VERSION ""

NS_ :

BS_:

BU_: Turbocharger OnBoardDataLogger OffBoardDiagnosticTool2 OffBoardDiagnosticTool1 FileServer ParkingBrakeController SeatControl2 FanDriveController SteeringColumnUnit CommunicationUnitRadio CommunicationUnitSatellite CommunicationUnitCellular PropulsionBatteryCharger ChassisController2 ChassisController1 EngineValveControl AuxiliaryHeater2 AuxiliaryHeater1 ClutchUnit RampControl InformationSystem1 SuspensionSystemController2 OilSensor VehicleDynamicStability ExhaustEmissionController TransmissionDisplay2 TransmissionDisplay1 ClimateControl2 WaterPumpController RearAxleSteeringController LightingOperatorControl SeatController1 IgnitionController2 IgnitionController1 TirePressureController CabController2 CabController1 PneumaticSystemController SuspensionSystemController1 HydraulicPumpController EnduranceBrakingSystem RetarderExhaustEngine2 OnBoardDiagnosticUnit HeadwayController RetarderExhaustEngine1 CabDisplay1 ManagementComputer VirtualTerminal OffVehicleGateway PowerTakeOffFront HitchControl AuxiliaryValveControl BodyController TractorTrailerBridge1 StarterSystem ElectricalSystem VehicleSecurity VehicleNavigation AerodynamicControl ElectricalChargingSystem ClimateControl1 TripRecorder InstrumentCluster SuspensionDriveAxle2 SuspensionDriveAxle1 SuspensionSteerAxle SteeringController FuelSystem CruiseControl RetarderDriveline RetarderEngine BrakesDriveAxle2 BrakesDriveAxle1 BrakesSystemController BrakesSteerAxle AxleDrive2 AxleDrive1 AxleSteering PowerTakeOff ShiftConsoleSecondary ShiftConsolePrimary Transmission2 Transmission1 Engine2 Engine1

BO_ 2362179326 PD: 14 Vector__XXX
 SG_ NumberOfControlChannels m1 : 56|8@1+ (1,0) [0|255] "" Vector__XXX
 SG_ Command M : 0|4@1+ (1,0) [0|15] "" Vector__XXX
 SG_ ErrorElementNumber m13 : 4|12@1+ (1,0) [0|4095] "" Vector__XXX
 SG_ ElementNumber m2 : 4|12@1+ (1,0) [0|4095] "" Vector__XXX
 SG_ DeviceDescriptionMsgType m1M : 4|4@1+ (1,0) [0|15] "" Vector__XXX
 SG_ TechnicalDataMsgType m0M : 4|4@1+ (1,0) [0|15] "" Vector__XXX
 SG_ ErrorCodeObjPoolActiveResp1 m9 : 8|1@1+ (1,0) [0|0] "" Vector__XXX
 SG_ ObjectIdChanged m13 : 8|16@1+ (1,0) [0|65535] "" Vector__XXX
 SG_ ObjectIdToChange m12 : 8|16@1+ (1,0) [0|65535] "" Vector__XXX
 SG_ ErrorCodeObjectPoolDelete m11 : 8|8@1+ (1,0) [0|0] "" Vector__XXX
 SG_ ActivateDeactivateCommand m8 : 8|8@1+ (1,0) [0|255] "" Vector__XXX
 SG_ ErrorCodeObjPoolTransfer m7 : 8|8@1+ (1,0) [0|3] "" Vector__XXX
 SG_ Status m5 : 8|8@1+ (1,0) [0|1] "" Vector__XXX
 SG_ RequestTransferDataSize m4 : 8|32@1+ (1,0) [0|4294967295] "bytes" Vector__XXX
 SG_ VersionNumberISO11783Part10 m1 : 8|8@1- (1,0) [0|255] "" Vector__XXX
 SG_ StructureLabel m0 : 8|56@1+ (1,0) [0|0] "" Vector__XXX
 SG_ ErrorCodeObjPoolActiveResp2 m9 : 9|1@1+ (1,0) [0|0] "" Vector__XXX
 SG_ ErrorCodeObjPoolActiveResp3 m9 : 10|1@1+ (1,0) [0|0] "" Vector__XXX
 SG_ LanguageCodeCmd m3 : 15|16@0+ (1,0) [0|16383] "" Vector__XXX
 SG_ PeerControlDDI m9 : 16|16@1+ (1,0) [0|65535] "" Vector__XXX
 SG_ BootTimeTC m1 : 16|8@1+ (1,0) [0|255] "s" Vector__XXX
 SG_ DDI m2M : 16|16@1+ (1,0) [0|65535] "" Vector__XXX
 SG_ ReceivedDataSize m7 : 16|32@1+ (1,0) [0|4294967295] "bytes" Vector__XXX
 SG_ ParentObjectIdOfFaultyObject m9 : 16|16@1+ (1,0) [0|65535] "" Vector__XXX
 SG_ ErrorDDI m13 : 16|16@1+ (1,0) [0|65535] "" Vector__XXX
 SG_ DDI_DI m5 : 16|16@1+ (1,0) [0|65535] "" Vector__XXX
 SG_ DDI_TI m4 : 16|16@1+ (1,0) [0|65535] "" Vector__XXX
 SG_ DesignatorLength m12 : 24|8@1+ (1,0) [0|255] "bytes" Vector__XXX
 SG_ ErrorCodeChangeDesignator m13 : 24|8@1+ (1,0) [0|0] "" Vector__XXX
 SG_ Documentation m1 : 24|1@1+ (1,0) [0|1] "" Vector__XXX
 SG_ TimeAndPositionForDataLogging m1 : 25|1@1+ (1,0) [0|1] "" Vector__XXX
 SG_ TC_GEO_DefinitionPositionBasedCo m1 : 26|1@1+ (1,0) [0|1] "" Vector__XXX
 SG_ PeerControlAssignment m1 : 27|1@1+ (1,0) [0|1] "" Vector__XXX
 SG_ ImplementSectionControl m1 : 28|1@1+ (1,0) [0|1] "" Vector__XXX
 SG_ TimeFormatCmd m3 : 28|2@1+ (1,0) [0|3] "" Vector__XXX
 SG_ DecimalSymbolCmd m3 : 30|2@1+ (1,0) [0|3] "" Vector__XXX
 SG_ PeerControlCommand m9M : 32|4@1+ (1,0) [0|5] "" Vector__XXX
 SG_ DataDictionaryVersion m0 : 32|32@1- (1,0) [0|21474800] "" Vector__XXX
 SG_ DateFormatCmd m3 : 32|8@1+ (1,0) [0|255] "" Vector__XXX
 SG_ Status_TotalsActive m15 : 32|1@1+ (1,0) [0|1] "" Vector__XXX
 SG_ StatusTotalsActive m14 : 32|1@1+ (1,0) [0|1] "" Vector__XXX
 SG_ ErrorCodeProcessData1 m13 : 32|1@1+ (1,0) [0|1] "" Vector__XXX
 SG_ ObjectIdOfFaultyObject m9 : 32|16@1+ (1,0) [0|65535] "" Vector__XXX
 SG_ RequestDefaultProcessData m57343 : 32|32@1- (1,0) [0|0] "" Vector__XXX
 SG_ PGNBasedData m57342 : 32|32@1- (1,0) [-2147483648|2147483647] "" Vector__XXX
 SG_ LastUnloadedWeight m321 : 32|32@1- (1,0) [0|2147483647] "g" Vector__XXX
 SG_ LastLoadedWeight m320 : 32|32@1- (1,0) [0|2147483647] "g" Vector__XXX
 SG_ IneffectiveTotalDieselExhaustFlu m319 : 32|32@1- (1,0) [0|2147483647] "ml" Vector__XXX
 SG_ EffectiveTotalDieselExhaustFluid m318 : 32|32@1- (1,0) [0|2147483647] "ml" Vector__XXX
 SG_ IneffectiveTotalFuelConsumption m317 : 32|32@1- (1,0) [0|2147483647] "ml" Vector__XXX
 SG_ EffectiveTotalFuelConsumption m316 : 32|32@1- (1,0) [0|2147483647] "ml" Vector__XXX
 SG_ AveragePercentageCropDryMatter m315 : 32|32@1- (1,0) [0|2147483647] "ppm" Vector__XXX
 SG_ ActualPercentageCropDryMatter m314 : 32|32@1- (1,0) [0|2147483647] "ppm" Vector__XXX
 SG_ MaximumRelativeYieldPotential m313 : 32|32@1- (1,0) [0|2147483647] "ppm" Vector__XXX
 SG_ MinimumRelativeYieldPotential m312 : 32|32@1- (1,0) [0|2147483647] "ppm" Vector__XXX
 SG_ RelativeYieldPotential m311 : 32|32@1- (1,0) [0|2147483647] "ppm" Vector__XXX
 SG_ MaximumPercentageApplicationRate m310 : 32|32@1- (1,0) [0|2147483647] "ppm" Vector__XXX
 SG_ MinimumPercentageApplicationRate m309 : 32|32@1- (1,0) [0|2147483647] "ppm" Vector__XXX
 SG_ ActualPercentageApplicationRate m308 : 32|32@1- (1,0) [0|2147483647] "ppm" Vector__XXX
 SG_ TrueRotationPointYOffset m307 : 32|32@1- (1,0) [-2147483648|2147483647] "mm" Vector__XXX
 SG_ TrueRotationPointXOffset m306 : 32|32@1- (1,0) [-2147483648|2147483647] "mm" Vector__XXX
 SG_ SetpointCondensedWorkState241to2 m305 : 32|32@1+ (1,0) [0|4294967295] "" Vector__XXX
 SG_ SetpointCondensedWorkState225to2 m304 : 32|32@1+ (1,0) [0|4294967295] "" Vector__XXX
 SG_ SetpointCondensedWorkState209to2 m303 : 32|32@1+ (1,0) [0|4294967295] "" Vector__XXX
 SG_ SetpointCondensedWorkState193to2 m302 : 32|32@1+ (1,0) [0|4294967295] "" Vector__XXX
 SG_ SetpointCondensedWorkState177to1 m301 : 32|32@1+ (1,0) [0|4294967295] "" Vector__XXX
 SG_ SetpointCondensedWorkState161to1 m300 : 32|32@1+ (1,0) [0|4294967295] "" Vector__XXX
 SG_ SetpointCondensedWorkState145to1 m299 : 32|32@1+ (1,0) [0|4294967295] "" Vector__XXX
 SG_ SetpointCondensedWorkState129to1 m298 : 32|32@1+ (1,0) [0|4294967295] "" Vector__XXX
 SG_ SetpointCondensedWorkState113to1 m297 : 32|32@1+ (1,0) [0|4294967295] "" Vector__XXX
 SG_ SetpointCondensedWorkState97to11 m296 : 32|32@1+ (1,0) [0|4294967295] "" Vector__XXX
 SG_ SetpointCondensedWorkState81to96 m295 : 32|32@1+ (1,0) [0|4294967295] "" Vector__XXX
 SG_ SetpointCondensedWorkState65to80 m294 : 32|32@1+ (1,0) [0|4294967295] "" Vector__XXX
 SG_ SetpointCondensedWorkState49to64 m293 : 32|32@1+ (1,0) [0|4294967295] "" Vector__XXX
 SG_ SetpointCondensedWorkState33to48 m292 : 32|32@1+ (1,0) [0|4294967295] "" Vector__XXX
 SG_ SetpointCondensedWorkState17to32 m291 : 32|32@1+ (1,0) [0|4294967295] "" Vector__XXX
 SG_ SetpointCondensedWorkState1to16 m290 : 32|32@1+ (1,0) [0|4294967295] "" Vector__XXX
 SG_ SetpointWorkState m289 : 32|32@1- (1,0) [0|3] "" Vector__XXX
 SG_ LifetimeUncutTotalCount m286 : 32|32@1- (1,0) [0|2147483647] "" Vector__XXX
 SG_ LifetimePrecutTotalCount m285 : 32|32@1- (1,0) [0|2147483647] "" Vector__XXX
 SG_ UncutTotalCount m284 : 32|32@1- (1,0) [0|2147483647] "" Vector__XXX
 SG_ PrecutTotalCount m283 : 32|32@1- (1,0) [0|2147483647] "" Vector__XXX
 SG_ LifetimeThreshingEngagementTotal m282 : 32|32@1- (1,0) [0|2147483647] "s" Vector__XXX
 SG_ LifetimeYieldTotalLintCottonMass m281 : 32|32@1- (1,0) [0|2147483647] "kg" Vector__XXX
 SG_ LifetimeYieldTotalSeedCottonMass m280 : 32|32@1- (1,0) [0|2147483647] "" Vector__XXX
 SG_ LifetimeYieldTotalDryMass m279 : 32|32@1- (1,0) [0|2147483647] "kg" Vector__XXX
 SG_ LifetimeAverageFuelConsumptionPe m278 : 32|32@1- (1,0) [0|2147483647] "mm³/m²" Vector__XXX
 SG_ LifetimeAverageFuelConsumpt_0000 m277 : 32|32@1- (1,0) [0|2147483647] "mm³/s" Vector__XXX
 SG_ LifetimeFuelConsumption m276 : 32|32@1- (0.5,0) [0|2147483647] "L" Vector__XXX
 SG_ LifetimeIneffectiveTotalTime m275 : 32|32@1- (1,0) [0|2147483647] "s" Vector__XXX
 SG_ LifetimeEffectiveTotalTime m274 : 32|32@1- (1,0) [0|2147483647] "s" Vector__XXX
 SG_ LifetimeIneffectiveTotalDistance m273 : 32|32@1- (1,0) [0|2147483647] "m" Vector__XXX
 SG_ LifetimeTotalDistance m272 : 32|32@1- (1,0) [0|2147483647] "m" Vector__XXX
 SG_ LifetimeTotalArea m271 : 32|32@1- (1,0) [0|2147483647] "m²" Vector__XXX
 SG_ LifetimeYieldTotalCount m270 : 32|32@1- (1,0) [0|2147483647] "" Vector__XXX
 SG_ LifetimeYieldTotalMass m269 : 32|32@1- (1,0) [0|2147483647] "kg" Vector__XXX
 SG_ LifetimeYieldTotalVolume m268 : 32|32@1- (1,0) [0|2147483647] "L" Vector__XXX
 SG_ LifetimeApplicationTotalCount m267 : 32|32@1- (1,0) [0|2147483647] "" Vector__XXX
 SG_ LifetimeApplicationTotalMass m266 : 32|32@1- (1,0) [0|2147483647] "kg" Vector__XXX
 SG_ RemainingArea m265 : 32|32@1- (1,0) [0|2147483647] "m²" Vector__XXX
 SG_ ConnectorPivotXOffset m264 : 32|32@1- (1,0) [-2147483648|2147483647] "mm" Vector__XXX
 SG_ AverageYieldMassPerArea m263 : 32|32@1- (1,0) [0|2147483647] "mg/m²" Vector__XXX
 SG_ AverageCropMoisture m262 : 32|32@1- (1,0) [0|2147483647] "ppm" Vector__XXX
 SG_ AverageYieldMassPerTime m261 : 32|32@1- (1,0) [0|2147483647] "mg/s" Vector__XXX
 SG_ YieldLeadIgnoreTime m260 : 32|32@1- (1,0) [0|2147483647] "ms" Vector__XXX
 SG_ YieldLagIgnoreTime m259 : 32|32@1- (1,0) [0|2147483647] "ms" Vector__XXX
 SG_ HydraulicOilTemperature m258 : 32|32@1- (1,0) [0|2000000] "mK" Vector__XXX
 SG_ MaximumSeparationFanRotationalSp m257 : 32|32@1- (0.001,0) [0|2147483647] "1/s" Vector__XXX
 SG_ MinimumSeparationFanRotationalSp m256 : 32|32@1- (0.001,0) [0|2147483647] "1/s" Vector__XXX
 SG_ ActualSeparationFanRotationalSpe m255 : 32|32@1- (0.001,0) [0|2147483647] "1/s" Vector__XXX
 SG_ SetpointSeparationFanRotationalS m254 : 32|32@1- (0.001,0) [0|2147483647] "1/s" Vector__XXX
 SG_ MaximumConcaveClearance m253 : 32|32@1- (1,0) [0|2147483647] "mm" Vector__XXX
 SG_ MinimumConcaveClearance m252 : 32|32@1- (1,0) [0|2147483647] "mm" Vector__XXX
 SG_ ActualConcaveClearance m251 : 32|32@1- (1,0) [0|2147483647] "mm" Vector__XXX
 SG_ SetpointConcaveClearance m250 : 32|32@1- (1,0) [0|2147483647] "mm" Vector__XXX
 SG_ MaximumChafferClearance m249 : 32|32@1- (1,0) [0|2147483647] "mm" Vector__XXX
 SG_ MinimumChafferClearance m248 : 32|32@1- (1,0) [0|2147483647] "mm" Vector__XXX
 SG_ ActualChafferClearance m247 : 32|32@1- (1,0) [0|2147483647] "mm" Vector__XXX
 SG_ SetpointChafferClearance m246 : 32|32@1- (1,0) [0|2147483647] "mm" Vector__XXX
 SG_ MaximumSieveClearance m245 : 32|32@1- (1,0) [0|2147483647] "mm" Vector__XXX
 SG_ MinimumSieveClearance m244 : 32|32@1- (1,0) [0|2147483647] "mm" Vector__XXX
 SG_ ActualSieveClearance m243 : 32|32@1- (1,0) [0|2147483647] "mm" Vector__XXX
 SG_ SetpointSieveClearance m242 : 32|32@1- (1,0) [0|2147483647] "mm" Vector__XXX
 SG_ CropTemperature m241 : 32|32@1- (1,0) [0|1000000] "mK" Vector__XXX
 SG_ ActualUnLoadingSystemStatus m240 : 32|32@1- (1,0) [0|771] "" Vector__XXX
 SG_ YieldHoldStatus m239 : 32|32@1- (1,0) [0|3] "" Vector__XXX
 SG_ ActualHeaderRotationalSpeedStatu m238 : 32|32@1- (1,0) [0|3] "" Vector__XXX
 SG_ ActualHeaderWorkingHeightStatus m237 : 32|32@1- (1,0) [0|3] "" Vector__XXX
 SG_ ThreshingEngagementTotalTime m236 : 32|32@1- (1,0) [0|2147483647] "s" Vector__XXX
 SG_ MaximumGrossWeight m235 : 32|32@1- (1,0) [-2147483648|2147483647] "g" Vector__XXX
 SG_ MinimumGrossWeight m234 : 32|32@1- (1,0) [-2147483648|2147483647] "g" Vector__XXX
 SG_ GrossWeightState m233 : 32|32@1- (1,0) [0|3] "" Vector__XXX
 SG_ ActualGrossWeight m232 : 32|32@1- (1,0) [-2147483648|2147483647] "g" Vector__XXX
 SG_ SetpointNetWeight m231 : 32|32@1- (1,0) [-2147483648|2147483647] "g" Vector__XXX
 SG_ NetWeightState m230 : 32|32@1- (1,0) [0|3] "" Vector__XXX
 SG_ ActualNetWeight m229 : 32|32@1- (1,0) [-2147483648|2147483647] "g" Vector__XXX
 SG_ MaximumWorkingLength m228 : 32|32@1- (1,0) [-2147483648|2147483647] "mm" Vector__XXX
 SG_ MinimumWorkingLength m227 : 32|32@1- (1,0) [-2147483648|2147483647] "mm" Vector__XXX
 SG_ ActualWorkingLength m226 : 32|32@1- (1,0) [-2147483648|2147483647] "mm" Vector__XXX
 SG_ SetpointWorkingLength m225 : 32|32@1- (1,0) [-2147483648|2147483647] "mm" Vector__XXX
 SG_ DeltaT m224 : 32|32@1- (1,0) [0|1000000] "mK" Vector__XXX
 SG_ LastBaleMass m223 : 32|32@1- (1,0) [0|2147483647] "g" Vector__XXX
 SG_ LastBaleTagNumber m222 : 32|32@1- (1,0) [0|2147483647] "" Vector__XXX
 SG_ LastBaleAppliedPreservative m221 : 32|32@1- (1,0) [0|2147483647] "ml" Vector__XXX
 SG_ LastBaleAverageBaleCompressionPl m220 : 32|32@1- (1,0) [0|2000] "" Vector__XXX
 SG_ ActualBaleCompressionPlungerLoad m219 : 32|32@1- (1,0) [0|2000] "" Vector__XXX
 SG_ SetpointBaleCompressionPlungerLo m218 : 32|32@1- (1,0) [0|2000] "" Vector__XXX
 SG_ LastBaleAverageHydraulicPressure m217 : 32|32@1- (1,0) [0|2147483647] "Pa" Vector__XXX
 SG_ ActualBaleHydraulicPressure m216 : 32|32@1- (1,0) [0|2147483647] "Pa" Vector__XXX
 SG_ LifetimeWorkingHours m215 : 32|32@1- (0.05,0) [0|2147483647] "h" Vector__XXX
 SG_ LifetimeBaleCount m214 : 32|32@1- (1,0) [0|2147483647] "Amount/Count" Vector__XXX
 SG_ LastBaleAverageStrokesPerFlake m213 : 32|32@1- (1,0) [0|1000] "Amount/Count" Vector__XXX
 SG_ LastBaleAverageMoisture m212 : 32|32@1- (1,0) [0|100000000] "ppm" Vector__XXX
 SG_ LastBaleFlakesPerBale m211 : 32|32@1- (1,0) [0|1000] "Amount/Count" Vector__XXX
 SG_ SkyConditions m210 : 32|32@1- (1,0) [-2147483648|2147483647] "" Vector__XXX
 SG_ AirHumidity m209 : 32|32@1- (1,0) [0|100] "%" Vector__XXX
 SG_ WindDirection m208 : 32|16@1+ (0.0001,0) [0|6.28318] "rad" Vector__XXX
 SG_ WindSpeed m207 : 32|16@1+ (0.01,0) [0|655.32] "m/s" Vector__XXX
 SG_ SCTurnOffTime m206 : 32|32@1- (1,0) [-2147483648|2147483647] "ms" Vector__XXX
 SG_ SCTurnOnTime_ m205 : 32|32@1- (1,0) [-2147483648|2147483647] "ms" Vector__XXX
 SG_ MaximumTankAgitationPressure m204 : 32|32@1- (0.1,0) [-2147483648|2147483647] "Pa" Vector__XXX
 SG_ MinimumTankAgitationPressure m203 : 32|32@1- (0.1,0) [-2147483648|2147483647] "Pa" Vector__XXX
 SG_ ActualTankAgitationPressure m202 : 32|32@1- (0.1,0) [-2147483648|2147483647] "Pa" Vector__XXX
 SG_ SetpointTankAgitationPressure m201 : 32|32@1- (0.1,0) [-2147483648|2147483647] "Pa" Vector__XXX
 SG_ MaximumPumpOutputPressure m200 : 32|32@1- (0.1,0) [-2147483648|2147483647] "Pa" Vector__XXX
 SG_ MinimumPumpOutputPressure m199 : 32|32@1- (0.1,0) [-2147483648|2147483647] "Pa" Vector__XXX
 SG_ ActualPumpOutputPressure m198 : 32|32@1- (0.1,0) [-2147483648|2147483647] "Pa" Vector__XXX
 SG_ SetpointPumpOutputPressure m197 : 32|32@1- (0.1,0) [-2147483648|2147483647] "Pa" Vector__XXX
 SG_ MaximumProductPressure m196 : 32|32@1- (0.1,0) [-2147483648|2147483647] "Pa" Vector__XXX
 SG_ MinimumProductPressure m195 : 32|32@1- (0.1,0) [-2147483648|2147483647] "Pa" Vector__XXX
 SG_ ActualProductPressure m194 : 32|32@1- (0.1,0) [-2147483648|2147483647] "Pa" Vector__XXX
 SG_ SetpointProductPressure m193 : 32|32@1- (0.1,0) [-2147483648|2147483647] "Pa" Vector__XXX
 SG_ AmbientTemperature m192 : 32|32@1- (1,0) [0|1000000] "mK" Vector__XXX
 SG_ LintTurnoutPercentage m191 : 32|32@1- (1,0) [0|2147483647] "ppm" Vector__XXX
 SG_ YieldTotalLintCottonMass m190 : 32|32@1- (1,0) [0|2147483647] "kg" Vector__XXX
 SG_ YieldTotalSeedCottonMass m189 : 32|32@1- (1,0) [0|2147483647] "" Vector__XXX
 SG_ LintCottonMassPerTimeYield m188 : 32|32@1- (1,0) [0|2147483647] "mg/s" Vector__XXX
 SG_ SeedCottonMassPerTimeYield m187 : 32|32@1- (1,0) [0|2147483647] "mg/s" Vector__XXX
 SG_ LintCottonMassPerAreaYield m186 : 32|32@1- (1,0) [0|2147483647] "mg/m²" Vector__XXX
 SG_ SeedCottonMassPerAreaYield m185 : 32|32@1- (1,0) [0|2147483647] "mg/m²" Vector__XXX
 SG_ RefMoistureForDryMass m184 : 32|32@1- (1,0) [0|2147483647] "ppm" Vector__XXX
 SG_ YieldTotalDryMass m183 : 32|32@1- (1,0) [0|2147483647] "kg" Vector__XXX
 SG_ DryMassPerTimeYield m182 : 32|32@1- (1,0) [0|2147483647] "mg/s" Vector__XXX
 SG_ DryMassPerAreaYield m181 : 32|32@1- (1,0) [0|2147483647] "mg/m²" Vector__XXX
 SG_ DRP2GroundDistance m180 : 32|32@1- (1,0) [-2147483648|2147483647] "mm" Vector__XXX
 SG_ ActualCulturalPractice m179 : 32|32@1- (1,0) [0|2147483647] "" Vector__XXX
 SG_ ElementTypeInstance m178 : 32|32@1- (1,0) [0|65533] "" Vector__XXX
 SG_ ActualLengthOfCut m177 : 32|32@1- (0.001,0) [0|2147483647] "mm" Vector__XXX
 SG_ CondensedWorkState241to256 m176 : 32|32@1- (1,0) [-2147483648|2147483647] "" Vector__XXX
 SG_ CondensedWorkState225to240 m175 : 32|32@1- (1,0) [-2147483648|2147483647] "" Vector__XXX
 SG_ CondensedWorkState209to224 m174 : 32|32@1- (1,0) [-2147483648|2147483647] "" Vector__XXX
 SG_ CondensedWorkState193to208 m173 : 32|32@1- (1,0) [-2147483648|2147483647] "" Vector__XXX
 SG_ CondensedWorkState177to192 m172 : 32|32@1- (1,0) [-2147483648|2147483647] "" Vector__XXX
 SG_ CondensedWorkState161to176 m171 : 32|32@1- (1,0) [-2147483648|2147483647] "" Vector__XXX
 SG_ CondensedWorkState145to160 m170 : 32|32@1- (1,0) [-2147483648|2147483647] "" Vector__XXX
 SG_ CondensedWorkState129to144 m169 : 32|32@1- (1,0) [-2147483648|2147483647] "" Vector__XXX
 SG_ CondensedWorkState113to128 m168 : 32|32@1- (1,0) [-2147483648|2147483647] "" Vector__XXX
 SG_ CondensedWorkState97to112 m167 : 32|32@1- (1,0) [-2147483648|2147483647] "" Vector__XXX
 SG_ CondensedWorkState81to96 m166 : 32|32@1- (1,0) [-2147483648|2147483647] "" Vector__XXX
 SG_ CondensedWorkState65to80 m165 : 32|32@1- (1,0) [-2147483648|2147483647] "" Vector__XXX
 SG_ CondensedWorkState49to64 m164 : 32|32@1- (1,0) [-2147483648|2147483647] "" Vector__XXX
 SG_ CondensedWorkState33to48 m163 : 32|32@1- (1,0) [-2147483648|2147483647] "" Vector__XXX
 SG_ CondensedWorkState17to32 m162 : 32|32@1- (1,0) [-2147483648|2147483647] "" Vector__XXX
 SG_ CondensedWorkState1to16 m161 : 32|32@1- (1,0) [-2147483648|2147483647] "" Vector__XXX
 SG_ SectionControlState m160 : 32|32@1- (1,0) [0|3] "" Vector__XXX
 SG_ NumberOfSubUnitsPerSection m159 : 32|32@1- (1,0) [0|2147483647] "Amount/Count" Vector__XXX
 SG_ PrescriptionControlState m158 : 32|32@1- (1,0) [0|3] "" Vector__XXX
 SG_ ConnectorType m157 : 32|32@1- (1,0) [0|7] "" Vector__XXX
 SG_ PhysicalObjectHeight m156 : 32|32@1- (1,0) [0|2147483647] "mm" Vector__XXX
 SG_ PhysicalObjectWidth m155 : 32|32@1- (1,0) [0|2147483647] "mm" Vector__XXX
 SG_ PhysicalObjectLength m154 : 32|32@1- (1,0) [0|2147483647] "mm" Vector__XXX
 SG_ NDVI m153 : 32|32@1- (1,0) [-1|1] "" Vector__XXX
 SG_ MinMassPerAreaAppRate m152 : 32|32@1- (0.01,0) [0|2147480000] "mm³/m³" Vector__XXX
 SG_ AreaPerTimeCapacity m151 : 32|32@1- (1,0) [0|2147483647] "mm²/s" Vector__XXX
 SG_ FuelConsumptionPerArea m150 : 32|32@1- (1,0) [0|2147483647] "mm³/ m²" Vector__XXX
 SG_ FuelConsumptionPerTime m149 : 32|32@1- (1,0) [0|2147483647] "mm³/s" Vector__XXX
 SG_ TotalFuelConsumption m148 : 32|32@1- (1,0) [0|2147483647] "ml" Vector__XXX
 SG_ LogCount m147 : 32|32@1- (1,0) [0|2147483647] "" Vector__XXX
 SG_ PitchAngle m146 : 32|32@1- (0.001,0) [-180|180] "°" Vector__XXX
 SG_ RollAngle m145 : 32|32@1- (0.001,0) [-180|180] "°" Vector__XXX
 SG_ YawAngle m144 : 32|32@1- (0.001,0) [-180|180] "°" Vector__XXX
 SG_ ActualValueTimeLatency m143 : 32|32@1- (1,0) [-2147483647|2147483647] "ms" Vector__XXX
 SG_ SetpointTimeLatency m142 : 32|32@1- (1,0) [-2147483647|2147483647] "ms" Vector__XXX
 SG_ WorkState m141 : 32|32@1- (1,0) [0|3] "" Vector__XXX
 SG_ PercentageAppRateSetpoint m140 : 32|32@1- (1,0) [0|2147483647] "ppm" Vector__XXX
 SG_ DeviceCountCapacity m139 : 32|32@1- (1,0) [0|2147483647] "" Vector__XXX
 SG_ DeviceMassCapacity m138 : 32|32@1- (1,0) [0|2147483647] "g" Vector__XXX
 SG_ DeviceVolumeCapacity m137 : 32|32@1- (1,0) [0|2147483647] "ml" Vector__XXX
 SG_ DeviceElementOffsetZ m136 : 32|32@1- (1,0) [-2147483647|2147483647] "mm" Vector__XXX
 SG_ DeviceElementOffsetY m135 : 32|32@1- (1,0) [-2147483647|2147483647] "mm" Vector__XXX
 SG_ DeviceElementOffsetX m134 : 32|32@1- (1,0) [-2147483647|2147483647] "mm" Vector__XXX
 SG_ AuxiliaryValveInvertPorts m133 : 32|32@1- (1,0) [-2147480000|2147480000] "" Vector__XXX
 SG_ AuxiliaryValveProgressivRetract m132 : 32|32@1- (1,0) [-2147480000|2147480000] "" Vector__XXX
 SG_ AuxiliaryValveProgressivExtend m131 : 32|32@1- (1,0) [-2147483647|2147483647] "" Vector__XXX
 SG_ AuxiliaryValveFloatThreshold m130 : 32|32@1- (0.1,0) [-214748367.9|214748367.9] "%" Vector__XXX
 SG_ AuxiliaryValveRampRetractDown m129 : 32|32@1- (1,0) [-2147483647|2147483647] "ms" Vector__XXX
 SG_ AuxiliaryValveRampRetractUp m128 : 32|32@1- (1,0) [-2147483647|2147483647] "ms" Vector__XXX
 SG_ AuxiliaryValveRampExtendDown m127 : 32|32@1- (1,0) [-2147483647|2147483647] "ms" Vector__XXX
 SG_ AuxiliaryRampExtendUp m126 : 32|32@1- (1,0) [-2147483647|2147483647] "ms" Vector__XXX
 SG_ AuxiliaryValveScalingRetract m125 : 32|32@1- (0.1,0) [-214748367.9|214748367.9] "%" Vector__XXX
 SG_ AuxiliaryValveScalingExtend m124 : 32|32@1- (0.1,0) [-214748367.9|214748367.9] "%" Vector__XXX
 SG_ PrdoucDensityVolumePerCount m123 : 32|32@1- (1,0) [0|2147483647] "ml/1000" Vector__XXX
 SG_ PrdoucDensityMassPerCount m122 : 32|32@1- (1,0) [0|2147483647] "mg/1000" Vector__XXX
 SG_ PrdoucDensityMassPerArea m121 : 32|32@1- (1,0) [0|2147483647] "g/l" Vector__XXX
 SG_ AccumulatedTimeOutWork m120 : 32|32@1- (1,0) [0|2147483647] "s" Vector__XXX
 SG_ AccumulatedTimeInWork m119 : 32|32@1- (1,0) [0|2147483647] "s" Vector__XXX
 SG_ AccumulatedDistanceOutWork m118 : 32|32@1- (1,0) [0|2147483647] "mm" Vector__XXX
 SG_ AccumulatedDistanceInWork m117 : 32|32@1- (1,0) [0|2147483647] "mm" Vector__XXX
 SG_ AccumulatedArea m116 : 32|32@1- (1,0) [0|2147483647] "m²" Vector__XXX
 SG_ BaleSize_Max m115 : 32|32@1- (1,0) [0|2147483647] "mm" Vector__XXX
 SG_ BaleSize_Min m114 : 32|32@1- (1,0) [0|2147483647] "mm" Vector__XXX
 SG_ BaleSize_Def m113 : 32|32@1- (1,0) [0|2147483647] "mm" Vector__XXX
 SG_ BaleSize_Act m112 : 32|32@1- (1,0) [0|2147483647] "mm" Vector__XXX
 SG_ BaleSize_Set m111 : 32|32@1- (1,0) [0|2147483647] "mm" Vector__XXX
 SG_ BaleHeight_Max m110 : 32|32@1- (1,0) [0|2147483647] "mm" Vector__XXX
 SG_ BaleHeight_Min m109 : 32|32@1- (1,0) [0|2147483647] "mm" Vector__XXX
 SG_ BaleHeight_Def m108 : 32|32@1- (1,0) [0|2147483647] "mm" Vector__XXX
 SG_ BaleHeight_Act m107 : 32|32@1- (1,0) [0|2147483647] "mm" Vector__XXX
 SG_ BaleHeight_Set m106 : 32|32@1- (1,0) [0|2147483647] "mm" Vector__XXX
 SG_ BaleWidth_Max m105 : 32|32@1- (1,0) [0|2147483647] "mm" Vector__XXX
 SG_ BaleWidth_Min m104 : 32|32@1- (1,0) [0|2147483647] "mm" Vector__XXX
 SG_ BaleWidth_Def m103 : 32|32@1- (1,0) [0|2147483647] "mm" Vector__XXX
 SG_ BaleWidth_Act m102 : 32|32@1- (1,0) [0|2147483647] "mm" Vector__XXX
 SG_ BaleWidth_Set m101 : 32|32@1- (1,0) [0|2147483647] "mm" Vector__XXX
 SG_ DirtMaterialInCropYield m100 : 32|32@1- (1,0) [0|2147483647] "ppm" Vector__XXX
 SG_ MoistureInCropYield m99 : 32|32@1- (1,0) [0|2147483647] "ppm" Vector__XXX
 SG_ CropYieldLoss m98 : 32|32@1- (1,0) [0|2147483647] "ppm" Vector__XXX
 SG_ CropYieldLossCountPerTime m97 : 32|32@1- (0.001,0) [0|2147483.647] "1/s" Vector__XXX
 SG_ CropYieldLossMassPerTime m96 : 32|32@1- (1,0) [0|2147483647] "mg/s" Vector__XXX
 SG_ CropYieldLossVolumePerTime m95 : 32|32@1- (1,0) [0|2147483647] "ml/s" Vector__XXX
 SG_ CropYieldLossCountPerArea m94 : 32|32@1- (0.001,0) [0|2147483.647] "1/m²" Vector__XXX
 SG_ CropYieldLossMassPerArea m93 : 32|32@1- (1,0) [0|2147483647] "mg/m²" Vector__XXX
 SG_ CropYieldLossVolumePerArea m92 : 32|32@1- (1,0) [0|2147483647] "ml/m²" Vector__XXX
 SG_ AccumulatedYieldAsCount m91 : 32|32@1- (1,0) [0|2147483647] "" Vector__XXX
 SG_ AccumulatedYieldAsMass m90 : 32|32@1- (1,0) [0|2147483647] "g" Vector__XXX
 SG_ AccumulatedYieldAsVolume m89 : 32|32@1- (1,0) [0|2147483647] "ml" Vector__XXX
 SG_ YieldCountPerTime m88 : 32|32@1- (0.001,0) [0|2147483.647] "1/s" Vector__XXX
 SG_ YieldMassPerTime m87 : 32|32@1- (1,0) [0|2147483647] "mg/s" Vector__XXX
 SG_ YieldVolumePerTime m86 : 32|32@1- (1,0) [0|2147483647] "ml/s" Vector__XXX
 SG_ YieldCountPerArea m85 : 32|32@1- (0.001,0) [0|2147483.647] "1/m²" Vector__XXX
 SG_ YieldMassPerArea m84 : 32|32@1- (1,0) [0|2147483647] "mg/m²" Vector__XXX
 SG_ YieldVolumePerArea m83 : 32|32@1- (1,0) [0|2147483647] "ml/m²" Vector__XXX
 SG_ AccumulatedAppAsCount m82 : 32|32@1- (1,0) [0|2147483647] "" Vector__XXX
 SG_ AccumulatedAppAsMass m81 : 32|32@1- (1,0) [0|2147483647] "kg" Vector__XXX
 SG_ AccumulatedAppAsVolume m80 : 32|32@1- (1,0) [0|2147483647] "l" Vector__XXX
 SG_ ContentAsCount_Max m79 : 32|32@1- (1,0) [0|2147483647] "" Vector__XXX
 SG_ ContentAsCount_Act m78 : 32|32@1- (1,0) [0|2147483647] "" Vector__XXX
 SG_ ContentAsCount_Set m77 : 32|32@1- (1,0) [0|2147483647] "" Vector__XXX
 SG_ ContentAsMass_Max m76 : 32|32@1- (1,0) [0|2147483647] "g" Vector__XXX
 SG_ ContentAsMass_Act m75 : 32|32@1- (1,0) [0|2147483647] "g" Vector__XXX
 SG_ ContentAsMass_Set m74 : 32|32@1- (1,0) [0|2147483647] "g" Vector__XXX
 SG_ ContentAsVolume_Max m73 : 32|32@1- (1,0) [0|2147483647] "ml" Vector__XXX
 SG_ ContentAsVolume_Act m72 : 32|32@1- (1,0) [0|2147483647] "ml" Vector__XXX
 SG_ ContentAsVolume_Set m71 : 32|32@1- (1,0) [0|2147483647] "ml" Vector__XXX
 SG_ WorkingWidth_Max m70 : 32|32@1- (1,0) [0|2147483647] "mm" Vector__XXX
 SG_ WorkingWidth_Min m69 : 32|32@1- (1,0) [0|2147483647] "mm" Vector__XXX
 SG_ WorkingWidth_Def m68 : 32|32@1- (1,0) [0|2147483647] "mm" Vector__XXX
 SG_ WorkingWidth_Act m67 : 32|32@1- (1,0) [0|2147483647] "mm" Vector__XXX
 SG_ WorkingWidth_Set m66 : 32|32@1- (1,0) [0|2147483647] "mm" Vector__XXX
 SG_ WorkingHeight_Max m65 : 32|32@1- (1,0) [0|2147483647] "mm" Vector__XXX
 SG_ WorkingHeight_Min m64 : 32|32@1- (1,0) [0|2147483647] "mm" Vector__XXX
 SG_ WorkingHeight_Def m63 : 32|32@1- (1,0) [0|2147483647] "mm" Vector__XXX
 SG_ WorkingHeight_Act m62 : 32|32@1- (1,0) [0|2147483647] "mm" Vector__XXX
 SG_ WorkingHeight_Set m61 : 32|32@1- (1,0) [0|2147483647] "mm" Vector__XXX
 SG_ SeedingDeph_Max m60 : 32|32@1- (1,0) [0|2147483647] "mm" Vector__XXX
 SG_ SeedingDeph_Min m59 : 32|32@1- (1,0) [0|2147483647] "mm" Vector__XXX
 SG_ SeedingDeph_Def m58 : 32|32@1- (1,0) [0|2147483647] "mm" Vector__XXX
 SG_ SeedingDeph_Act m57 : 32|32@1- (1,0) [0|2147483647] "mm" Vector__XXX
 SG_ SeedingDeph_Set m56 : 32|32@1- (1,0) [0|2147483647] "mm" Vector__XXX
 SG_ TillageDepth_Max m55 : 32|32@1- (1,0) [0|2147483647] "mm" Vector__XXX
 SG_ TillageDepth_Min m54 : 32|32@1- (1,0) [0|2147483647] "mm" Vector__XXX
 SG_ TillageDepth_Def m53 : 32|32@1- (1,0) [0|2147483647] "mm" Vector__XXX
 SG_ TillageDepth_Act m52 : 32|32@1- (1,0) [0|2147483647] "mm" Vector__XXX
 SG_ SetTillageDepth_Set m51 : 32|32@1- (1,0) [0|2147483647] "mm" Vector__XXX
 SG_ AppRateCountPerTime_Max m50 : 32|32@1- (0.001,0) [0|2147483.647] "1/s" Vector__XXX
 SG_ AppRateCountPerTime_Min m49 : 32|32@1- (0.001,0) [0|2147483.647] "1/s" Vector__XXX
 SG_ AppRateCountPerTime_Def m48 : 32|32@1- (0.001,0) [0|2147483.647] "1/s" Vector__XXX
 SG_ AppRateCountPerTime_Act m47 : 32|32@1- (0.001,0) [0|2147483.647] "1/s" Vector__XXX
 SG_ AppRateCountPerTime_Set m46 : 32|32@1- (0.001,0) [0|2147483.647] "1/s" Vector__XXX
 SG_ AppRateMassPerTime_Max m45 : 32|32@1- (1,0) [0|2147483647] "mg/s" Vector__XXX
 SG_ AppRateMassPerTime_Min m44 : 32|32@1- (1,0) [0|2147483647] "mg/s" Vector__XXX
 SG_ AppRateMassPerTime_Def m43 : 32|32@1- (1,0) [0|2147483647] "mg/s" Vector__XXX
 SG_ AppRateMassPerTime_Act m42 : 32|32@1- (1,0) [0|2147483647] "mg/s" Vector__XXX
 SG_ AppRateMassPerTime_Set m41 : 32|32@1- (1,0) [0|2147483647] "mg/s" Vector__XXX
 SG_ AppRateVolumePerTime_Max m40 : 32|32@1- (1,0) [0|2147483647] "mm³/s" Vector__XXX
 SG_ AppRateVolumePerTime_Min m39 : 32|32@1- (1,0) [0|2147483647] "mm³/s" Vector__XXX
 SG_ AppRateVolumePerTime_Def m38 : 32|32@1- (1,0) [0|2147483647] "mm³/s" Vector__XXX
 SG_ AppRateVolumePerTime_Act m37 : 32|32@1- (1,0) [0|2147483647] "mm³/s" Vector__XXX
 SG_ AppRateVolumePerTime_Set m36 : 32|32@1- (1,0) [0|2147483647] "mm³/s" Vector__XXX
 SG_ AppRateVolumePerMass_Max m35 : 32|32@1- (1,0) [0|2147483647] "mm³/kg" Vector__XXX
 SG_ AppRateVolumePerMass_Min m34 : 32|32@1- (1,0) [0|2147483647] "mm³/kg" Vector__XXX
 SG_ AppRateVolumePerMass_Def m33 : 32|32@1- (1,0) [0|2147483647] "mm³/kg" Vector__XXX
 SG_ AppRateVolumePerMass_Act m32 : 32|32@1- (1,0) [0|2147483647] "mm³/kg" Vector__XXX
 SG_ AppRateVolumePerMass_Set m31 : 32|32@1- (1,0) [0|2147483647] "mm³/kg" Vector__XXX
 SG_ AppRateMassPerMass_Max m30 : 32|32@1- (1,0) [0|2147483647] "mg/kg" Vector__XXX
 SG_ AppRateMassPerMass_Min m29 : 32|32@1- (1,0) [0|2147483647] "mg/kg" Vector__XXX
 SG_ AppRateMassPerMass_Def m28 : 32|32@1- (1,0) [0|2147483647] "mg/kg" Vector__XXX
 SG_ AppRateMassPerMass_Act m27 : 32|32@1- (1,0) [0|2147483647] "mg/kg" Vector__XXX
 SG_ AppRateMassPerMass_Set m26 : 32|32@1- (1,0) [0|2147483647] "mg/kg" Vector__XXX
 SG_ AppRateVolumePerVolume_Max m25 : 32|32@1- (1,0) [0|2147483647] "mm³/m³" Vector__XXX
 SG_ AppRateVolumePerVolume_Min m24 : 32|32@1- (1,0) [0|2147483647] "mm³/m³" Vector__XXX
 SG_ AppRateVolumePerVolume_Def m23 : 32|32@1- (1,0) [0|2147483647] "mm³/m³" Vector__XXX
 SG_ AppRateVolumePerVolume_Act m22 : 32|32@1- (1,0) [0|2147483647] "mm³/m³" Vector__XXX
 SG_ AppRateVolumePerVolume_Set m21 : 32|32@1- (1,0) [0|2147483647] "mm³/m³" Vector__XXX
 SG_ AppRateDistance_Max m20 : 32|32@1- (1,0) [0|2147483647] "mm" Vector__XXX
 SG_ AppRateDistance_Min m19 : 32|32@1- (1,0) [0|2147483647] "mm" Vector__XXX
 SG_ AppRateDistance_Def m18 : 32|32@1- (1,0) [0|2147483647] "mm" Vector__XXX
 SG_ AppRateDistance_Act m17 : 32|32@1- (1,0) [0|2147483647] "mm" Vector__XXX
 SG_ SetAppRateDistance_Set m16 : 32|32@1- (1,0) [0|2147483647] "mm" Vector__XXX
 SG_ AppRateCountPerArea_Max m15 : 32|32@1- (0.001,0) [0|2147483.647] "1/m²" Vector__XXX
 SG_ AppRateCountPerArea_Min m14 : 32|32@1- (0.001,0) [0|2147483.647] "1/m²" Vector__XXX
 SG_ AppRateCountPerArea_Def m13 : 32|32@1- (0.001,0) [0|2147483.647] "1/m²" Vector__XXX
 SG_ AppRateCountPerArea_Act m12 : 32|32@1- (0.001,0) [0|2147483.647] "1/m²" Vector__XXX
 SG_ AppRateCountPerArea_Set m11 : 32|32@1- (0.001,0) [0|2147483.647] "1/m²" Vector__XXX
 SG_ AppRateMassPerArea_Max m10 : 32|32@1- (1,0) [0|2147483647] "mg/m²" Vector__XXX
 SG_ AppRateMassPerArea_Min m9 : 32|32@1- (1,0) [0|2147483647] "mg/m²" Vector__XXX
 SG_ AppRateMassPerArea_Def m8 : 32|32@1- (1,0) [0|2147483647] "mg/m²" Vector__XXX
 SG_ AppRateMassPerArea_Act m7 : 32|32@1- (1,0) [0|2147483647] "mg/m²" Vector__XXX
 SG_ AppRateMassPerArea_Set m6 : 32|32@1- (1,0) [0|2147483647] "mg/m²" Vector__XXX
 SG_ AppRateVolumePerArea_Max m5 : 32|32@1- (0.01,0) [0|21474836.47] "mm³/m²" Vector__XXX
 SG_ AppRateVolumePerArea_Min m4 : 32|32@1- (0.01,0) [0|21474836.47] "mm³/m²" Vector__XXX
 SG_ AppRateVolumePerArea_Def m3 : 32|32@1- (0.01,0) [0|21474836.47] "mm³/m²" Vector__XXX
 SG_ AppRateVolumePerArea_Act m2 : 32|32@1- (0.01,0) [0|21474836.47] "mm³/m²" Vector__XXX
 SG_ AppRateVolumePerArea_Set m1 : 32|32@1- (0.01,0) [0|21474836.47] "mm³/m²" Vector__XXX
 SG_ DataLogDistanceInterval m5 : 32|32@1- (1,0) [0|1000000] "mm" Vector__XXX
 SG_ DataLogTimeInterval m4 : 32|32@1- (1,0) [0|60000] "ms" Vector__XXX
 SG_ StatusBusySaving m14 : 33|1@1+ (1,0) [0|1] "" Vector__XXX
 SG_ ErrorCodeProcessData2 m13 : 33|1@1+ (1,0) [0|1] "" Vector__XXX
 SG_ StatusBusyReading m14 : 34|1@1+ (1,0) [0|1] "" Vector__XXX
 SG_ ErrorCodeProcessData3 m13 : 34|1@1+ (1,0) [0|1] "" Vector__XXX
 SG_ StatusBusyExecuting m14 : 35|1@1+ (1,0) [0|1] "" Vector__XXX
 SG_ ErrorCodeProcessData4 m13 : 35|1@1+ (1,0) [0|1] "" Vector__XXX
 SG_ ErrorCodeProcessData5 m13 : 36|1@1+ (1,0) [0|1] "" Vector__XXX
 SG_ DestinationElementNumber m3 : 36|12@1+ (1,0) [0|4095] "" Vector__XXX
 SG_ ErrorCodeProcessData6 m13 : 37|1@1+ (1,0) [0|1] "" Vector__XXX
 SG_ ErrorCodeProcessData7 m13 : 38|1@1+ (1,0) [0|1] "" Vector__XXX
 SG_ ErrorCodeProcessData8 m13 : 39|1@1+ (1,0) [0|1] "" Vector__XXX
 SG_ NumberOfBooms m1 : 40|8@1+ (1,0) [0|255] "" Vector__XXX
 SG_ MassUnitCmd m3 : 40|2@1+ (1,0) [0|3] "" Vector__XXX
 SG_ SourceAddressWSM m14 : 40|8@1+ (1,0) [0|65535] "" Vector__XXX
 SG_ VolumeUnitCmd m3 : 42|2@1+ (1,0) [0|3] "" Vector__XXX
 SG_ AreaUnitCmd m3 : 44|2@1+ (1,0) [0|3] "" Vector__XXX
 SG_ DistanceUnitCmd m3 : 46|2@1+ (1,0) [0|3] "" Vector__XXX
 SG_ ErrorCodeObjPool1 m9 : 48|1@1+ (1,0) [0|0] "" Vector__XXX
 SG_ UnitsSystem m3 : 48|2@1+ (1,0) [0|3] "" Vector__XXX
 SG_ ExecutedCommand m14 : 48|8@1+ (1,0) [0|65535] "" Vector__XXX
 SG_ NumberOfSection m1 : 48|8@1+ (1,0) [0|255] "" Vector__XXX
 SG_ IdentityNumber m0 : 48|21@1+ (1,0) [0|2097152] "" Vector__XXX
 SG_ ErrorCodeObjPool2 m9 : 49|1@1+ (1,0) [0|0] "" Vector__XXX
 SG_ ForceUnits m3 : 50|2@1+ (1,0) [0|3] "" Vector__XXX
 SG_ ErrorCodeObjPool3 m9 : 50|1@1+ (1,0) [0|0] "" Vector__XXX
 SG_ ErrorCodeObjPool4 m9 : 51|1@1+ (1,0) [0|0] "" Vector__XXX
 SG_ PressureUnits m3 : 52|2@1+ (1,0) [0|3] "" Vector__XXX
 SG_ TemperatureUnits m3 : 54|2@1+ (1,0) [0|3] "" Vector__XXX
 SG_ ManufacturerCode m0 : 69|11@1+ (1,0) [0|2047] "" Vector__XXX
 SG_ ECUInstance m0 : 80|3@1+ (1,0) [0|7] "" Vector__XXX
 SG_ FunctionInstance m0 : 83|5@1+ (1,0) [0|31] "" Vector__XXX
 SG_ Function m0 : 88|8@1+ (1,0) [0|255] "" Vector__XXX
 SG_ VehicleSystem2 m0 : 97|7@1+ (1,0) [0|127] "" Vector__XXX
 SG_ VehicleSystemInstance m0 : 104|4@1+ (1,0) [0|15] "" Vector__XXX
 SG_ IndustryGroup m0 : 108|3@1+ (1,0) [0|7] "" Vector__XXX
 SG_ ArbitraryAddressCapable m0 : 111|1@1+ (1,0) [0|1] "" Vector__XXX

BO_ 2559835902 NM: 8 Vector__XXX
 SG_ NameChecksum m0 : 0|8@1+ (1,0) [0|0] "" Vector__XXX
 SG_ ErrorCode m4 : 0|8@1+ (1,0) [0|0] "" Vector__XXX
 SG_ CommandArbitraryAddressCapable m0 : 63|1@1+ (1,0) [0|1] "" Vector__XXX
 SG_ CommandVehicleSystemInstance m0 : 56|4@1+ (1,0) [0|15] "" Vector__XXX
 SG_ CommandIndustryGroup m0 : 60|3@1+ (1,0) [0|7] "" Vector__XXX
 SG_ CommandVehicleSystem m0 : 49|7@1+ (1,0) [0|127] "" Vector__XXX
 SG_ CommandFunction m0 : 40|8@1+ (1,0) [0|255] "" Vector__XXX
 SG_ CommandFunctionInstance m0 : 35|5@1+ (1,0) [0|31] "" Vector__XXX
 SG_ CommandECUInstance m0 : 32|3@1+ (1,0) [0|7] "" Vector__XXX
 SG_ CommandManufacturerCode m0 : 21|11@1+ (1,0) [0|2047] "" Vector__XXX
 SG_ NMControlModeIndicator M : 16|4@1+ (1,0) [0|15] "" Vector__XXX
 SG_ ArbitraryAddressCapableQualifier m0 : 15|1@1+ (1,0) [0|1] "" Vector__XXX
 SG_ IndustryGroupQualifierFlag m0 : 14|1@1+ (1,0) [0|1] "" Vector__XXX
 SG_ VehicleSystemInstanceQualifierFl m0 : 13|1@1+ (1,0) [0|1] "" Vector__XXX
 SG_ VehicleSystemQualifierFlag m0 : 12|1@1+ (1,0) [0|1] "" Vector__XXX
 SG_ FunctionQualifierFlag m0 : 11|1@1+ (1,0) [0|1] "" Vector__XXX
 SG_ FunctionInstanceQualifierFlag m0 : 10|1@1+ (1,0) [0|1] "" Vector__XXX
 SG_ ECUInstanceQualifierFlag m0 : 9|1@1+ (1,0) [0|1] "" Vector__XXX
 SG_ ManufacturerCodeQualifierFlag m0 : 8|1@1+ (1,0) [0|1] "" Vector__XXX

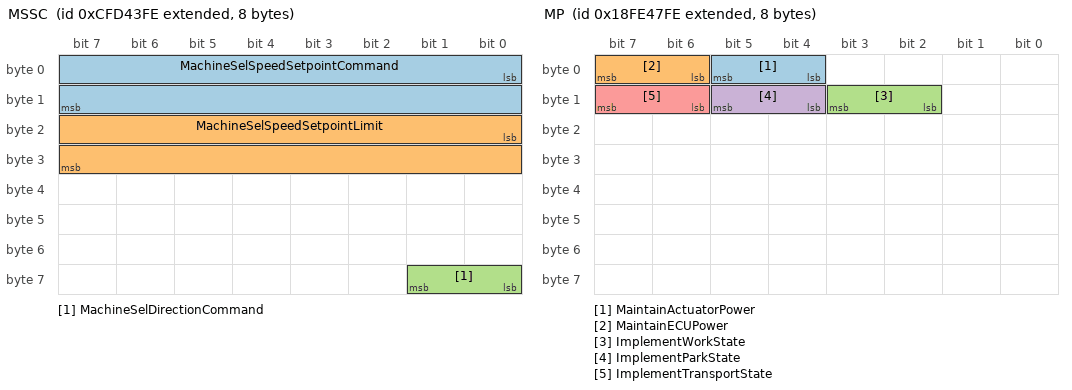
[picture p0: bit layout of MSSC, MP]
BO_ 2365408254 MSSC: 8 Vector__XXX
 SG_ MachineSelSpeedSetpointCommand : 0|16@1+ (0.001,0) [0|64255] "m/s" Vector__XXX
 SG_ MachineSelSpeedSetpointLimit : 16|16@1+ (0.001,0) [0|64255] "m/s" Vector__XXX
 SG_ MachineSelDirectionCommand : 56|2@1+ (1,0) [0|3] "" Vector__XXX

BO_ 2364547838 MSS: 9 Vector__XXX
 SG_ MachineSelectedSpeed : 0|16@1+ (0.001,0) [0|65.535] "m/s" Vector__XXX
 SG_ MachineSelectedDistance : 16|32@1+ (0.001,0) [0|4211081.215] "m" Vector__XXX
 SG_ MachineSelectedDirection : 56|2@1+ (1,0) [0|3] "" Vector__XXX
 SG_ MachineSelectedSpeedSource : 58|3@1+ (1,0) [0|7] "" Vector__XXX
 SG_ MachineSelectedSpeedLimitStatus : 61|3@1+ (1,0) [0|7] "" Vector__XXX

BO_ 2566801406 MP: 8 Vector__XXX
 SG_ MaintainActuatorPower : 4|2@1+ (1,0) [0|3] "" Vector__XXX
 SG_ MaintainECUPower : 6|2@1+ (1,0) [0|0] "" Vector__XXX
 SG_ ImplementWorkState : 10|2@1+ (1,0) [0|3] "" Vector__XXX
 SG_ ImplementParkState : 12|2@1+ (1,0) [0|3] "" Vector__XXX
 SG_ ImplementTransportState : 14|2@1+ (1,0) [0|3] "" Vector__XXX

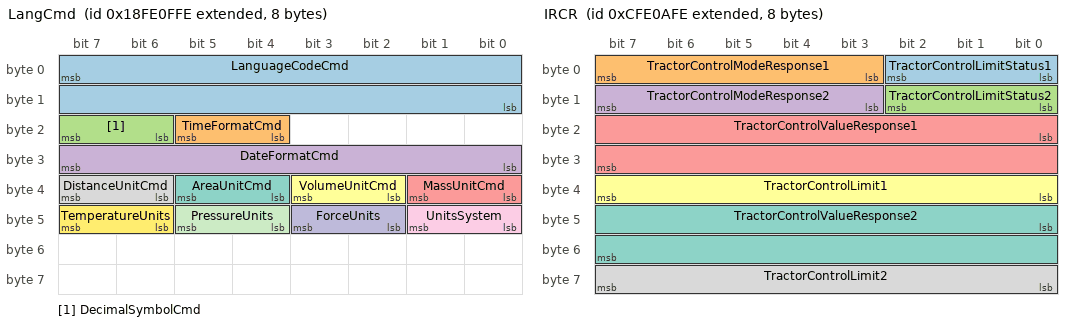
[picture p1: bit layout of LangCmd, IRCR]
BO_ 2566787070 LangCmd: 8 Vector__XXX
 SG_ LanguageCodeCmd : 7|16@0+ (1,0) [0|16383] "" Vector__XXX
 SG_ TimeFormatCmd : 20|2@1+ (1,0) [0|3] "" Vector__XXX
 SG_ DecimalSymbolCmd : 22|2@1+ (1,0) [0|3] "" Vector__XXX
 SG_ DateFormatCmd : 24|8@1+ (1,0) [0|255] "" Vector__XXX
 SG_ MassUnitCmd : 32|2@1+ (1,0) [0|3] "" Vector__XXX
 SG_ VolumeUnitCmd : 34|2@1+ (1,0) [0|3] "" Vector__XXX
 SG_ AreaUnitCmd : 36|2@1+ (1,0) [0|3] "" Vector__XXX
 SG_ DistanceUnitCmd : 38|2@1+ (1,0) [0|3] "" Vector__XXX
 SG_ UnitsSystem : 40|2@1+ (1,0) [0|3] "" Vector__XXX
 SG_ ForceUnits : 42|2@1+ (1,0) [0|3] "" Vector__XXX
 SG_ PressureUnits : 44|2@1+ (1,0) [0|3] "" Vector__XXX
 SG_ TemperatureUnits : 46|2@1+ (1,0) [0|3] "" Vector__XXX

BO_ 2365459198 IRCR: 8 Vector__XXX
 SG_ TractorControlLimitStatus1 : 0|3@1+ (1,0) [0|7] "" Vector__XXX
 SG_ TractorControlModeResponse1 : 3|5@1+ (1,0) [0|31] "" Vector__XXX
 SG_ TractorControlLimitStatus2 : 8|3@1+ (1,0) [0|7] "" Vector__XXX
 SG_ TractorControlModeResponse2 : 11|5@1+ (1,0) [0|31] "" Vector__XXX
 SG_ TractorControlValueResponse1 : 16|16@1+ (1,0) [0|0] "" Vector__XXX
 SG_ TractorControlLimit1 : 32|8@1- (1,0) [0|0] "" Vector__XXX
 SG_ TractorControlValueResponse2 : 40|16@1+ (1,0) [0|0] "" Vector__XXX
 SG_ TractorControlLimit2 : 56|8@1- (1,0) [0|0] "" Vector__XXX

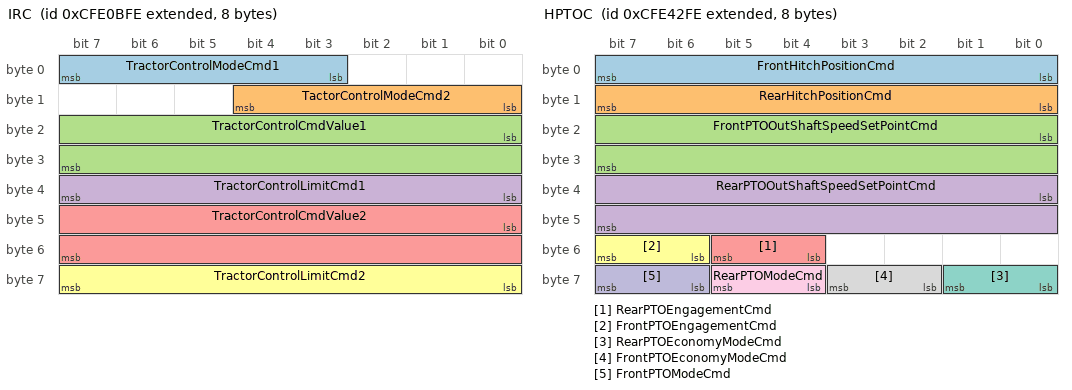
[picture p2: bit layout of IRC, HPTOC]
BO_ 2365459454 IRC: 8 Vector__XXX
 SG_ TractorControlModeCmd1 : 3|5@1+ (1,0) [0|31] "" Vector__XXX
 SG_ TactorControlModeCmd2 : 8|5@1+ (1,0) [0|31] "" Vector__XXX
 SG_ TractorControlCmdValue1 : 16|16@1+ (1,0) [0|0] "" Vector__XXX
 SG_ TractorControlLimitCmd1 : 32|8@1- (1,0) [0|0] "" Vector__XXX
 SG_ TractorControlCmdValue2 : 40|16@1+ (1,0) [0|0] "" Vector__XXX
 SG_ TractorControlLimitCmd2 : 56|8@1- (1,0) [0|0] "" Vector__XXX

BO_ 2365391616 IOS: 8 Vector__XXX
 SG_ ImplementOperatingStateCmd : 56|2@1+ (1,0) [0|3] "" Vector__XXX

BO_ 2566734590 ICC: 8 Vector__XXX
 SG_ CertTypeTCSectionControlWSMember : 41|1@1+ (1,0) [0|1] "" Vector__XXX
 SG_ CertTypeTCSectionControl : 42|1@1+ (1,0) [0|1] "" Vector__XXX
 SG_ CertTypeSeqControlMaster : 44|1@1+ (1,0) [0|1] "" Vector__XXX
 SG_ CertTypeSecControlClient : 43|1@1+ (1,0) [0|1] "" Vector__XXX
 SG_ CertTypeFileClient : 45|1@1+ (1,0) [0|1] "" Vector__XXX
 SG_ CertTypeDataLoggerWSMember : 46|1@1+ (1,0) [0|1] "" Vector__XXX
 SG_ CertTypeDataLoggerWSMaster : 47|1@1+ (1,0) [0|1] "" Vector__XXX
 SG_ CertTypeDataLogger : 32|1@1+ (1,0) [0|1] "" Vector__XXX
 SG_ CertTypeAuxControlInUnit : 34|1@1+ (1,0) [0|1] "" Vector__XXX
 SG_ CertTypeAuxControlFunc : 33|1@1+ (1,0) [0|1] "" Vector__XXX
 SG_ CertificationYear : 0|6@1+ (1,2000) [2000|2061] "year" Vector__XXX
 SG_ CertificateRevision : 6|2@1+ (1,0) [0|3] "" Vector__XXX
 SG_ CertificateLaboratoryType : 9|2@1+ (1,0) [0|3] "" Vector__XXX
 SG_ CertificationLaboratoryID : 13|11@1+ (1,0) [0|2047] "" Vector__XXX
 SG_ CertTypeVTWorkingSetMember : 24|1@1+ (1,0) [0|1] "" Vector__XXX
 SG_ CertTypeVTWorkingSetMaster : 25|1@1+ (1,0) [0|1] "" Vector__XXX
 SG_ CertTypeVirtualTerminal : 26|1@1+ (1,0) [0|1] "" Vector__XXX
 SG_ CertTypeClass3ECU : 27|1@1+ (1,0) [0|1] "" Vector__XXX
 SG_ CertTypeTECUClass3 : 28|1@1+ (1,0) [0|1] "" Vector__XXX
 SG_ CertTypeTECUClass2 : 29|1@1+ (1,0) [0|1] "" Vector__XXX
 SG_ CertTypeTECUClass1 : 30|1@1+ (1,0) [0|1] "" Vector__XXX
 SG_ CertTypeMinimumECU : 31|1@1+ (1,0) [0|1] "" Vector__XXX
 SG_ CertTypeGPSReceiver : 35|1@1+ (1,0) [0|1] "" Vector__XXX
 SG_ CertTypeFileServer : 36|1@1+ (1,0) [0|1] "" Vector__XXX
 SG_ CertTypeTCWorkingSetMember : 37|1@1+ (1,0) [0|1] "" Vector__XXX
 SG_ CertTypeTCWorkingSetMaster : 38|1@1+ (1,0) [0|1] "" Vector__XXX
 SG_ CertTypeTaskController : 39|1@1+ (1,0) [0|1] "" Vector__XXX
 SG_ CertificationReferenceNumber : 48|16@1+ (1,0) [0|65535] "" Vector__XXX

BO_ 2365473534 HPTOC: 8 Vector__XXX
 SG_ FrontHitchPositionCmd : 0|8@1+ (0.4,0) [0|100] "%" Vector__XXX
 SG_ RearHitchPositionCmd : 8|8@1+ (0.4,0) [0|100] "%" Vector__XXX
 SG_ FrontPTOOutShaftSpeedSetPointCmd : 16|16@1+ (0.125,0) [0|8031.875] "1/min" Vector__XXX
 SG_ RearPTOOutShaftSpeedSetPointCmd : 32|16@1+ (0.125,0) [0|801.875] "1/min" Vector__XXX
 SG_ RearPTOEngagementCmd : 52|2@1+ (1,0) [0|3] "" Vector__XXX
 SG_ FrontPTOEngagementCmd : 54|2@1+ (1,0) [0|3] "" Vector__XXX
 SG_ RearPTOEconomyModeCmd : 56|2@1+ (1,0) [0|3] "" Vector__XXX
 SG_ FrontPTOEconomyModeCmd : 58|2@1+ (1,0) [0|3] "" Vector__XXX
 SG_ RearPTOModeCmd : 60|2@1+ (1,0) [0|3] "" Vector__XXX
 SG_ FrontPTOModeCmd : 62|2@1+ (1,0) [0|3] "" Vector__XXX

BO_ 2360213246 GSC: 8 Vector__XXX
 SG_ CurvatureCommand : 0|16@1+ (0.25,-8032) [-8032|8031.75] "1/km" Vector__XXX
 SG_ CurvatureCommandStatus : 16|2@1+ (1,0) [0|3] "" Vector__XXX

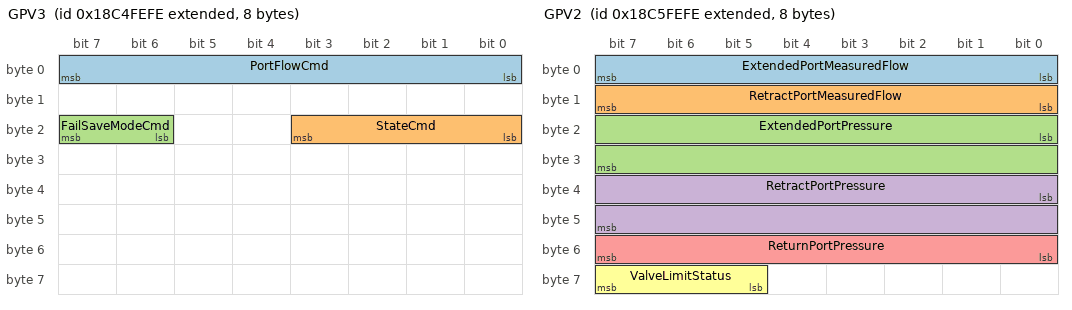
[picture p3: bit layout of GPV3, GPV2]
BO_ 2563047166 GPV3: 8 Vector__XXX
 SG_ PortFlowCmd : 0|8@1+ (0.4,0) [0|100] "%" Vector__XXX
 SG_ StateCmd : 16|4@1+ (1,0) [0|15] "" Vector__XXX
 SG_ FailSaveModeCmd : 22|2@1+ (1,0) [0|3] "" Vector__XXX

BO_ 2563112702 GPV2: 8 Vector__XXX
 SG_ ExtendedPortMeasuredFlow : 0|8@1+ (1,-125) [-125|125] "%" Vector__XXX
 SG_ RetractPortMeasuredFlow : 8|8@1+ (1,-125) [-125|125] "%" Vector__XXX
 SG_ ExtendedPortPressure : 16|16@1+ (5,0) [0|321275] "kPa" Vector__XXX
 SG_ RetractPortPressure : 32|16@1+ (5,0) [0|321275] "kPa" Vector__XXX
 SG_ ReturnPortPressure : 48|8@1+ (16,0) [0|4000] "kPa" Vector__XXX
 SG_ ValveLimitStatus : 61|3@1+ (1,0) [0|7] "" Vector__XXX

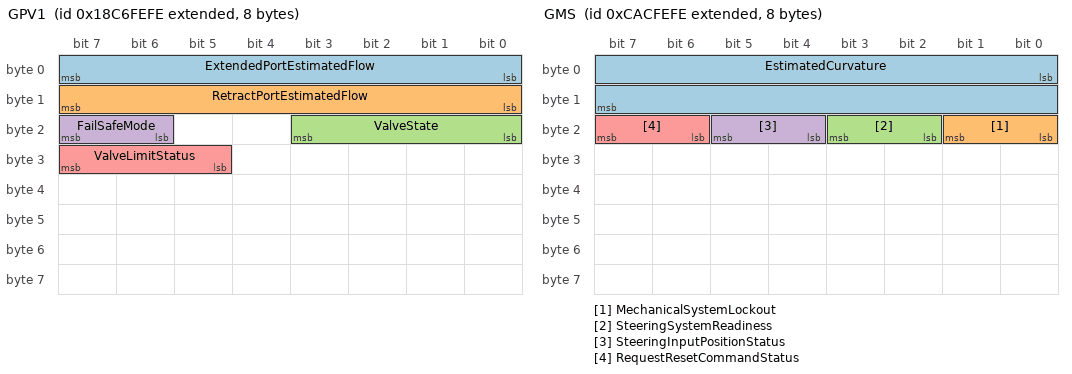
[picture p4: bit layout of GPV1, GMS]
BO_ 2563178238 GPV1: 8 Vector__XXX
 SG_ ExtendedPortEstimatedFlow : 0|8@1+ (1,-125) [-125|125] "%" Vector__XXX
 SG_ RetractPortEstimatedFlow : 8|8@1+ (1,-125) [-125|125] "%" Vector__XXX
 SG_ ValveState : 16|4@1+ (1,0) [0|15] "" Vector__XXX
 SG_ FailSafeMode : 22|2@1+ (1,0) [0|3] "" Vector__XXX
 SG_ ValveLimitStatus : 29|3@1+ (1,0) [0|7] "" Vector__XXX

BO_ 2583168510 GNSSPositionData: 47 Vector__XXX
 SG_ SequenceID : 0|8@1+ (1,0) [0|255] "" Vector__XXX
 SG_ PositionDate : 8|16@1+ (1,0) [0|65532] "day" Vector__XXX
 SG_ PositionTime : 24|32@1+ (0.0001,0) [0|86401] "hour" Vector__XXX
 SG_ LatitudeLow : 56|32@1+ (1E-016,0) [0|4.294E-007] "deg" Vector__XXX
 SG_ LatitudeHigh : 88|32@1- (4.29497E-007,0) [-90|90] "deg" Vector__XXX
 SG_ LongitudeLow : 120|32@1+ (1E-016,0) [0|4.294E-007] "deg" Vector__XXX
 SG_ LongitudeHigh : 152|32@1- (4.29497E-007,0) [-180|180] "deg" Vector__XXX
 SG_ AltitudeLow : 184|32@1+ (1E-006,0) [0|4294] "m" Vector__XXX
 SG_ AltitudeHigh : 216|32@1- (4294.967295,0) [-1705215488|1705215488] "m" Vector__XXX
 SG_ TypeOfSystem : 248|4@1+ (1,0) [0|4] "" Vector__XXX
 SG_ GNSSMethod : 252|4@1+ (1,0) [0|15] "" Vector__XXX
 SG_ GNSSIntegrity : 256|2@1+ (1,0) [0|3] "" Vector__XXX
 SG_ NumberOfSVs : 264|8@1+ (1,0) [0|252] "" Vector__XXX
 SG_ HDOP : 272|16@1- (0.01,0) [-327.64|327.64] "" Vector__XXX
 SG_ PDOP : 288|16@1- (0.01,0) [-327.64|327.64] "" Vector__XXX
 SG_ GeoidalSeparation : 304|32@1- (0.01,0) [-21470000|21470000] "m" Vector__XXX
 SG_ NumberOfReferenceStations : 336|8@1+ (1,0) [0|252] "" Vector__XXX
 SG_ RefrenceStationType1 : 344|4@1+ (1,0) [0|15] "" Vector__XXX
 SG_ ReferenceStationID1 : 348|12@1+ (1,0) [0|4095] "" Vector__XXX
 SG_ AgeOfDGNSSCorrections1 : 360|16@1+ (0.01,0) [0|655.32] "sec" Vector__XXX

BO_ 2360147710 GMS: 8 Vector__XXX
 SG_ EstimatedCurvature : 0|16@1+ (0.25,-8032) [-8032|8031.75] "1/km" Vector__XXX
 SG_ MechanicalSystemLockout : 16|2@1+ (1,0) [0|3] "" Vector__XXX
 SG_ SteeringSystemReadiness : 18|2@1+ (1,0) [0|3] "" Vector__XXX
 SG_ SteeringInputPositionStatus : 20|2@1+ (1,0) [0|3] "" Vector__XXX
 SG_ RequestResetCommandStatus : 22|2@1+ (1,0) [0|3] "" Vector__XXX

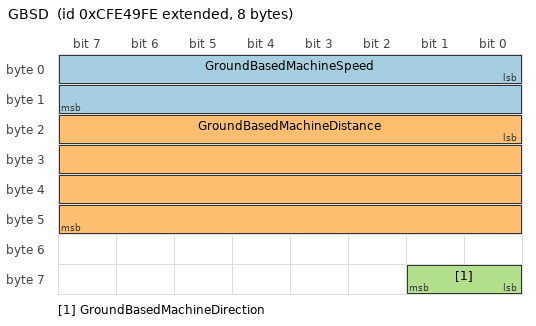
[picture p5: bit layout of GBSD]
BO_ 2365475326 GBSD: 8 Vector__XXX
 SG_ GroundBasedMachineSpeed : 0|16@1+ (0.001,0) [0|64.255] "m/s" Vector__XXX
 SG_ GroundBasedMachineDistance : 16|32@1+ (0.001,0) [0|4211080] "m" Vector__XXX
 SG_ GroundBasedMachineDirection : 56|2@1+ (1,0) [0|3] "" Vector__XXX

BO_ 2628517630 FSServer: 35 Vector__XXX
 SG_ FSServerCommand M : 0|8@1+ (1,0) [0|255] "" Vector__XXX
 SG_ VS_VolumeStatus m2 : 8|8@1+ (1,0) [0|3] "" Vector__XXX
 SG_ VI_TAN m64 : 8|8@1+ (1,0) [0|255] "" Vector__XXX
 SG_ DF_TAN m49 : 8|8@1+ (1,0) [0|255] "" Vector__XXX
 SG_ GSP_VersionNumber m1 : 8|8@1+ (1,0) [0|255] "" Vector__XXX
 SG_ CCD_TAN m17 : 8|8@1+ (1,0) [0|255] "" Vector__XXX
 SG_ GCD_TAN m16 : 8|8@1+ (1,0) [0|255] "" Vector__XXX
 SG_ FDT_TAN m52 : 8|8@1+ (1,0) [0|255] "" Vector__XXX
 SG_ SA_TAN m51 : 8|8@1+ (1,0) [0|255] "" Vector__XXX
 SG_ GA_TAN m50 : 8|8@1+ (1,0) [0|255] "" Vector__XXX
 SG_ MF_TAN m48 : 8|8@1+ (1,0) [0|255] "" Vector__XXX
 SG_ CF_TAN m36 : 8|8@1+ (1,0) [0|255] "" Vector__XXX
 SG_ WF_TAN m35 : 8|8@1+ (1,0) [0|255] "" Vector__XXX
 SG_ RF_TAN m34 : 8|8@1+ (1,0) [0|255] "" Vector__XXX
 SG_ SF_TAN m33 : 8|8@1+ (1,0) [0|255] "" Vector__XXX
 SG_ OF_TAN m32 : 8|8@1+ (1,0) [0|255] "" Vector__XXX
 SG_ FSBusyReading m0 : 8|1@1+ (1,0) [0|1] "" Vector__XXX
 SG_ FSBusyWriting m0 : 9|1@1+ (1,0) [0|1] "" Vector__XXX
 SG_ VS_MaxTimeBeforeVolRemoval m2 : 16|8@1+ (1,0) [0|250] "min/bit" Vector__XXX
 SG_ VI_ErrorCode m64 : 16|8@1+ (1,0) [0|255] "" Vector__XXX
 SG_ DF_ErrorCode m49 : 16|8@1+ (1,0) [0|255] "" Vector__XXX
 SG_ GSP_MaxNrSimultaneousFilesOpen m1 : 16|8@1+ (1,0) [0|255] "" Vector__XXX
 SG_ CCD_ErrorCode m17 : 16|8@1+ (1,0) [0|255] "" Vector__XXX
 SG_ GCD_ErrorCode m16 : 16|8@1+ (1,0) [0|255] "" Vector__XXX
 SG_ SA_ErrorCode m51 : 16|8@1+ (1,0) [0|255] "" Vector__XXX
 SG_ GA_ErrorCode m50 : 16|8@1+ (1,0) [0|255] "" Vector__XXX
 SG_ MF_ErrorCode m48 : 16|8@1+ (1,0) [0|255] "" Vector__XXX
 SG_ CF_ErrorCode m36 : 16|8@1+ (1,0) [0|255] "" Vector__XXX
 SG_ WF_ErrorCode m35 : 16|8@1+ (1,0) [0|255] "" Vector__XXX
 SG_ OF_ErrorCode m32 : 16|8@1+ (1,0) [0|255] "" Vector__XXX
 SG_ FSNumberOfOpenFiles m0 : 16|8@1- (1,0) [0|255] "" Vector__XXX
 SG_ SF_ErrorCode m33 : 16|8@1+ (1,0) [0|255] "" Vector__XXX
 SG_ RF_ErrorCode m34 : 16|8@1+ (1,0) [0|255] "" Vector__XXX
 SG_ FDT_ErrorCode m52 : 16|8@1+ (1,0) [0|255] "" Vector__XXX
 SG_ VS_ErrorCode m2 : 24|8@1+ (1,0) [0|255] "" Vector__XXX
 SG_ WF_Count m35 : 24|16@1+ (1,0) [0|65535] "" Vector__XXX
 SG_ GSP_SupportMultipleVolumes m1 : 24|1@1+ (1,0) [0|255] "" Vector__XXX
 SG_ RF_Count m34 : 24|16@1+ (1,0) [0|65535] "Bytes" Vector__XXX
 SG_ GCD_TotalSpace m16 : 24|32@1+ (512,0) [0|4294966744] "Bytes" Vector__XXX
 SG_ OF_Handle m32 : 24|8@1+ (1,0) [0|255] "" Vector__XXX
 SG_ GA_ATTR_ReadOnly m50 : 24|1@1+ (1,0) [0|1] "" Vector__XXX
 SG_ FDT_DateDay m52 : 24|5@1+ (1,0) [0|31] "Day" Vector__XXX
 SG_ VI_ATTR_ReadOnly m64 : 24|1@1+ (1,0) [0|1] "" Vector__XXX
 SG_ GA_ATTR_Hidden m50 : 25|1@1+ (1,0) [0|1] "" Vector__XXX
 SG_ VI_ATTR_Hidden m64 : 25|1@1+ (1,0) [0|1] "" Vector__XXX
 SG_ GA_ATTR_VolSupportsHiddenAttr m50 : 26|1@1+ (1,0) [0|1] "" Vector__XXX
 SG_ VI_ATTR_VolSupportsHiddenAttr m64 : 26|1@1+ (1,0) [0|1] "" Vector__XXX
 SG_ GA_ATTR_IsVolume m50 : 27|1@1+ (1,0) [0|1] "" Vector__XXX
 SG_ VI_ATTR_IsVolume m64 : 27|1@1+ (1,0) [0|1] "" Vector__XXX
 SG_ VI_ATTR_Directory m64 : 28|1@1+ (1,0) [0|1] "" Vector__XXX
 SG_ GA_ATTR_Directory m50 : 28|1@1+ (1,0) [0|1] "" Vector__XXX
 SG_ GA_ATTR_SupportsLongFilenames m50 : 29|1@1+ (1,0) [0|1] "" Vector__XXX
 SG_ FDT_DateMonth m52 : 29|4@1+ (1,0) [0|12] "Month" Vector__XXX
 SG_ VI_ATTR_SupportsLongFilenames m64 : 29|1@1+ (1,0) [0|1] "" Vector__XXX
 SG_ GA_ATTR_VolumeRemovable m50 : 30|1@1+ (1,0) [0|1] "" Vector__XXX
 SG_ VI_ATTR_VolumeRemovable m64 : 30|1@1+ (1,0) [0|1] "" Vector__XXX
 SG_ GA_ATTR_VolumeIsCaseSensitive m50 : 31|1@1+ (1,0) [0|1] "" Vector__XXX
 SG_ VI_VolumeIsCaseSensitive m64 : 31|1@1+ (1,0) [0|1] "" Vector__XXX
 SG_ VS_VolumeName m2 : 32|16@1+ (1,0) [0|65535] "" Vector__XXX
 SG_ GA_Size m50 : 32|32@1+ (1,0) [0|4294967295] "" Vector__XXX
 SG_ OF_ATTR_ReadOnly m32 : 32|1@1+ (1,0) [0|1] "" Vector__XXX
 SG_ SF_Position m33 : 32|32@1+ (1,0) [0|4294967295] "" Vector__XXX
 SG_ OF_ATTR_Hidden m32 : 33|1@1+ (1,0) [0|1] "" Vector__XXX
 SG_ FDT_DateYear m52 : 33|7@1+ (1,1980) [1980|2107] "Year" Vector__XXX
 SG_ OF_ATTR_IsVolume m32 : 35|1@1+ (1,0) [0|1] "" Vector__XXX
 SG_ OF_ATTR_Directory m32 : 36|1@1+ (1,0) [0|1] "" Vector__XXX
 SG_ OF_ATTR_SupportsLongFilenames m32 : 37|1@1+ (1,0) [0|1] "" Vector__XXX
 SG_ OF_ATTR_VolumeRemovable m32 : 38|1@1+ (1,0) [0|1] "" Vector__XXX
 SG_ OF_ATTR_VolumeIsCaseSensitive m32 : 39|1@1+ (1,0) [0|1] "" Vector__XXX
 SG_ FDT_TimeSeconds m52 : 40|5@1+ (2,0) [0|58] "Seconds" Vector__XXX
 SG_ FDT_TimeMinutes m52 : 45|6@1+ (1,0) [0|59] "Minutes" Vector__XXX
 SG_ FDT_TimeHour m52 : 51|5@1+ (1,0) [0|23] "Hour" Vector__XXX
 SG_ GCD_FreeSpace m16 : 56|32@1+ (512,0) [0|4294966744] "Bytes" Vector__XXX
 SG_ GCD_PathName m16 : 88|16@1+ (1,0) [0|65535] "" Vector__XXX

CM_ BO_ 2362179326 "The Process Data message is used for the transmission of device description data, 
measured data and or set point commands to one or more controllers.";
CM_ SG_ 2362179326 NumberOfControlChannels "Number of control channels for position based control";
CM_ SG_ 2362179326 Command "Process Data Command";
CM_ SG_ 2362179326 ErrorElementNumber "Device Element Number";
CM_ SG_ 2362179326 ElementNumber "Device Element Number";
CM_ SG_ 2362179326 PeerControlDDI "Data Dictionary Identifier";
CM_ SG_ 2362179326 BootTimeTC "Maximum number of seconds from a power cycle to transmission of first Task Controller Status message";
CM_ SG_ 2362179326 DDI "Data Dictionary Identifier";
CM_ SG_ 2362179326 ErrorDDI "Data Dictionary Identifier";
CM_ SG_ 2362179326 DDI_DI "Data Dictionary Identifier";
CM_ SG_ 2362179326 DDI_TI "Data Dictionary Identifier";
CM_ SG_ 2362179326 DataDictionaryVersion "This DDE is used to specify which version of the Data Dictionary is being used.";
CM_ SG_ 2362179326 RequestDefaultProcessData "Request Default Process Data.";
CM_ SG_ 2362179326 PGNBasedData "This DDI is used in the XML files to identify PGN based data";
CM_ SG_ 2362179326 LastUnloadedWeight "Last unloaded Weight value specified as mass";
CM_ SG_ 2362179326 LastLoadedWeight "Last loaded Weight value specified as mass";
CM_ SG_ 2362179326 IneffectiveTotalDieselExhaustFlu "Accumulated total Diesel Exhaust Fluid consumption in non working position";
CM_ SG_ 2362179326 EffectiveTotalDieselExhaustFluid "Accumulated total Diesel Exhaust Fluid consumption in working position";
CM_ SG_ 2362179326 IneffectiveTotalFuelConsumption "Accumulated total fuel consumption in non working position";
CM_ SG_ 2362179326 EffectiveTotalFuelConsumption "Accumulated total fuel consumption in working position";
CM_ SG_ 2362179326 AveragePercentageCropDryMatter "Average Percentage Crop Dry Matter expressed as parts per million";
CM_ SG_ 2362179326 ActualPercentageCropDryMatter "Actual Percentage Crop Dry Matter expressed as parts per million";
CM_ SG_ 2362179326 MaximumRelativeYieldPotential "Maximum potential yield expressed as percentage";
CM_ SG_ 2362179326 MinimumRelativeYieldPotential "Minimum potential yield expressed as percentage";
CM_ SG_ 2362179326 RelativeYieldPotential "Relative yield potential provided by a FMIS or a sensor or entered by the operator for a certain task expressed as percentage";
CM_ SG_ 2362179326 MaximumPercentageApplicationRate "Maximum Application Rate expressed as percentage";
CM_ SG_ 2362179326 MinimumPercentageApplicationRate "Actual Application Rate expressed as percentage";
CM_ SG_ 2362179326 ActualPercentageApplicationRate "Actual Application Rate expressed as percentage";
CM_ SG_ 2362179326 TrueRotationPointYOffset "Y direction offset of the device rotation point relative to the DRP";
CM_ SG_ 2362179326 TrueRotationPointXOffset "X direction offset of the device rotation point relative to the DRP";
CM_ SG_ 2362179326 SetpointCondensedWorkState241to2 "The Setpoint Condensed Work State DDIs are the control command counterparts to the Condensed Work States DDIs (161 – 176)";
CM_ SG_ 2362179326 SetpointCondensedWorkState225to2 "The Setpoint Condensed Work State DDIs are the control command counterparts to the Condensed Work States DDIs (161 – 176)";
CM_ SG_ 2362179326 SetpointCondensedWorkState209to2 "The Setpoint Condensed Work State DDIs are the control command counterparts to the Condensed Work States DDIs (161 – 176)";
CM_ SG_ 2362179326 SetpointCondensedWorkState193to2 "The Setpoint Condensed Work State DDIs are the control command counterparts to the Condensed Work States DDIs (161 – 176)";
CM_ SG_ 2362179326 SetpointCondensedWorkState177to1 "The Setpoint Condensed Work State DDIs are the control command counterparts to the Condensed Work States DDIs (161 – 176)";
CM_ SG_ 2362179326 SetpointCondensedWorkState161to1 "The Setpoint Condensed Work State DDIs are the control command counterparts to the Condensed Work States DDIs (161 – 176)";
CM_ SG_ 2362179326 SetpointCondensedWorkState145to1 "The Setpoint Condensed Work State DDIs are the control command counterparts to the Condensed Work States DDIs (161 – 176)";
CM_ SG_ 2362179326 SetpointCondensedWorkState129to1 "The Setpoint Condensed Work State DDIs are the control command counterparts to the Condensed Work States DDIs (161 – 176)";
CM_ SG_ 2362179326 SetpointCondensedWorkState113to1 "The Setpoint Condensed Work State DDIs are the control command counterparts to the Condensed Work States DDIs (161 – 176)";
CM_ SG_ 2362179326 SetpointCondensedWorkState97to11 "The Setpoint Condensed Work State DDIs are the control command counterparts to the Condensed Work States DDIs (161 – 176)";
CM_ SG_ 2362179326 SetpointCondensedWorkState81to96 "The Setpoint Condensed Work State DDIs are the control command counterparts to the Condensed Work States DDIs (161 – 176)";
CM_ SG_ 2362179326 SetpointCondensedWorkState65to80 "The Setpoint Condensed Work State DDIs are the control command counterparts to the Condensed Work States DDIs (161 – 176)";
CM_ SG_ 2362179326 SetpointCondensedWorkState49to64 "The Setpoint Condensed Work State DDIs are the control command counterparts to the Condensed Work States DDIs (161 – 176)";
CM_ SG_ 2362179326 SetpointCondensedWorkState33to48 "The Setpoint Condensed Work State DDIs are the control command counterparts to the Condensed Work States DDIs (161 – 176)";
CM_ SG_ 2362179326 SetpointCondensedWorkState17to32 "The Setpoint Condensed Work State DDIs are the control command counterparts to the Condensed Work States DDIs (161 – 176)";
CM_ SG_ 2362179326 SetpointCondensedWorkState1to16 "The Setpoint Condensed Work State DDIs are the control command counterparts to the Condensed Work States DDIs (161 – 176)";
CM_ SG_ 2362179326 SetpointWorkState "The Setpoint Work State DDI is the control command counterparts to the Work State DDI (141)";
CM_ SG_ 2362179326 LifetimeUncutTotalCount "Entire Uncut Total Count of the device lifetime";
CM_ SG_ 2362179326 LifetimePrecutTotalCount "Entire Precut Total Count of the device lifetime";
CM_ SG_ 2362179326 UncutTotalCount "The total number of un-cutted product units produced by a device during an operation";
CM_ SG_ 2362179326 PrecutTotalCount "The total number of pre-cutted product units produced by a device during an operation";
CM_ SG_ 2362179326 LifetimeThreshingEngagementTotal "Entire Threshing Engagement Total Time of the device lifetime";
CM_ SG_ 2362179326 LifetimeYieldTotalLintCottonMass "Entire Yield Total Lint Cotton Mass of the device lifetime";
CM_ SG_ 2362179326 LifetimeYieldTotalSeedCottonMass "Entire Yield Total Seed Cotton Mass of the device lifetime";
CM_ SG_ 2362179326 LifetimeYieldTotalDryMass "Entire Yield Total Dry Mass of the device lifetime";
CM_ SG_ 2362179326 LifetimeAverageFuelConsumptionPe "Entire Average Fuel Consumption per Area of the device lifetime";
CM_ SG_ 2362179326 LifetimeAverageFuelConsumpt_0000 "Entire Average Fuel Consumption per Time of the device lifetime";
CM_ SG_ 2362179326 LifetimeFuelConsumption "Entire Fuel Consumption of the device lifetime";
CM_ SG_ 2362179326 LifetimeIneffectiveTotalTime "Entire Ineffective Total Time of the device lifetime";
CM_ SG_ 2362179326 LifetimeEffectiveTotalTime "Entire Ineffective Total Distance of the device lifetime";
CM_ SG_ 2362179326 LifetimeIneffectiveTotalDistance "Entire Ineffective Total Distance of the device lifetime";
CM_ SG_ 2362179326 LifetimeTotalDistance "Entire Total Area of the device lifetime";
CM_ SG_ 2362179326 LifetimeTotalArea "Entire Total Area of the device lifetime";
CM_ SG_ 2362179326 LifetimeYieldTotalCount "Entire Yield Total Count of the device lifetime";
CM_ SG_ 2362179326 LifetimeYieldTotalMass "Entire Yield Total Mass of the device lifetime";
CM_ SG_ 2362179326 LifetimeYieldTotalVolume "Entire Yield Total Volume of the device lifetime";
CM_ SG_ 2362179326 LifetimeApplicationTotalCount "Entire Application Total Count of the device lifetime";
CM_ SG_ 2362179326 LifetimeApplicationTotalMass "Entire Application Total Count of the device lifetime";
CM_ SG_ 2362179326 RemainingArea "Remaining Area of a field";
CM_ SG_ 2362179326 ConnectorPivotXOffset "X direction offset of a connector pivot point relative to DRP";
CM_ SG_ 2362179326 AverageYieldMassPerArea "This Average Yield Mass Per Area is the mass that includes the average crop moisture (DDI 262) i";
CM_ SG_ 2362179326 AverageCropMoisture "Average Moisture of the harvested crop. 
This value is the average for a Task and may be reported as a total.";
CM_ SG_ 2362179326 AverageYieldMassPerTime "Average Yield expressed as mass per unit time, 
not corrected for the reference moisture percentage DDI 184. 
This value is the average for a Task and may be reported as a total.";
CM_ SG_ 2362179326 YieldLeadIgnoreTime "Amount of time to ignore yield data, 
starting at the transition from the out-of-work to the in-work state. 
During this time, the yield sensor provides 
inconsistent or unreliable crop flow data.";
CM_ SG_ 2362179326 YieldLagIgnoreTime "Amount of time to ignore yield data, 
starting at the transition from the in-work to the out-of-work state. 
During this time, the yield sensor provides 
inconsistent or unreliable crop flow data.";
CM_ SG_ 2362179326 HydraulicOilTemperature "Temperature of fluid in the hydraulic system.";
CM_ SG_ 2362179326 MaximumSeparationFanRotationalSp "Maximum rotational speed of the fan used 
for separating product material from non product material.";
CM_ SG_ 2362179326 MinimumSeparationFanRotationalSp "Minimum rotational speed of the fan used 
for separating product material from non product material.";
CM_ SG_ 2362179326 ActualSeparationFanRotationalSpe "Actual rotational speed of the fan used 
for separating product material from non product material.";
CM_ SG_ 2362179326 SetpointSeparationFanRotationalS "Setpoint rotational speed of the fan used 
for separating product material from non product material.";
CM_ SG_ 2362179326 MaximumConcaveClearance "Maximum separation distance between Concave elements.";
CM_ SG_ 2362179326 MinimumConcaveClearance "Minimum separation distance between Concave elements.";
CM_ SG_ 2362179326 ActualConcaveClearance "Actual separation distance between Concave elements.";
CM_ SG_ 2362179326 SetpointConcaveClearance "Setpoint separation distance between Concave elements.";
CM_ SG_ 2362179326 MaximumChafferClearance "Maximum separation distance between Chaffer elements.";
CM_ SG_ 2362179326 MinimumChafferClearance "Minimum separation distance between Chaffer elements.";
CM_ SG_ 2362179326 ActualChafferClearance "Actual separation distance between Chaffer elements.";
CM_ SG_ 2362179326 SetpointChafferClearance "Setpoint separation distance between Chaffer elements.";
CM_ SG_ 2362179326 MaximumSieveClearance "Maximum separation distance between Sieve elements.";
CM_ SG_ 2362179326 MinimumSieveClearance "Minimal separation distance between Sieve elements";
CM_ SG_ 2362179326 ActualSieveClearance "Actual separation distance between Sieve elements";
CM_ SG_ 2362179326 SetpointSieveClearance "Setpoint separation distance between Sieve elements";
CM_ SG_ 2362179326 CropTemperature "Temperature of harvested crop";
CM_ SG_ 2362179326 ActualUnLoadingSystemStatus "Actual status of the Unloading and/or Loading system.";
CM_ SG_ 2362179326 YieldHoldStatus "Status indicator for the yield measurement system. ";
CM_ SG_ 2362179326 ActualHeaderRotationalSpeedStatu "Actual status of the header rotational speed 
being above or below the threshold for in-work state.";
CM_ SG_ 2362179326 ActualHeaderWorkingHeightStatus "Actual status of the header being above or below 
the threshold height for the in-work state.";
CM_ SG_ 2362179326 ThreshingEngagementTotalTime "Accumulated time while the threshing mechanism is engaged";
CM_ SG_ 2362179326 MaximumGrossWeight "Maximum Gross Weight may represent the maximum value 
of the effective range of the weighing system.";
CM_ SG_ 2362179326 MinimumGrossWeight "The Minimum Gross Weight may represent the minimum value 
of the effective range of the weighing system.";
CM_ SG_ 2362179326 GrossWeightState "The Gross Weight State indicates whether the current 
Actual Gross Weight value is a reliable value or not.";
CM_ SG_ 2362179326 ActualGrossWeight "The Actual Gross Weight is the overall 
measured mass by a weighing system.";
CM_ SG_ 2362179326 SetpointNetWeight "The Setpoint Net Weight value is used to prompt 
the weighing system to perform a tare procedure.";
CM_ SG_ 2362179326 NetWeightState "The Net Weight State indicates whether the current 
Actual Net Weight value is a reliable value or not.";
CM_ SG_ 2362179326 ActualNetWeight "The Actual Net Weight is the current measured mass by a weighing system.";
CM_ SG_ 2362179326 MaximumWorkingLength "This is the maximum working length of the device element during operation.";
CM_ SG_ 2362179326 MinimumWorkingLength "This is the minimum working length of the device element during operation.";
CM_ SG_ 2362179326 ActualWorkingLength "Actual Working Length of a Device Element.";
CM_ SG_ 2362179326 SetpointWorkingLength "This is the desired working length of the device element during operation.";
CM_ SG_ 2362179326 DeltaT "The difference between dry bulb temperature and wet bulb temperature measured 
by a weather station in a treated field or on the application equipment.";
CM_ SG_ 2362179326 LastBaleMass "The mass of the bale that has most recently been produced.";
CM_ SG_ 2362179326 LastBaleTagNumber "The Last Bale Tag Number as a decimal number in the range of 0 to 4294967295.";
CM_ SG_ 2362179326 LastBaleAppliedPreservative "The total preservative applied to the most recently produced bale.";
CM_ SG_ 2362179326 LastBaleAverageBaleCompressionPl "The average bale compression plunger load for the most recently produced bale.";
CM_ SG_ 2362179326 ActualBaleCompressionPlungerLoad "The actual bale compression plunger load as a unitless number.";
CM_ SG_ 2362179326 SetpointBaleCompressionPlungerLo "The setpoint bale compression plunger load as a unitless number.";
CM_ SG_ 2362179326 LastBaleAverageHydraulicPressure "The average actual value of the hydraulic pressure applied 
to the sides of the bale in the bale compression chamber.";
CM_ SG_ 2362179326 ActualBaleHydraulicPressure "The actual value of the hydraulic pressure applied 
to the sides of the bale in the bale compression chamber.";
CM_ SG_ 2362179326 LifetimeWorkingHours "The number of working hours of a device element over its entire lifetime.";
CM_ SG_ 2362179326 LifetimeBaleCount "The number of bales produced by a machine over its entire lifetime.";
CM_ SG_ 2362179326 LastBaleAverageStrokesPerFlake "The number of baler plunger compression strokes per flake 
that has entered the bale compression chamber. 
This value is the average valid for the most recently produced bale.";
CM_ SG_ 2362179326 LastBaleAverageMoisture "The average moisture in the most recently produced bale.";
CM_ SG_ 2362179326 LastBaleFlakesPerBale "The number of flakes in the most recently produced bale.";
CM_ SG_ 2362179326 SkyConditions "This DDE is used to define the current sky conditions during operation.";
CM_ SG_ 2362179326 AirHumidity "Ambient humidty measured by a weather station 
in a treated field or on the application implement.";
CM_ SG_ 2362179326 SCTurnOffTime "The Section Control Turn Off Time defines the overall time lapse 
between the moment the TC sends a turn off section command 
to the working set and the moment this section is physically turned off.";
CM_ SG_ 2362179326 SCTurnOnTime_ "The Section Control Turn On Time defines the overall time lapse 
between the moment the TC sends a turn on section command 
to the working set and the moment this section 
is physically turned on and the product is applied.";
CM_ SG_ 2362179326 MaximumTankAgitationPressure "Maximun Tank Agitation Pressure for a stir system in a tank.";
CM_ SG_ 2362179326 MinimumTankAgitationPressure "Minimun Tank Agitation Pressure for a stir system in a tank.";
CM_ SG_ 2362179326 ActualTankAgitationPressure "Actual Tank Agitation Pressure measured by the tank stir system.";
CM_ SG_ 2362179326 SetpointTankAgitationPressure "Setpoint Tank Agitation Pressure to adjust the pressure for a stir system in a tank.";
CM_ SG_ 2362179326 MaximumPumpOutputPressure "Maximum Pump Output Pressure for the output pressure of the solution pump.";
CM_ SG_ 2362179326 MinimumPumpOutputPressure "Minimum Pump Output Pressure for the output pressure of the solution pump.";
CM_ SG_ 2362179326 ActualPumpOutputPressure "Actual Pump Output Pressure measured at the output of the solution pump.";
CM_ SG_ 2362179326 SetpointPumpOutputPressure "Setpoint Pump Output Pressure to adjust the  pressure at the output of the solution pump.";
CM_ SG_ 2362179326 MaximumProductPressure "Maximum Product Pressure in the product flow system at the point of dispensing.";
CM_ SG_ 2362179326 MinimumProductPressure "Minimun Product Pressure in the product flow system at the point of dispensing. ";
CM_ SG_ 2362179326 ActualProductPressure "Actual Product Pressure is the measured pressure in the product flow system at the point of dispensing.";
CM_ SG_ 2362179326 SetpointProductPressure "Setpoint Product Pressure to adjust the pressure of the product flow system at the point of dispensing.";
CM_ SG_ 2362179326 AmbientTemperature "Ambient temperature measured by a machine. Unit is milli-Kelvin (mK).";
CM_ SG_ 2362179326 LintTurnoutPercentage "Percent of lint in the seed cotton.";
CM_ SG_ 2362179326 YieldTotalLintCottonMass "Accumulated yield specified as lint cotton mass.";
CM_ SG_ 2362179326 YieldTotalSeedCottonMass "Accumulated yield specified as seed cotton mass, not corrected for a possibly included lint percantage.";
CM_ SG_ 2362179326 LintCottonMassPerTimeYield "Lint cotton yield as mass per time.";
CM_ SG_ 2362179326 SeedCottonMassPerTimeYield "Seed cotton yield as mass per time, not corrected for a possibly included lint percantage.";
CM_ SG_ 2362179326 LintCottonMassPerAreaYield "Lint cotton yield as mass per area.";
CM_ SG_ 2362179326 SeedCottonMassPerAreaYield "Seed cotton yield as mass per area, not corrected for a possibly included lint percantage.";
CM_ SG_ 2362179326 RefMoistureForDryMass "Moisture percentage used for the dry mass DDIs 181, 182 and 183.";
CM_ SG_ 2362179326 YieldTotalDryMass "Accumulated Yield specified as dry mass. 
The definition of dry mass is the mass 
with a reference moisture specified by DDI 184.";
CM_ SG_ 2362179326 DryMassPerTimeYield "Yield as dry mass per time. The definition of dry mass 
is the mass with a reference moisture specified by DDI 184.";
CM_ SG_ 2362179326 DryMassPerAreaYield "Yield as dry mass per area. The definition of dry mass 
is the mass with a reference moisture specified by DDI 184.";
CM_ SG_ 2362179326 DRP2GroundDistance "This DDI is used to specify the distance from the Device Reference Point (DRP) 
down to the ground surface. The DRP to Ground DDI shall be attached 
only to the Device Element (DET) with element number zero.";
CM_ SG_ 2362179326 ActualCulturalPractice "This DDI is used to define the current cultural practice which is performed 
by an individual device operation. For instance a planter/seeder 
could provide a sowing and a fertilizing operation at the same time.";
CM_ SG_ 2362179326 ElementTypeInstance "This DDI is used to enumerate and identify multiple device elements (DET) 
of the same type within one Device Description object pool";
CM_ SG_ 2362179326 ActualLengthOfCut "Actual length of cut for harvested material, e.g. Forage Harvester or Tree Harvester";
CM_ SG_ 2362179326 CondensedWorkState241to256 "Combination of the work states of individual sections or units (e.g. nozzles) 
number 241 to 256 into a single work state of their parent device element";
CM_ SG_ 2362179326 CondensedWorkState225to240 "Combination of the work states of individual sections or units (e.g. nozzles) 
number 225 to 240 into a single work state of their parent device element";
CM_ SG_ 2362179326 CondensedWorkState209to224 "Combination of the work states of individual sections or units (e.g. nozzles) 
number 209 to 224 into a single work state of their parent device element";
CM_ SG_ 2362179326 CondensedWorkState193to208 "Combination of the work states of individual sections or units (e.g. nozzles) 
number 193 to 208 into a single work state of their parent device element";
CM_ SG_ 2362179326 CondensedWorkState177to192 "Combination of the work states of individual sections or units (e.g. nozzles) 
number 177 to 192 into a single work state of their parent device element";
CM_ SG_ 2362179326 CondensedWorkState161to176 "Combination of the work states of individual sections or units (e.g. nozzles) 
number 161 to 176 into a single work state of their parent device element";
CM_ SG_ 2362179326 CondensedWorkState145to160 "Combination of the work states of individual sections or units (e.g. nozzles) 
number 145 to 160 into a single work state of their parent device element";
CM_ SG_ 2362179326 CondensedWorkState129to144 "Combination of the work states of individual sections or units (e.g. nozzles) 
number 129 to 144 into a single work state of their parent device element";
CM_ SG_ 2362179326 CondensedWorkState113to128 "Combination of the work states of individual sections or units (e.g. nozzles) 
number 113 to 128 into a single work state of their parent device element";
CM_ SG_ 2362179326 CondensedWorkState97to112 "Combination of the work states of individual sections or units (e.g. nozzles) 
number 97 to 112 into a single work state of their parent device element";
CM_ SG_ 2362179326 CondensedWorkState81to96 "Combination of the work states of individual sections or units (e.g. nozzles) 
number 81 to 96 into a single work state of their parent device element";
CM_ SG_ 2362179326 CondensedWorkState65to80 "Combination of the work states of individual sections or units (e.g. nozzles) 
number 65 to 80 into a single work state of their parent device element";
CM_ SG_ 2362179326 CondensedWorkState49to64 "Combination of the work states of individual sections or units (e.g. nozzles) 
number 49 to 64 into a single work state of their parent device element";
CM_ SG_ 2362179326 CondensedWorkState33to48 "Combination of the work states of individual sections or units (e.g. nozzles) 
number 33 to 48 into a single work state of their parent device element";
CM_ SG_ 2362179326 CondensedWorkState17to32 "Combination of the work states of individual sections or units (e.g. nozzles) 
number 17 to 32 into a single work state of their parent device element";
CM_ SG_ 2362179326 CondensedWorkState1to16 "Combination of the work states of individual sections or units (e.g. nozzles) 
number 1 to 16 into a single work state of their parent device element";
CM_ SG_ 2362179326 SectionControlState "Specifies the actual state of section control";
CM_ SG_ 2362179326 NumberOfSubUnitsPerSection "Specifies the number of sub-units for a section 
(e.g. number of nozzles per sprayer section 
or number of planter row units per metering device)";
CM_ SG_ 2362179326 PrescriptionControlState "Defines and synchronise the actual state of the prescription system";
CM_ SG_ 2362179326 ConnectorType "Specification of the type of coupler.";
CM_ SG_ 2362179326 PhysicalObjectHeight "Height of device element (dimension along the Z-axis)";
CM_ SG_ 2362179326 PhysicalObjectWidth "Width of device element (dimension along the Y-axis)";
CM_ SG_ 2362179326 PhysicalObjectLength "Length of device element (dimension along the X-axis)";
CM_ SG_ 2362179326 NDVI "Actual Normalized Difference Vegetative Index (NDVI)";
CM_ SG_ 2362179326 MinMassPerAreaAppRate "Minimum Application Rate specified as mass per area";
CM_ SG_ 2362179326 AreaPerTimeCapacity "Area per time capacity";
CM_ SG_ 2362179326 FuelConsumptionPerArea "Fuel consumption per area";
CM_ SG_ 2362179326 FuelConsumptionPerTime "Fuel consumption per time";
CM_ SG_ 2362179326 TotalFuelConsumption "Accumulated Fuel Consumption as Counter";
CM_ SG_ 2362179326 LogCount "Log Counter, may be used to control data log record generation on a
Task Controller";
CM_ SG_ 2362179326 PitchAngle "Pitch Angle of a DeviceElement";
CM_ SG_ 2362179326 RollAngle "Roll Angle of a DeviceElement";
CM_ SG_ 2362179326 YawAngle "Pivot / Yaw Angle of a DeviceElement";
CM_ SG_ 2362179326 ActualValueTimeLatency "Temporal Latency valid for the actual value of a Device Element";
CM_ SG_ 2362179326 SetpointTimeLatency "Temporal Latency valid for the setpoint values of a Device Element";
CM_ SG_ 2362179326 PercentageAppRateSetpoint "Application Rate expressed as percentage";
CM_ SG_ 2362179326 DeviceCountCapacity "DeviceElement Count Capacity, dimension of a DeviceElement";
CM_ SG_ 2362179326 DeviceMassCapacity "DeviceElement Mass Capacity, dimension of a DeviceElement.";
CM_ SG_ 2362179326 DeviceVolumeCapacity "DeviceElement Volume Capacity, dimension of a DeviceElement.";
CM_ SG_ 2362179326 DeviceElementOffsetZ "Z direction offset of a DeviceElement relative to  Device.";
CM_ SG_ 2362179326 DeviceElementOffsetY "Y direction offset of a DeviceElement relative to  Device.";
CM_ SG_ 2362179326 DeviceElementOffsetX "X direction offset of a DeviceElement relative to a Device.";
CM_ SG_ 2362179326 AuxiliaryValveInvertPorts "Command valve to swap extend and retract ports, easier than redoing
plumbing on valve.";
CM_ SG_ 2362179326 AuxiliaryValveProgressivRetract "Define non-linear releationship between command and flow by 2nd
degree polynomium.";
CM_ SG_ 2362179326 AuxiliaryValveProgressivExtend "Define non-linear releationship between command and flow by 2nd
degree polynomium.";
CM_ SG_ 2362179326 AuxiliaryValveFloatThreshold "Safety function. Current output of valve must be above threshold before
float command is allowed.";
CM_ SG_ 2362179326 AuxiliaryValveRampRetractDown "The valve will apply a ramp to the Auxiliary ValveCommand
PortFlowCommand, to limit the acceleration or deceleration of flow.";
CM_ SG_ 2362179326 AuxiliaryValveRampRetractUp "The valve will apply a ramp to theAuxiliary ValveCommand
PortFlowCommand, to limit the acceleration or deceleration of flow.";
CM_ SG_ 2362179326 AuxiliaryValveRampExtendDown "The valve will apply a ramp to the Auxiliary ValveCommand
PortFlowCommand, to limit the acceleration or deceleration of flow.";
CM_ SG_ 2362179326 AuxiliaryRampExtendUp "The valve will apply a ramp to the Auxiliary ValveCommand
PortFlowCommand, to limit the acceleration or deceleration of flow.";
CM_ SG_ 2362179326 AuxiliaryValveScalingRetract "Factor to apply to AuxValveCommand PortFlowCommand.";
CM_ SG_ 2362179326 AuxiliaryValveScalingExtend "Factor to apply to AuxValveCommand PortFlowCommand.";
CM_ SG_ 2362179326 PrdoucDensityVolumePerCount "Product Density as volume per count";
CM_ SG_ 2362179326 PrdoucDensityMassPerCount "Product Density as mass per count";
CM_ SG_ 2362179326 PrdoucDensityMassPerArea "Product Density as mass per volume";
CM_ SG_ 2362179326 AccumulatedTimeOutWork "Accumulated Time out of working position";
CM_ SG_ 2362179326 AccumulatedTimeInWork "Accumulated Time in working position";
CM_ SG_ 2362179326 AccumulatedDistanceOutWork "Accumulated Distance out of working position";
CM_ SG_ 2362179326 AccumulatedDistanceInWork "Accumulated Distance in working position";
CM_ SG_ 2362179326 AccumulatedArea "Accumulated Area";
CM_ SG_ 2362179326 BaleSize_Max "Maximum Bale Size as length for a square baler or diameter for a round baler";
CM_ SG_ 2362179326 BaleSize_Min "Minimum Bale Size as length for a square baler or diameter for a round baler";
CM_ SG_ 2362179326 BaleSize_Def "Default Bale Size as length for a square baler or diameter for a round baler";
CM_ SG_ 2362179326 BaleSize_Act "Actual Bale Size as length for a square baler or diameter for a round baler";
CM_ SG_ 2362179326 BaleSize_Set "Setpoint Bale Size as length for a square baler or diameter for a round baler";
CM_ SG_ 2362179326 BaleHeight_Max "Maximum Bale Height is only applicable to square baler";
CM_ SG_ 2362179326 BaleHeight_Min "Minimum Bale Height is only applicable to square baler";
CM_ SG_ 2362179326 BaleHeight_Def "Default Bale Height is only applicable to square baler";
CM_ SG_ 2362179326 BaleHeight_Act "Actual Bale Height is only applicable to square baler";
CM_ SG_ 2362179326 BaleHeight_Set "Setpoint Bale Height is only applicable to square baler";
CM_ SG_ 2362179326 BaleWidth_Max "Maximum Bale Width for square baler or round baler";
CM_ SG_ 2362179326 BaleWidth_Min "Minimum Bale Width for square baler or round baler";
CM_ SG_ 2362179326 BaleWidth_Def "Default Bale Width for square baler or round baler";
CM_ SG_ 2362179326 BaleWidth_Act "Actual Bale Width for square baler or round baler";
CM_ SG_ 2362179326 BaleWidth_Set "Setpoint Bale Width for square baler or round baler";
CM_ SG_ 2362179326 DirtMaterialInCropYield "Dirt or foreign material in crop yield";
CM_ SG_ 2362179326 MoistureInCropYield "Moisture in crop yield";
CM_ SG_ 2362179326 CropYieldLoss "Crop yield loss";
CM_ SG_ 2362179326 CropYieldLossCountPerTime "Crop yield loss as count per time";
CM_ SG_ 2362179326 CropYieldLossMassPerTime "Crop yield loss as mass per time";
CM_ SG_ 2362179326 CropYieldLossVolumePerTime "Crop yield loss as volume per time";
CM_ SG_ 2362179326 CropYieldLossCountPerArea "Crop yield loss as count per area";
CM_ SG_ 2362179326 CropYieldLossMassPerArea "Crop yield loss as mass per area";
CM_ SG_ 2362179326 CropYieldLossVolumePerArea "Crop yield loss as volume per area";
CM_ SG_ 2362179326 AccumulatedYieldAsCount "Accumulated Yield specified as count";
CM_ SG_ 2362179326 AccumulatedYieldAsMass "Accumulated Yield specified as mass";
CM_ SG_ 2362179326 AccumulatedYieldAsVolume "Accumulated Yield specified as volume";
CM_ SG_ 2362179326 YieldCountPerTime "Yield as count per area";
CM_ SG_ 2362179326 YieldMassPerTime "Yield as mass per area";
CM_ SG_ 2362179326 YieldVolumePerTime "Yield as volume per area";
CM_ SG_ 2362179326 YieldCountPerArea "Yield as count per area";
CM_ SG_ 2362179326 YieldMassPerArea "Yield as mass per area";
CM_ SG_ 2362179326 YieldVolumePerArea "Yield as volume per area";
CM_ SG_ 2362179326 AccumulatedAppAsCount "Accumulated Application specified as count";
CM_ SG_ 2362179326 AccumulatedAppAsMass "Accumulated Application specified as mass";
CM_ SG_ 2362179326 AccumulatedAppAsVolume "Accumulated Application specified as volume";
CM_ SG_ 2362179326 ContentAsCount_Max "Maximum Machine Element Content specified as count";
CM_ SG_ 2362179326 ContentAsCount_Act "Actual Machine Element Content specified as count";
CM_ SG_ 2362179326 ContentAsCount_Set "Setpoint Machine Element Content specified as count";
CM_ SG_ 2362179326 ContentAsMass_Max "Maximum Machine Element Content specified as mass";
CM_ SG_ 2362179326 ContentAsMass_Act "Actual Machine Element Content specified as mass";
CM_ SG_ 2362179326 ContentAsMass_Set "Setpoint Machine Element Content specified as mass";
CM_ SG_ 2362179326 ContentAsVolume_Max "Maximum Machine Element Content specified as volume";
CM_ SG_ 2362179326 ContentAsVolume_Act "Actual Machine Element Content specified as volume";
CM_ SG_ 2362179326 ContentAsVolume_Set "Setpoint Machine Element Content specified as volume";
CM_ SG_ 2362179326 WorkingWidth_Max "Maximum Working Width of Machine Element";
CM_ SG_ 2362179326 WorkingWidth_Min "Minimum Working Width of Machine Element";
CM_ SG_ 2362179326 WorkingWidth_Def "Default Working Width of Machine Element";
CM_ SG_ 2362179326 WorkingWidth_Act "Actual Working Width of Machine Element";
CM_ SG_ 2362179326 WorkingWidth_Set "Setpoint Working Width of Machine Element";
CM_ SG_ 2362179326 WorkingHeight_Max "Maximum Working Height of Machine Element above crop or soil";
CM_ SG_ 2362179326 WorkingHeight_Min "Minimum Working Height of Machine Element above crop or soil";
CM_ SG_ 2362179326 WorkingHeight_Def "Default Working Height of Machine Element above crop or soil";
CM_ SG_ 2362179326 WorkingHeight_Act "Actual Working Height of Machine Element above crop or soil";
CM_ SG_ 2362179326 WorkingHeight_Set "Setpoint Working Height of Machine Element above crop or soil";
CM_ SG_ 2362179326 SeedingDeph_Max "Setpoint Seeding Depth of Machine Element below soil surface, value increases with depth";
CM_ SG_ 2362179326 SeedingDeph_Min "Setpoint Seeding Depth of Machine Element below soil surface, value increases with depth";
CM_ SG_ 2362179326 SeedingDeph_Def "Setpoint Seeding Depth of Machine Element below soil surface, value increases with depth";
CM_ SG_ 2362179326 SeedingDeph_Act "Setpoint Seeding Depth of Machine Element below soil surface, value increases with depth";
CM_ SG_ 2362179326 SeedingDeph_Set "Setpoint Seeding Depth of Machine Element below soil surface, value increases with depth";
CM_ SG_ 2362179326 TillageDepth_Max "Maximum Tillage Depth of Machine Element below soil surface, value increases with depth";
CM_ SG_ 2362179326 TillageDepth_Min "Minimum Tillage Depth of Machine Element below soil surface, value increases with depth";
CM_ SG_ 2362179326 TillageDepth_Def "Default Tillage Depth of Machine Element below soil surface, value increases with depth";
CM_ SG_ 2362179326 TillageDepth_Act "Actual Tillage Depth of Machine Element below soil surface, value increases with depth";
CM_ SG_ 2362179326 SetTillageDepth_Set "Setpoint Tillage Depth of Machine Element below soil surface, value increases with depth";
CM_ SG_ 2362179326 AppRateCountPerTime_Max "Maximum Application Rate specified as count per time";
CM_ SG_ 2362179326 AppRateCountPerTime_Min "Minimum Application Rate specified as count per time";
CM_ SG_ 2362179326 AppRateCountPerTime_Def "Default Application Rate specified as count per time";
CM_ SG_ 2362179326 AppRateCountPerTime_Act "Actual Application Rate specified as count per time";
CM_ SG_ 2362179326 AppRateCountPerTime_Set "Setpoint Application Rate specified as count per time";
CM_ SG_ 2362179326 AppRateMassPerTime_Max "Maximum Application Rate specified as mass per time";
CM_ SG_ 2362179326 AppRateMassPerTime_Min "Minimum Application Rate specified as mass per time";
CM_ SG_ 2362179326 AppRateMassPerTime_Def "Defaut Application Rate specified as mass per time";
CM_ SG_ 2362179326 AppRateMassPerTime_Act "Actual Application Rate specified as mass per time";
CM_ SG_ 2362179326 AppRateMassPerTime_Set "Setpoint Application Rate specified as mass per time";
CM_ SG_ 2362179326 AppRateVolumePerTime_Max "Maximum Application Rate specified as volume per time";
CM_ SG_ 2362179326 AppRateVolumePerTime_Min "Minimum Application Rate specified as volume per time";
CM_ SG_ 2362179326 AppRateVolumePerTime_Def "Default Application Rate specified as volume per time";
CM_ SG_ 2362179326 AppRateVolumePerTime_Act "Actual Application Rate specified as volume per time";
CM_ SG_ 2362179326 AppRateVolumePerTime_Set "Setpoint Application Rate specified as volume per time";
CM_ SG_ 2362179326 AppRateVolumePerMass_Max "Maximum Application Rate specified as volume per mass";
CM_ SG_ 2362179326 AppRateVolumePerMass_Min "Minimum Application Rate specified as volume per mass";
CM_ SG_ 2362179326 AppRateVolumePerMass_Def "Default Application Rate specified as volume per mass";
CM_ SG_ 2362179326 AppRateVolumePerMass_Act "Actual Application Rate specified as volume per mass";
CM_ SG_ 2362179326 AppRateVolumePerMass_Set "Setpoint Application Rate specified as volume per mass";
CM_ SG_ 2362179326 AppRateMassPerMass_Max "Maximum Application Rate specified as mass per mass";
CM_ SG_ 2362179326 AppRateMassPerMass_Min "Minimum Application Rate specified as mass per mass";
CM_ SG_ 2362179326 AppRateMassPerMass_Def "Default Application Rate specified as mass per mass";
CM_ SG_ 2362179326 AppRateMassPerMass_Act "Actual Application Rate specified as mass per mass";
CM_ SG_ 2362179326 AppRateMassPerMass_Set "Setpoint Application Rate specified as mass per mass";
CM_ SG_ 2362179326 AppRateVolumePerVolume_Max "Maximum Application Rate specified as volume per volume";
CM_ SG_ 2362179326 AppRateVolumePerVolume_Min "Minimum Application Rate specified as volume per volume";
CM_ SG_ 2362179326 AppRateVolumePerVolume_Def "Default Application Rate specified as volume per volume";
CM_ SG_ 2362179326 AppRateVolumePerVolume_Act "Actual Application Rate specified as volume per volume";
CM_ SG_ 2362179326 AppRateVolumePerVolume_Set "Setpoint Application Rate specified as volume per volume";
CM_ SG_ 2362179326 AppRateDistance_Max "Maximum Application Rate specified as distance";
CM_ SG_ 2362179326 AppRateDistance_Min "Minimum Application Rate specified as distance";
CM_ SG_ 2362179326 AppRateDistance_Def "Default Application Rate specified as distance";
CM_ SG_ 2362179326 AppRateDistance_Act "Actual Application Rate specified as distance";
CM_ SG_ 2362179326 SetAppRateDistance_Set "Setpoint Application Rate specified as distance";
CM_ SG_ 2362179326 AppRateCountPerArea_Max "Maximum Application Rate specified as count per area";
CM_ SG_ 2362179326 AppRateCountPerArea_Min "Minimum Application Rate specified as count per area";
CM_ SG_ 2362179326 AppRateCountPerArea_Def "Default Application Rate specified as count per area";
CM_ SG_ 2362179326 AppRateCountPerArea_Act "Actual Application Rate specified as count per area";
CM_ SG_ 2362179326 AppRateCountPerArea_Set "Setpoint Application Rate specified as count per area";
CM_ SG_ 2362179326 AppRateMassPerArea_Max "Maximum Application Rate specified as mass per area";
CM_ SG_ 2362179326 AppRateMassPerArea_Min "Minimum Application Rate specified as mass per area";
CM_ SG_ 2362179326 AppRateMassPerArea_Def "Default Application Rate specified as mass per area";
CM_ SG_ 2362179326 AppRateMassPerArea_Act "Actual Application Rate specified as mass per area";
CM_ SG_ 2362179326 AppRateMassPerArea_Set "Setpoint Application Rate specified as mass per area";
CM_ SG_ 2362179326 AppRateVolumePerArea_Max "Maximum Application Rate specified as volume per area";
CM_ SG_ 2362179326 AppRateVolumePerArea_Min "Minimum Application Rate specified as volume per area";
CM_ SG_ 2362179326 AppRateVolumePerArea_Def "Default Application Rate specified as volume per area";
CM_ SG_ 2362179326 AppRateVolumePerArea_Act "Actual Application Rate specified as volume per area";
CM_ SG_ 2362179326 AppRateVolumePerArea_Set "Setpoint Application Rate specified as volume per area";
CM_ SG_ 2362179326 DataLogDistanceInterval "Distance interval for data log in mm, 0 stops measurement.";
CM_ SG_ 2362179326 DataLogTimeInterval "Time interval for data log in ms, 0 stops measurement, 100 ms is minimum time interval.";
CM_ SG_ 2362179326 DestinationElementNumber "Device Element Number";
CM_ SG_ 2362179326 NumberOfBooms "Number of booms for section control";
CM_ SG_ 2362179326 NumberOfSection "Number of sections across all booms for section control";
CM_ BO_ 2365408254 "Machine Selected Speed Command";
CM_ SG_ 2365408254 MachineSelSpeedSetpointCommand "Machine selected speed setpoint command";
CM_ SG_ 2365408254 MachineSelSpeedSetpointLimit "Machine selected speed setpoint limit";
CM_ SG_ 2365408254 MachineSelDirectionCommand "Machine selected direction command";
CM_ BO_ 2364547838 "Machine selected speed";
CM_ SG_ 2364547838 MachineSelectedSpeed "Machine selected Speed";
CM_ SG_ 2364547838 MachineSelectedDistance "Machine selected Distance";
CM_ SG_ 2364547838 MachineSelectedDirection "Machine selected direction";
CM_ SG_ 2364547838 MachineSelectedSpeedSource "Machine selected speed source";
CM_ SG_ 2364547838 MachineSelectedSpeedLimitStatus "Machine selected speed limit status";
CM_ BO_ 2566801406 "Maintain Power";
CM_ BO_ 2566787070 "Language Command";
CM_ BO_ 2365459198 "Tractor control command tractor response (previoulsy: Implement remote control command Tractor response)";
CM_ SG_ 2365459198 TractorControlLimitStatus1 "Parameter used to report the tractor ECUs present limit status associated with a parameter whose commands are persistent";
CM_ SG_ 2365459198 TractorControlLimitStatus2 "Parameter used to report the tractor ECUs present limit status associated with a parameter whose commands are persistent";
CM_ BO_ 2365459454 "Tractor control mode command (previously: Implement remote control command)";
CM_ BO_ 2365391616 "Implement operating state command";
CM_ BO_ 2566734590 "ISOBUS compliance certification";
CM_ SG_ 2566734590 CertTypeTCSectionControlWSMember "Parameter used to indicate the type of compliance test performed. ";
CM_ SG_ 2566734590 CertTypeTCSectionControl "Parameter used to indicate the type of compliance test performed. ";
CM_ SG_ 2566734590 CertTypeSeqControlMaster "Parameter used to indicate the type of compliance test performed. ";
CM_ SG_ 2566734590 CertTypeSecControlClient "Parameter used to indicate the type of compliance test performed. ";
CM_ SG_ 2566734590 CertTypeFileClient "Parameter used to indicate the type of compliance test performed. ";
CM_ SG_ 2566734590 CertTypeDataLoggerWSMember "Parameter used to indicate the type of compliance test performed. ";
CM_ SG_ 2566734590 CertTypeDataLoggerWSMaster "Parameter used to indicate the type of compliance test performed. ";
CM_ SG_ 2566734590 CertTypeDataLogger "Parameter used to indicate the type of compliance test performed. ";
CM_ SG_ 2566734590 CertTypeAuxControlInUnit "Parameter used to indicate the type of compliance test performed.";
CM_ SG_ 2566734590 CertTypeAuxControlFunc "Parameter used to indicate the type of compliance test performed. ";
CM_ SG_ 2566734590 CertificationYear "ISOBUS compliance certification year";
CM_ SG_ 2566734590 CertificateRevision "ISOBUS compliance certificate revision";
CM_ SG_ 2566734590 CertificateLaboratoryType "ISOBUS compliance certificate laboratory type";
CM_ SG_ 2566734590 CertificationLaboratoryID "ISOBUS Compliance certification laboratory ID";
CM_ SG_ 2566734590 CertTypeVTWorkingSetMember "ISOBUS Compliance certification type - VT working set member";
CM_ SG_ 2566734590 CertTypeVTWorkingSetMaster "ISOBUS Compliance certification type - VT working set master";
CM_ SG_ 2566734590 CertTypeVirtualTerminal "ISOBUS Compliance certification type - Virtual terminal";
CM_ SG_ 2566734590 CertTypeClass3ECU "ISOBUS Compliance certification type - Class 3 ECU";
CM_ SG_ 2566734590 CertTypeTECUClass3 "ISOBUS Compliance certification type - TECU Class 3";
CM_ SG_ 2566734590 CertTypeTECUClass2 "ISOBUS Compliance certification type - TECU Class 2";
CM_ SG_ 2566734590 CertTypeTECUClass1 "ISOBUS Compliance certification type - TECU Class 1";
CM_ SG_ 2566734590 CertTypeMinimumECU "ISOBUS Compliance certification type - Minimum ECU";
CM_ SG_ 2566734590 CertTypeGPSReceiver "ISOBUS Compliance certification type - GPS receiver";
CM_ SG_ 2566734590 CertTypeFileServer "ISOBUS Compliance certification type - File server";
CM_ SG_ 2566734590 CertTypeTCWorkingSetMember "ISOBUS Compliance certification type - TC working set member";
CM_ SG_ 2566734590 CertTypeTCWorkingSetMaster "ISOBUS Compliance certification type - TC working set master";
CM_ SG_ 2566734590 CertTypeTaskController "ISOBUS Compliance certification type - Task Controller";
CM_ SG_ 2566734590 CertificationReferenceNumber "ISOBUS Compliance certification reference number";
CM_ BO_ 2365473534 "Hitch and PTO Commands";
CM_ BO_ 2360213246 "Guidance System Command";
CM_ SG_ 2360213246 CurvatureCommand "Desired course curvature over ground that a machine's steering system is required to achieve.";
CM_ SG_ 2360213246 CurvatureCommandStatus "This parameter indicates whether the guidance system is attempting to control steering with this command.";
CM_ BO_ 2563047166 "General Purpose valve command";
CM_ BO_ 2563112702 "General Purpose valve measured flow";
CM_ SG_ 2563112702 ValveLimitStatus "Parameter used to report the tractor ECUs present limit status associated with a parameter whose commands are persistent";
CM_ BO_ 2563178238 "General purpose valve estimated flow";
CM_ SG_ 2563178238 ValveLimitStatus "Parameter used to report the tractor ECUs present limit status associated with a parameter whose commands are persistent";
CM_ BO_ 2583168510 "This PGN conveys a comprehensive set of Global Navigation Satellite System (GNSS) parameters, including position 
information
";
CM_ SG_ 2583168510 SequenceID "An upward counting number used to tie related information together between different PGNs.
";
CM_ SG_ 2583168510 PositionDate "Days since January 1, 1970,  Date is relative to UTC Time";
CM_ SG_ 2583168510 PositionTime "24 hour clock, 0 =  midnight,  time is in UTC";
CM_ SG_ 2583168510 LatitudeLow "Latitude referenced to WGS-84";
CM_ SG_ 2583168510 LatitudeHigh "Latitude referenced to WGS-84";
CM_ SG_ 2583168510 LongitudeLow "Longitude referenced to WGS-84";
CM_ SG_ 2583168510 LongitudeHigh "Longitude referenced to WGS-84";
CM_ SG_ 2583168510 AltitudeLow "Altitude referenced to WGS-84";
CM_ SG_ 2583168510 AltitudeHigh "Altitude referenced to WGS-84";
CM_ SG_ 2583168510 NumberOfSVs "Numeric count, event counter, sequence counter";
CM_ SG_ 2583168510 HDOP "Dilution of Precision (DOP) indicates the contribution of satellite configuration geometry to positioning error
";
CM_ SG_ 2583168510 PDOP "Dilution of Precision (DOP) indicates the contribution of satellite configuration geometry to positioning error
";
CM_ SG_ 2583168510 GeoidalSeparation "The difference between the earth ellipsoid and mean-sea-level (geoid) defined by the reference datum used in the position solution ' -' = mean-sea-level below ellipsoid
";
CM_ SG_ 2583168510 NumberOfReferenceStations "Numeric count, event counter, sequence counter";
CM_ SG_ 2583168510 ReferenceStationID1 "Reference Station ID";
CM_ SG_ 2583168510 AgeOfDGNSSCorrections1 "Age of Differential corrections";
CM_ BO_ 2360147710 "Guidance Machine Status";
CM_ SG_ 2360147710 EstimatedCurvature "The machine steering system's estimate of the curvature of the current turn.";
CM_ SG_ 2360147710 MechanicalSystemLockout "The state of a lockout switch that allows operators to disable automatic steering system functions.";
CM_ SG_ 2360147710 SteeringSystemReadiness "The machine steering system indicates that it is free from faults that would preclude guidance system operation.";
CM_ SG_ 2360147710 SteeringInputPositionStatus "The machine steering system indicates if manual steering is in correct position for guidance to function.";
CM_ SG_ 2360147710 RequestResetCommandStatus "The machine steering system request to the automatic guidance system to change Curvature Command Status state.";
CM_ BO_ 2365475326 "Ground-based Speed and Distance";
CM_ BO_ 2628517630 "File Server to Client";
CM_ SG_ 2628517630 FSServerCommand "File Server Command";
CM_ SG_ 2628517630 VI_TAN "Transaction Number for Volume Initialization";
CM_ SG_ 2628517630 DF_TAN "Transaction Number for Delete File";
CM_ SG_ 2628517630 GSP_VersionNumber "The version of ISO11783-13 that this File Server meets.";
CM_ SG_ 2628517630 CCD_TAN "Transaction Number for Change Current Directory";
CM_ SG_ 2628517630 GCD_TAN "Transaction Number for Get Current Directory";
CM_ SG_ 2628517630 FDT_TAN "Transaction Number for Get File Data & Time";
CM_ SG_ 2628517630 SA_TAN "Transaction Number for Set File Attributes";
CM_ SG_ 2628517630 GA_TAN "Transaction Number for Get File Attributes";
CM_ SG_ 2628517630 MF_TAN "Transaction Number for Move File";
CM_ SG_ 2628517630 CF_TAN "Transaction Number for Close File";
CM_ SG_ 2628517630 WF_TAN "Transaction Number for Write File";
CM_ SG_ 2628517630 RF_TAN "Transaction Number for Rename File";
CM_ SG_ 2628517630 SF_TAN "Transaction Number for Seek File";
CM_ SG_ 2628517630 OF_TAN "Transaction Number for Open File";
CM_ SG_ 2628517630 FSBusyReading "Busy reading";
CM_ SG_ 2628517630 FSBusyWriting "Busy writing";
CM_ SG_ 2628517630 VI_ErrorCode "Error Code for Volume Initialization";
CM_ SG_ 2628517630 DF_ErrorCode "Error Code for Delete File";
CM_ SG_ 2628517630 GSP_MaxNrSimultaneousFilesOpen "The number of files that can maximally be opened simultaneous at the File Server.";
CM_ SG_ 2628517630 CCD_ErrorCode "Error Code for Change Current Directory";
CM_ SG_ 2628517630 GCD_ErrorCode "ErrorCode for Get Current Directory";
CM_ SG_ 2628517630 SA_ErrorCode "Error Code for Set File Attribute";
CM_ SG_ 2628517630 GA_ErrorCode "Error Code for Get File Attribute";
CM_ SG_ 2628517630 MF_ErrorCode "Error Code for Move File";
CM_ SG_ 2628517630 CF_ErrorCode "Error Code for Close File";
CM_ SG_ 2628517630 WF_ErrorCode "Error Code for Write File";
CM_ SG_ 2628517630 OF_ErrorCode "Error Code for Open File";
CM_ SG_ 2628517630 FSNumberOfOpenFiles "Number of open files";
CM_ SG_ 2628517630 SF_ErrorCode "ErrorCode for Seek File";
CM_ SG_ 2628517630 RF_ErrorCode "Error Code for Read File";
CM_ SG_ 2628517630 FDT_ErrorCode "Error Code for Get File Data & Time";
CM_ SG_ 2628517630 WF_Count "Number of written bytes";
CM_ SG_ 2628517630 GSP_SupportMultipleVolumes "File Server Capabilities for Get File Server Properties";
CM_ SG_ 2628517630 RF_Count "Number of read bytes or number of read directory entries";
CM_ SG_ 2628517630 GCD_TotalSpace "Total Volume Space for Get Current Directory";
CM_ SG_ 2628517630 OF_Handle "Handle for Open File";
CM_ SG_ 2628517630 GA_ATTR_ReadOnly "File Attribute Read-OnlyFile Attribute Read-Only";
CM_ SG_ 2628517630 FDT_DateDay "Day of File Date";
CM_ SG_ 2628517630 GA_ATTR_Hidden "File Attribute HiddenFile Attribute Hidden";
CM_ SG_ 2628517630 GA_ATTR_IsVolume "File Attribute SystemFile Attribute System";
CM_ SG_ 2628517630 VI_ATTR_Directory "File Attribute DirectoryFile Attribute DirectoryFile Attribute DirectoryFile Attribute Directory";
CM_ SG_ 2628517630 GA_ATTR_SupportsLongFilenames "File Attribute ArchiveFile Attribute Archive";
CM_ SG_ 2628517630 FDT_DateMonth "Month of File Date";
CM_ SG_ 2628517630 GA_ATTR_VolumeRemovable "Attribute Removable MediaAttribute Removable Media";
CM_ SG_ 2628517630 GA_Size "The number of bytes in a file.";
CM_ SG_ 2628517630 SF_Position "Position of Seek File response";
CM_ SG_ 2628517630 FDT_DateYear "Year of File Date";
CM_ SG_ 2628517630 FDT_TimeSeconds "Day of File Time";
CM_ SG_ 2628517630 FDT_TimeMinutes "Minutes of File Time";
CM_ SG_ 2628517630 FDT_TimeHour "Hour of File Time";
CM_ SG_ 2628517630 GCD_FreeSpace "Free Volume Space for Get Current Directory";
CM_ SG_ 2628517630 GCD_PathName "Length of path name string for Get Current Directory";
BA_DEF_ BO_  "GenMsgCycleTimeFast" INT 0 3600000;
BA_DEF_ SG_  "SigType" ENUM  "Default","Range","RangeSigned","ASCII","Discrete","Control","ReferencePGN","DTC","StringDelimiter","StringLength","StringLengthControl";
BA_DEF_ SG_  "GenSigStartValue" INT 0 10000;
BA_DEF_ SG_  "GenSigSendType" ENUM  "Cyclic","OnWrite","reserved","OnChange","reserved","reserved","reserved","NoSigSendType";
BA_DEF_ SG_  "GenSigILSupport" ENUM  "Yes","No";
BA_DEF_ SG_  "GenSigEVName" STRING ;
BA_DEF_ SG_  "SPN" INT 0 524287;
BA_DEF_ SG_  "DDI" INT 0 65535;
BA_DEF_ SG_  "SAEDocument" STRING ;
BA_DEF_ BO_  "GenMsgStartDelayTime" INT 0 100000;
BA_DEF_ BO_  "GenMsgILSupport" ENUM  "Yes","No";
BA_DEF_ BO_  "GenMsgRequestable" INT 0 1;
BA_DEF_ BO_  "GenMsgSendType" ENUM  "cyclic","reserved","cyclicIfActive","reserved","reserved","reserved","reserved","reserved","noMsgSendType";
BA_DEF_ BO_  "VFrameFormat" ENUM  "StandardCAN","ExtendedCAN","reserved","J1939PG";
BA_DEF_ BO_  "SingleFrame" INT 0 1;
BA_DEF_ BO_  "GenMsgCycleTime" INT 0 3600000;
BA_DEF_ BO_  "SAE_Document" STRING ;
BA_DEF_ SG_  "SystemSignalLongSymbol" STRING ;
BA_DEF_DEF_  "GenMsgCycleTimeFast" 0;
BA_DEF_DEF_  "SigType" "Default";
BA_DEF_DEF_  "GenSigStartValue" 0;
BA_DEF_DEF_  "GenSigSendType" "NoSigSendType";
BA_DEF_DEF_  "GenSigILSupport" "Yes";
BA_DEF_DEF_  "GenSigEVName" "Env@Nodename_@Signame";
BA_DEF_DEF_  "SPN" 0;
BA_DEF_DEF_  "DDI" 0;
BA_DEF_DEF_  "SAEDocument" "";
BA_DEF_DEF_  "GenMsgStartDelayTime" 0;
BA_DEF_DEF_  "GenMsgILSupport" "Yes";
BA_DEF_DEF_  "GenMsgRequestable" 1;
BA_DEF_DEF_  "GenMsgSendType" "noMsgSendType";
BA_DEF_DEF_  "VFrameFormat" "J1939PG";
BA_DEF_DEF_  "SingleFrame" 1;
BA_DEF_DEF_  "GenMsgCycleTime" 0;
BA_DEF_DEF_  "SAE_Document" "";
BA_DEF_DEF_  "SystemSignalLongSymbol" "";
BA_ "GenMsgCycleTime" BO_ 2365408254 100;
BA_ "GenMsgCycleTime" BO_ 2566801406 100;
BA_ "GenMsgCycleTime" BO_ 2566787070 100;
BA_ "GenMsgCycleTime" BO_ 2365459198 100;
BA_ "GenMsgCycleTime" BO_ 2365459454 100;
BA_ "GenMsgCycleTime" BO_ 2365473534 1000;
BA_ "GenMsgCycleTime" BO_ 2360213246 100;
BA_ "GenMsgCycleTime" BO_ 2563047166 1000;
BA_ "GenMsgCycleTime" BO_ 2563112702 100;
BA_ "GenMsgCycleTime" BO_ 2563178238 100;
BA_ "SingleFrame" BO_ 2583168510 0;
BA_ "GenMsgCycleTime" BO_ 2583168510 100;
BA_ "GenMsgCycleTime" BO_ 2360147710 100;
BA_ "GenMsgCycleTime" BO_ 2365475326 100;
BA_ "GenSigStartValue" SG_ 2362179326 NumberOfControlChannels 255;
BA_ "SPN" SG_ 2362179326 Command 1642;
BA_ "SAEDocument" SG_ 2362179326 Command "J1939-73";
BA_ "SAEDocument" SG_ 2362179326 Status "J1939-73";
BA_ "SPN" SG_ 2362179326 LanguageCodeCmd 2410;
BA_ "SigType" SG_ 2362179326 LanguageCodeCmd 3;
BA_ "GenSigStartValue" SG_ 2362179326 BootTimeTC 255;
BA_ "GenSigStartValue" SG_ 2362179326 Documentation 1;
BA_ "GenSigStartValue" SG_ 2362179326 TimeAndPositionForDataLogging 1;
BA_ "GenSigStartValue" SG_ 2362179326 TC_GEO_DefinitionPositionBasedCo 1;
BA_ "SystemSignalLongSymbol" SG_ 2362179326 TC_GEO_DefinitionPositionBasedCo "TC_GEO_DefinitionPositionBasedControl";
BA_ "GenSigStartValue" SG_ 2362179326 PeerControlAssignment 1;
BA_ "GenSigStartValue" SG_ 2362179326 ImplementSectionControl 1;
BA_ "SPN" SG_ 2362179326 TimeFormatCmd 2413;
BA_ "SigType" SG_ 2362179326 TimeFormatCmd 4;
BA_ "SPN" SG_ 2362179326 DecimalSymbolCmd 2411;
BA_ "SigType" SG_ 2362179326 DecimalSymbolCmd 4;
BA_ "SPN" SG_ 2362179326 DateFormatCmd 2412;
BA_ "SigType" SG_ 2362179326 DateFormatCmd 1;
BA_ "DDI" SG_ 2362179326 RequestDefaultProcessData 57343;
BA_ "DDI" SG_ 2362179326 PGNBasedData 57342;
BA_ "DDI" SG_ 2362179326 LastUnloadedWeight 321;
BA_ "DDI" SG_ 2362179326 LastLoadedWeight 320;
BA_ "DDI" SG_ 2362179326 IneffectiveTotalDieselExhaustFlu 319;
BA_ "SystemSignalLongSymbol" SG_ 2362179326 IneffectiveTotalDieselExhaustFlu "IneffectiveTotalDieselExhaustFluidConsumption";
BA_ "DDI" SG_ 2362179326 EffectiveTotalDieselExhaustFluid 318;
BA_ "SystemSignalLongSymbol" SG_ 2362179326 EffectiveTotalDieselExhaustFluid "EffectiveTotalDieselExhaustFluidConsumption";
BA_ "DDI" SG_ 2362179326 IneffectiveTotalFuelConsumption 317;
BA_ "DDI" SG_ 2362179326 EffectiveTotalFuelConsumption 316;
BA_ "DDI" SG_ 2362179326 AveragePercentageCropDryMatter 315;
BA_ "DDI" SG_ 2362179326 ActualPercentageCropDryMatter 314;
BA_ "DDI" SG_ 2362179326 MaximumRelativeYieldPotential 313;
BA_ "DDI" SG_ 2362179326 MinimumRelativeYieldPotential 312;
BA_ "DDI" SG_ 2362179326 RelativeYieldPotential 311;
BA_ "DDI" SG_ 2362179326 MaximumPercentageApplicationRate 310;
BA_ "DDI" SG_ 2362179326 MinimumPercentageApplicationRate 309;
BA_ "DDI" SG_ 2362179326 ActualPercentageApplicationRate 308;
BA_ "DDI" SG_ 2362179326 TrueRotationPointYOffset 307;
BA_ "DDI" SG_ 2362179326 TrueRotationPointXOffset 306;
BA_ "DDI" SG_ 2362179326 SetpointCondensedWorkState241to2 305;
BA_ "SystemSignalLongSymbol" SG_ 2362179326 SetpointCondensedWorkState241to2 "SetpointCondensedWorkState241to256";
BA_ "DDI" SG_ 2362179326 SetpointCondensedWorkState225to2 304;
BA_ "SystemSignalLongSymbol" SG_ 2362179326 SetpointCondensedWorkState225to2 "SetpointCondensedWorkState225to240";
BA_ "DDI" SG_ 2362179326 SetpointCondensedWorkState209to2 303;
BA_ "SystemSignalLongSymbol" SG_ 2362179326 SetpointCondensedWorkState209to2 "SetpointCondensedWorkState209to224";
BA_ "DDI" SG_ 2362179326 SetpointCondensedWorkState193to2 302;
BA_ "SystemSignalLongSymbol" SG_ 2362179326 SetpointCondensedWorkState193to2 "SetpointCondensedWorkState193to208";
BA_ "DDI" SG_ 2362179326 SetpointCondensedWorkState177to1 301;
BA_ "SystemSignalLongSymbol" SG_ 2362179326 SetpointCondensedWorkState177to1 "SetpointCondensedWorkState177to192";
BA_ "DDI" SG_ 2362179326 SetpointCondensedWorkState161to1 300;
BA_ "SystemSignalLongSymbol" SG_ 2362179326 SetpointCondensedWorkState161to1 "SetpointCondensedWorkState161to176";
BA_ "DDI" SG_ 2362179326 SetpointCondensedWorkState145to1 299;
BA_ "SystemSignalLongSymbol" SG_ 2362179326 SetpointCondensedWorkState145to1 "SetpointCondensedWorkState145to160";
BA_ "DDI" SG_ 2362179326 SetpointCondensedWorkState129to1 298;
BA_ "SystemSignalLongSymbol" SG_ 2362179326 SetpointCondensedWorkState129to1 "SetpointCondensedWorkState129to144";
BA_ "DDI" SG_ 2362179326 SetpointCondensedWorkState113to1 297;
BA_ "SystemSignalLongSymbol" SG_ 2362179326 SetpointCondensedWorkState113to1 "SetpointCondensedWorkState113to128";
BA_ "DDI" SG_ 2362179326 SetpointCondensedWorkState97to11 296;
BA_ "SystemSignalLongSymbol" SG_ 2362179326 SetpointCondensedWorkState97to11 "SetpointCondensedWorkState97to112";
BA_ "DDI" SG_ 2362179326 SetpointCondensedWorkState81to96 295;
BA_ "DDI" SG_ 2362179326 SetpointCondensedWorkState65to80 294;
BA_ "DDI" SG_ 2362179326 SetpointCondensedWorkState49to64 293;
BA_ "DDI" SG_ 2362179326 SetpointCondensedWorkState33to48 292;
BA_ "DDI" SG_ 2362179326 SetpointCondensedWorkState17to32 291;
BA_ "DDI" SG_ 2362179326 SetpointCondensedWorkState1to16 290;
BA_ "DDI" SG_ 2362179326 SetpointWorkState 289;
BA_ "DDI" SG_ 2362179326 LifetimeUncutTotalCount 286;
BA_ "DDI" SG_ 2362179326 LifetimePrecutTotalCount 285;
BA_ "DDI" SG_ 2362179326 UncutTotalCount 284;
BA_ "DDI" SG_ 2362179326 PrecutTotalCount 283;
BA_ "DDI" SG_ 2362179326 LifetimeThreshingEngagementTotal 282;
BA_ "SystemSignalLongSymbol" SG_ 2362179326 LifetimeThreshingEngagementTotal "LifetimeThreshingEngagementTotalTime";
BA_ "DDI" SG_ 2362179326 LifetimeYieldTotalLintCottonMass 281;
BA_ "DDI" SG_ 2362179326 LifetimeYieldTotalSeedCottonMass 280;
BA_ "DDI" SG_ 2362179326 LifetimeYieldTotalDryMass 279;
BA_ "DDI" SG_ 2362179326 LifetimeAverageFuelConsumptionPe 278;
BA_ "SystemSignalLongSymbol" SG_ 2362179326 LifetimeAverageFuelConsumptionPe "LifetimeAverageFuelConsumptionPerArea";
BA_ "DDI" SG_ 2362179326 LifetimeAverageFuelConsumpt_0000 277;
BA_ "SystemSignalLongSymbol" SG_ 2362179326 LifetimeAverageFuelConsumpt_0000 "LifetimeAverageFuelConsumptionPerTime";
BA_ "DDI" SG_ 2362179326 LifetimeFuelConsumption 276;
BA_ "DDI" SG_ 2362179326 LifetimeIneffectiveTotalTime 275;
BA_ "DDI" SG_ 2362179326 LifetimeEffectiveTotalTime 274;
BA_ "DDI" SG_ 2362179326 LifetimeIneffectiveTotalDistance 273;
BA_ "DDI" SG_ 2362179326 LifetimeTotalDistance 272;
BA_ "DDI" SG_ 2362179326 LifetimeTotalArea 271;
BA_ "DDI" SG_ 2362179326 LifetimeYieldTotalCount 270;
BA_ "DDI" SG_ 2362179326 LifetimeYieldTotalMass 269;
BA_ "DDI" SG_ 2362179326 LifetimeYieldTotalVolume 268;
BA_ "DDI" SG_ 2362179326 LifetimeApplicationTotalCount 267;
BA_ "DDI" SG_ 2362179326 LifetimeApplicationTotalMass 266;
BA_ "DDI" SG_ 2362179326 RemainingArea 265;
BA_ "DDI" SG_ 2362179326 ConnectorPivotXOffset 264;
BA_ "DDI" SG_ 2362179326 AverageYieldMassPerArea 263;
BA_ "DDI" SG_ 2362179326 AverageCropMoisture 262;
BA_ "DDI" SG_ 2362179326 AverageYieldMassPerTime 261;
BA_ "DDI" SG_ 2362179326 YieldLeadIgnoreTime 260;
BA_ "DDI" SG_ 2362179326 YieldLagIgnoreTime 259;
BA_ "DDI" SG_ 2362179326 HydraulicOilTemperature 258;
BA_ "DDI" SG_ 2362179326 MaximumSeparationFanRotationalSp 257;
BA_ "SystemSignalLongSymbol" SG_ 2362179326 MaximumSeparationFanRotationalSp "MaximumSeparationFanRotationalSpeed";
BA_ "DDI" SG_ 2362179326 MinimumSeparationFanRotationalSp 256;
BA_ "SystemSignalLongSymbol" SG_ 2362179326 MinimumSeparationFanRotationalSp "MinimumSeparationFanRotationalSpeed";
BA_ "DDI" SG_ 2362179326 ActualSeparationFanRotationalSpe 255;
BA_ "SystemSignalLongSymbol" SG_ 2362179326 ActualSeparationFanRotationalSpe "ActualSeparationFanRotationalSpeed";
BA_ "DDI" SG_ 2362179326 SetpointSeparationFanRotationalS 254;
BA_ "SystemSignalLongSymbol" SG_ 2362179326 SetpointSeparationFanRotationalS "SetpointSeparationFanRotationalSpeed";
BA_ "DDI" SG_ 2362179326 MaximumConcaveClearance 253;
BA_ "DDI" SG_ 2362179326 MinimumConcaveClearance 252;
BA_ "DDI" SG_ 2362179326 ActualConcaveClearance 251;
BA_ "DDI" SG_ 2362179326 SetpointConcaveClearance 250;
BA_ "DDI" SG_ 2362179326 MaximumChafferClearance 249;
BA_ "DDI" SG_ 2362179326 MinimumChafferClearance 248;
BA_ "DDI" SG_ 2362179326 ActualChafferClearance 247;
BA_ "DDI" SG_ 2362179326 SetpointChafferClearance 246;
BA_ "DDI" SG_ 2362179326 MaximumSieveClearance 245;
BA_ "DDI" SG_ 2362179326 MinimumSieveClearance 244;
BA_ "DDI" SG_ 2362179326 ActualSieveClearance 243;
BA_ "DDI" SG_ 2362179326 SetpointSieveClearance 242;
BA_ "DDI" SG_ 2362179326 CropTemperature 241;
BA_ "DDI" SG_ 2362179326 ActualUnLoadingSystemStatus 240;
BA_ "DDI" SG_ 2362179326 YieldHoldStatus 239;
BA_ "DDI" SG_ 2362179326 ActualHeaderRotationalSpeedStatu 238;
BA_ "SystemSignalLongSymbol" SG_ 2362179326 ActualHeaderRotationalSpeedStatu "ActualHeaderRotationalSpeedStatus";
BA_ "DDI" SG_ 2362179326 ActualHeaderWorkingHeightStatus 237;
BA_ "DDI" SG_ 2362179326 ThreshingEngagementTotalTime 236;
BA_ "DDI" SG_ 2362179326 MaximumGrossWeight 235;
BA_ "DDI" SG_ 2362179326 MinimumGrossWeight 234;
BA_ "DDI" SG_ 2362179326 GrossWeightState 233;
BA_ "DDI" SG_ 2362179326 ActualGrossWeight 232;
BA_ "DDI" SG_ 2362179326 SetpointNetWeight 231;
BA_ "DDI" SG_ 2362179326 NetWeightState 230;
BA_ "DDI" SG_ 2362179326 ActualNetWeight 229;
BA_ "DDI" SG_ 2362179326 MaximumWorkingLength 228;
BA_ "DDI" SG_ 2362179326 MinimumWorkingLength 227;
BA_ "DDI" SG_ 2362179326 ActualWorkingLength 226;
BA_ "DDI" SG_ 2362179326 SetpointWorkingLength 225;
BA_ "DDI" SG_ 2362179326 DeltaT 224;
BA_ "DDI" SG_ 2362179326 LastBaleMass 223;
BA_ "DDI" SG_ 2362179326 LastBaleTagNumber 222;
BA_ "DDI" SG_ 2362179326 LastBaleAppliedPreservative 221;
BA_ "DDI" SG_ 2362179326 LastBaleAverageBaleCompressionPl 220;
BA_ "SystemSignalLongSymbol" SG_ 2362179326 LastBaleAverageBaleCompressionPl "LastBaleAverageBaleCompressionPlungerLoad";
BA_ "DDI" SG_ 2362179326 ActualBaleCompressionPlungerLoad 219;
BA_ "DDI" SG_ 2362179326 SetpointBaleCompressionPlungerLo 218;
BA_ "SystemSignalLongSymbol" SG_ 2362179326 SetpointBaleCompressionPlungerLo "SetpointBaleCompressionPlungerLoad";
BA_ "DDI" SG_ 2362179326 LastBaleAverageHydraulicPressure 217;
BA_ "DDI" SG_ 2362179326 ActualBaleHydraulicPressure 216;
BA_ "DDI" SG_ 2362179326 LifetimeWorkingHours 215;
BA_ "DDI" SG_ 2362179326 LifetimeBaleCount 214;
BA_ "DDI" SG_ 2362179326 LastBaleAverageStrokesPerFlake 213;
BA_ "DDI" SG_ 2362179326 LastBaleAverageMoisture 212;
BA_ "DDI" SG_ 2362179326 LastBaleFlakesPerBale 211;
BA_ "DDI" SG_ 2362179326 SkyConditions 210;
BA_ "DDI" SG_ 2362179326 AirHumidity 209;
BA_ "SAEDocument" SG_ 2362179326 WindDirection "NMEA2000";
BA_ "SigType" SG_ 2362179326 WindDirection 1;
BA_ "DDI" SG_ 2362179326 WindDirection 208;
BA_ "SAEDocument" SG_ 2362179326 WindSpeed "NMEA2000";
BA_ "SigType" SG_ 2362179326 WindSpeed 1;
BA_ "DDI" SG_ 2362179326 WindSpeed 207;
BA_ "DDI" SG_ 2362179326 SCTurnOffTime 206;
BA_ "DDI" SG_ 2362179326 SCTurnOnTime_ 205;
BA_ "DDI" SG_ 2362179326 MaximumTankAgitationPressure 204;
BA_ "DDI" SG_ 2362179326 MinimumTankAgitationPressure 203;
BA_ "DDI" SG_ 2362179326 ActualTankAgitationPressure 202;
BA_ "DDI" SG_ 2362179326 SetpointTankAgitationPressure 201;
BA_ "DDI" SG_ 2362179326 MaximumPumpOutputPressure 200;
BA_ "DDI" SG_ 2362179326 MinimumPumpOutputPressure 199;
BA_ "DDI" SG_ 2362179326 ActualPumpOutputPressure 198;
BA_ "DDI" SG_ 2362179326 SetpointPumpOutputPressure 197;
BA_ "DDI" SG_ 2362179326 MaximumProductPressure 196;
BA_ "DDI" SG_ 2362179326 MinimumProductPressure 195;
BA_ "DDI" SG_ 2362179326 ActualProductPressure 194;
BA_ "DDI" SG_ 2362179326 SetpointProductPressure 193;
BA_ "DDI" SG_ 2362179326 AmbientTemperature 192;
BA_ "DDI" SG_ 2362179326 LintTurnoutPercentage 191;
BA_ "DDI" SG_ 2362179326 YieldTotalLintCottonMass 190;
BA_ "DDI" SG_ 2362179326 YieldTotalSeedCottonMass 189;
BA_ "DDI" SG_ 2362179326 LintCottonMassPerTimeYield 188;
BA_ "DDI" SG_ 2362179326 SeedCottonMassPerTimeYield 187;
BA_ "DDI" SG_ 2362179326 LintCottonMassPerAreaYield 186;
BA_ "DDI" SG_ 2362179326 SeedCottonMassPerAreaYield 185;
BA_ "DDI" SG_ 2362179326 RefMoistureForDryMass 184;
BA_ "DDI" SG_ 2362179326 YieldTotalDryMass 183;
BA_ "DDI" SG_ 2362179326 DryMassPerTimeYield 182;
BA_ "DDI" SG_ 2362179326 DryMassPerAreaYield 181;
BA_ "DDI" SG_ 2362179326 DRP2GroundDistance 180;
BA_ "DDI" SG_ 2362179326 ActualCulturalPractice 179;
BA_ "DDI" SG_ 2362179326 ElementTypeInstance 178;
BA_ "DDI" SG_ 2362179326 ActualLengthOfCut 177;
BA_ "DDI" SG_ 2362179326 CondensedWorkState241to256 176;
BA_ "DDI" SG_ 2362179326 CondensedWorkState225to240 175;
BA_ "DDI" SG_ 2362179326 CondensedWorkState209to224 174;
BA_ "DDI" SG_ 2362179326 CondensedWorkState193to208 173;
BA_ "DDI" SG_ 2362179326 CondensedWorkState177to192 172;
BA_ "DDI" SG_ 2362179326 CondensedWorkState161to176 171;
BA_ "DDI" SG_ 2362179326 CondensedWorkState145to160 170;
BA_ "DDI" SG_ 2362179326 CondensedWorkState129to144 169;
BA_ "DDI" SG_ 2362179326 CondensedWorkState113to128 168;
BA_ "DDI" SG_ 2362179326 CondensedWorkState97to112 167;
BA_ "DDI" SG_ 2362179326 CondensedWorkState81to96 166;
BA_ "DDI" SG_ 2362179326 CondensedWorkState65to80 165;
BA_ "DDI" SG_ 2362179326 CondensedWorkState49to64 164;
BA_ "DDI" SG_ 2362179326 CondensedWorkState33to48 163;
BA_ "DDI" SG_ 2362179326 CondensedWorkState17to32 162;
BA_ "DDI" SG_ 2362179326 CondensedWorkState1to16 161;
BA_ "DDI" SG_ 2362179326 SectionControlState 160;
BA_ "DDI" SG_ 2362179326 NumberOfSubUnitsPerSection 159;
BA_ "DDI" SG_ 2362179326 PrescriptionControlState 158;
BA_ "DDI" SG_ 2362179326 ConnectorType 157;
BA_ "DDI" SG_ 2362179326 PhysicalObjectHeight 156;
BA_ "DDI" SG_ 2362179326 PhysicalObjectWidth 155;
BA_ "DDI" SG_ 2362179326 PhysicalObjectLength 154;
BA_ "DDI" SG_ 2362179326 NDVI 153;
BA_ "DDI" SG_ 2362179326 MinMassPerAreaAppRate 152;
BA_ "DDI" SG_ 2362179326 AreaPerTimeCapacity 151;
BA_ "DDI" SG_ 2362179326 FuelConsumptionPerArea 150;
BA_ "DDI" SG_ 2362179326 FuelConsumptionPerTime 149;
BA_ "DDI" SG_ 2362179326 TotalFuelConsumption 148;
BA_ "DDI" SG_ 2362179326 LogCount 147;
BA_ "DDI" SG_ 2362179326 PitchAngle 146;
BA_ "SigType" SG_ 2362179326 PitchAngle 1;
BA_ "SPN" SG_ 2362179326 PitchAngle 3318;
BA_ "SAEDocument" SG_ 2362179326 PitchAngle "J1939-71";
BA_ "DDI" SG_ 2362179326 RollAngle 145;
BA_ "SigType" SG_ 2362179326 RollAngle 1;
BA_ "SPN" SG_ 2362179326 RollAngle 3319;
BA_ "SAEDocument" SG_ 2362179326 RollAngle "J1939-71";
BA_ "DDI" SG_ 2362179326 YawAngle 144;
BA_ "DDI" SG_ 2362179326 ActualValueTimeLatency 143;
BA_ "DDI" SG_ 2362179326 SetpointTimeLatency 142;
BA_ "DDI" SG_ 2362179326 WorkState 141;
BA_ "DDI" SG_ 2362179326 PercentageAppRateSetpoint 140;
BA_ "DDI" SG_ 2362179326 DeviceCountCapacity 139;
BA_ "DDI" SG_ 2362179326 DeviceMassCapacity 138;
BA_ "DDI" SG_ 2362179326 DeviceVolumeCapacity 137;
BA_ "DDI" SG_ 2362179326 DeviceElementOffsetZ 136;
BA_ "DDI" SG_ 2362179326 DeviceElementOffsetY 135;
BA_ "DDI" SG_ 2362179326 DeviceElementOffsetX 134;
BA_ "DDI" SG_ 2362179326 AuxiliaryValveInvertPorts 133;
BA_ "DDI" SG_ 2362179326 AuxiliaryValveProgressivRetract 132;
BA_ "DDI" SG_ 2362179326 AuxiliaryValveProgressivExtend 131;
BA_ "DDI" SG_ 2362179326 AuxiliaryValveFloatThreshold 130;
BA_ "DDI" SG_ 2362179326 AuxiliaryValveRampRetractDown 129;
BA_ "DDI" SG_ 2362179326 AuxiliaryValveRampRetractUp 128;
BA_ "DDI" SG_ 2362179326 AuxiliaryValveRampExtendDown 127;
BA_ "DDI" SG_ 2362179326 AuxiliaryRampExtendUp 126;
BA_ "DDI" SG_ 2362179326 AuxiliaryValveScalingRetract 125;
BA_ "DDI" SG_ 2362179326 AuxiliaryValveScalingExtend 124;
BA_ "DDI" SG_ 2362179326 PrdoucDensityVolumePerCount 123;
BA_ "DDI" SG_ 2362179326 PrdoucDensityMassPerCount 122;
BA_ "DDI" SG_ 2362179326 PrdoucDensityMassPerArea 121;
BA_ "DDI" SG_ 2362179326 AccumulatedTimeOutWork 120;
BA_ "DDI" SG_ 2362179326 AccumulatedTimeInWork 119;
BA_ "DDI" SG_ 2362179326 AccumulatedDistanceOutWork 118;
BA_ "DDI" SG_ 2362179326 AccumulatedDistanceInWork 117;
BA_ "DDI" SG_ 2362179326 AccumulatedArea 116;
BA_ "DDI" SG_ 2362179326 BaleSize_Max 115;
BA_ "DDI" SG_ 2362179326 BaleSize_Min 114;
BA_ "DDI" SG_ 2362179326 BaleSize_Def 113;
BA_ "DDI" SG_ 2362179326 BaleSize_Act 112;
BA_ "DDI" SG_ 2362179326 BaleSize_Set 111;
BA_ "DDI" SG_ 2362179326 BaleHeight_Max 110;
BA_ "DDI" SG_ 2362179326 BaleHeight_Min 109;
BA_ "DDI" SG_ 2362179326 BaleHeight_Def 108;
BA_ "DDI" SG_ 2362179326 BaleHeight_Act 107;
BA_ "DDI" SG_ 2362179326 BaleHeight_Set 106;
BA_ "DDI" SG_ 2362179326 BaleWidth_Max 105;
BA_ "DDI" SG_ 2362179326 BaleWidth_Min 104;
BA_ "DDI" SG_ 2362179326 BaleWidth_Def 103;
BA_ "DDI" SG_ 2362179326 BaleWidth_Act 102;
BA_ "DDI" SG_ 2362179326 BaleWidth_Set 101;
BA_ "DDI" SG_ 2362179326 DirtMaterialInCropYield 100;
BA_ "DDI" SG_ 2362179326 MoistureInCropYield 99;
BA_ "DDI" SG_ 2362179326 CropYieldLoss 98;
BA_ "DDI" SG_ 2362179326 CropYieldLossCountPerTime 97;
BA_ "DDI" SG_ 2362179326 CropYieldLossMassPerTime 96;
BA_ "DDI" SG_ 2362179326 CropYieldLossVolumePerTime 95;
BA_ "DDI" SG_ 2362179326 CropYieldLossCountPerArea 94;
BA_ "DDI" SG_ 2362179326 CropYieldLossMassPerArea 93;
BA_ "DDI" SG_ 2362179326 CropYieldLossVolumePerArea 92;
BA_ "DDI" SG_ 2362179326 AccumulatedYieldAsCount 91;
BA_ "DDI" SG_ 2362179326 AccumulatedYieldAsMass 90;
BA_ "DDI" SG_ 2362179326 AccumulatedYieldAsVolume 89;
BA_ "DDI" SG_ 2362179326 YieldCountPerTime 88;
BA_ "DDI" SG_ 2362179326 YieldMassPerTime 87;
BA_ "DDI" SG_ 2362179326 YieldVolumePerTime 86;
BA_ "DDI" SG_ 2362179326 YieldCountPerArea 85;
BA_ "DDI" SG_ 2362179326 YieldMassPerArea 84;
BA_ "DDI" SG_ 2362179326 YieldVolumePerArea 83;
BA_ "DDI" SG_ 2362179326 AccumulatedAppAsCount 82;
BA_ "DDI" SG_ 2362179326 AccumulatedAppAsMass 81;
BA_ "DDI" SG_ 2362179326 AccumulatedAppAsVolume 80;
BA_ "DDI" SG_ 2362179326 ContentAsCount_Max 79;
BA_ "DDI" SG_ 2362179326 ContentAsCount_Act 78;
BA_ "DDI" SG_ 2362179326 ContentAsCount_Set 77;
BA_ "DDI" SG_ 2362179326 ContentAsMass_Max 76;
BA_ "DDI" SG_ 2362179326 ContentAsMass_Act 75;
BA_ "DDI" SG_ 2362179326 ContentAsMass_Set 74;
BA_ "DDI" SG_ 2362179326 ContentAsVolume_Max 73;
BA_ "DDI" SG_ 2362179326 ContentAsVolume_Act 72;
BA_ "DDI" SG_ 2362179326 ContentAsVolume_Set 71;
BA_ "DDI" SG_ 2362179326 WorkingWidth_Max 70;
BA_ "DDI" SG_ 2362179326 WorkingWidth_Min 69;
BA_ "DDI" SG_ 2362179326 WorkingWidth_Def 68;
BA_ "DDI" SG_ 2362179326 WorkingWidth_Act 67;
BA_ "DDI" SG_ 2362179326 WorkingWidth_Set 66;
BA_ "DDI" SG_ 2362179326 WorkingHeight_Max 65;
BA_ "DDI" SG_ 2362179326 WorkingHeight_Min 64;
BA_ "DDI" SG_ 2362179326 WorkingHeight_Def 63;
BA_ "DDI" SG_ 2362179326 WorkingHeight_Act 62;
BA_ "DDI" SG_ 2362179326 WorkingHeight_Set 61;
BA_ "DDI" SG_ 2362179326 SeedingDeph_Max 60;
BA_ "DDI" SG_ 2362179326 SeedingDeph_Min 59;
BA_ "DDI" SG_ 2362179326 SeedingDeph_Def 58;
BA_ "DDI" SG_ 2362179326 SeedingDeph_Act 57;
BA_ "DDI" SG_ 2362179326 SeedingDeph_Set 56;
BA_ "DDI" SG_ 2362179326 TillageDepth_Max 55;
BA_ "DDI" SG_ 2362179326 TillageDepth_Min 54;
BA_ "DDI" SG_ 2362179326 TillageDepth_Def 53;
BA_ "DDI" SG_ 2362179326 TillageDepth_Act 52;
BA_ "DDI" SG_ 2362179326 SetTillageDepth_Set 51;
BA_ "DDI" SG_ 2362179326 AppRateCountPerTime_Max 50;
BA_ "DDI" SG_ 2362179326 AppRateCountPerTime_Min 49;
BA_ "DDI" SG_ 2362179326 AppRateCountPerTime_Def 48;
BA_ "DDI" SG_ 2362179326 AppRateCountPerTime_Act 47;
BA_ "DDI" SG_ 2362179326 AppRateCountPerTime_Set 46;
BA_ "DDI" SG_ 2362179326 AppRateMassPerTime_Max 45;
BA_ "DDI" SG_ 2362179326 AppRateMassPerTime_Min 44;
BA_ "DDI" SG_ 2362179326 AppRateMassPerTime_Def 43;
BA_ "DDI" SG_ 2362179326 AppRateMassPerTime_Act 42;
BA_ "DDI" SG_ 2362179326 AppRateMassPerTime_Set 41;
BA_ "DDI" SG_ 2362179326 AppRateVolumePerTime_Max 40;
BA_ "DDI" SG_ 2362179326 AppRateVolumePerTime_Min 39;
BA_ "DDI" SG_ 2362179326 AppRateVolumePerTime_Def 38;
BA_ "DDI" SG_ 2362179326 AppRateVolumePerTime_Act 37;
BA_ "DDI" SG_ 2362179326 AppRateVolumePerTime_Set 36;
BA_ "DDI" SG_ 2362179326 AppRateVolumePerMass_Max 35;
BA_ "DDI" SG_ 2362179326 AppRateVolumePerMass_Min 34;
BA_ "DDI" SG_ 2362179326 AppRateVolumePerMass_Def 33;
BA_ "DDI" SG_ 2362179326 AppRateVolumePerMass_Act 32;
BA_ "DDI" SG_ 2362179326 AppRateVolumePerMass_Set 31;
BA_ "DDI" SG_ 2362179326 AppRateMassPerMass_Max 30;
BA_ "DDI" SG_ 2362179326 AppRateMassPerMass_Min 29;
BA_ "DDI" SG_ 2362179326 AppRateMassPerMass_Def 28;
BA_ "DDI" SG_ 2362179326 AppRateMassPerMass_Act 27;
BA_ "DDI" SG_ 2362179326 AppRateMassPerMass_Set 26;
BA_ "DDI" SG_ 2362179326 AppRateVolumePerVolume_Max 25;
BA_ "DDI" SG_ 2362179326 AppRateVolumePerVolume_Min 24;
BA_ "DDI" SG_ 2362179326 AppRateVolumePerVolume_Def 23;
BA_ "DDI" SG_ 2362179326 AppRateVolumePerVolume_Act 22;
BA_ "DDI" SG_ 2362179326 AppRateVolumePerVolume_Set 21;
BA_ "DDI" SG_ 2362179326 AppRateDistance_Max 20;
BA_ "DDI" SG_ 2362179326 AppRateDistance_Min 19;
BA_ "DDI" SG_ 2362179326 AppRateDistance_Def 18;
BA_ "DDI" SG_ 2362179326 AppRateDistance_Act 17;
BA_ "DDI" SG_ 2362179326 SetAppRateDistance_Set 16;
BA_ "DDI" SG_ 2362179326 AppRateCountPerArea_Max 15;
BA_ "DDI" SG_ 2362179326 AppRateCountPerArea_Min 14;
BA_ "DDI" SG_ 2362179326 AppRateCountPerArea_Def 13;
BA_ "DDI" SG_ 2362179326 AppRateCountPerArea_Act 12;
BA_ "DDI" SG_ 2362179326 AppRateCountPerArea_Set 11;
BA_ "DDI" SG_ 2362179326 AppRateMassPerArea_Max 10;
BA_ "DDI" SG_ 2362179326 AppRateMassPerArea_Min 9;
BA_ "DDI" SG_ 2362179326 AppRateMassPerArea_Def 8;
BA_ "DDI" SG_ 2362179326 AppRateMassPerArea_Act 7;
BA_ "DDI" SG_ 2362179326 AppRateMassPerArea_Set 6;
BA_ "DDI" SG_ 2362179326 AppRateVolumePerArea_Max 5;
BA_ "DDI" SG_ 2362179326 AppRateVolumePerArea_Min 4;
BA_ "DDI" SG_ 2362179326 AppRateVolumePerArea_Def 3;
BA_ "DDI" SG_ 2362179326 AppRateVolumePerArea_Act 2;
BA_ "DDI" SG_ 2362179326 AppRateVolumePerArea_Set 1;
BA_ "GenSigStartValue" SG_ 2362179326 NumberOfBooms 255;
BA_ "SPN" SG_ 2362179326 MassUnitCmd 2417;
BA_ "SigType" SG_ 2362179326 MassUnitCmd 4;
BA_ "SPN" SG_ 2362179326 VolumeUnitCmd 2416;
BA_ "SigType" SG_ 2362179326 VolumeUnitCmd 4;
BA_ "SPN" SG_ 2362179326 AreaUnitCmd 2415;
BA_ "SigType" SG_ 2362179326 AreaUnitCmd 4;
BA_ "SPN" SG_ 2362179326 DistanceUnitCmd 2414;
BA_ "SigType" SG_ 2362179326 DistanceUnitCmd 4;
BA_ "SPN" SG_ 2362179326 UnitsSystem 5197;
BA_ "SigType" SG_ 2362179326 UnitsSystem 4;
BA_ "SPN" SG_ 2362179326 IdentityNumber 2837;
BA_ "SAEDocument" SG_ 2362179326 IdentityNumber "J1939-81";
BA_ "SPN" SG_ 2362179326 ForceUnits 5196;
BA_ "SigType" SG_ 2362179326 ForceUnits 4;
BA_ "SPN" SG_ 2362179326 PressureUnits 5195;
BA_ "SigType" SG_ 2362179326 PressureUnits 4;
BA_ "SPN" SG_ 2362179326 TemperatureUnits 5194;
BA_ "SigType" SG_ 2362179326 TemperatureUnits 4;
BA_ "SigType" SG_ 2362179326 ManufacturerCode 1;
BA_ "SPN" SG_ 2362179326 ManufacturerCode 2838;
BA_ "SAEDocument" SG_ 2362179326 ManufacturerCode "NMEA2000";
BA_ "SPN" SG_ 2362179326 ECUInstance 2840;
BA_ "SAEDocument" SG_ 2362179326 ECUInstance "J1939-81";
BA_ "SPN" SG_ 2362179326 FunctionInstance 2839;
BA_ "SAEDocument" SG_ 2362179326 FunctionInstance "J1939-81";
BA_ "SPN" SG_ 2362179326 Function 2841;
BA_ "SAEDocument" SG_ 2362179326 Function "J1939-81";
BA_ "SAEDocument" SG_ 2362179326 VehicleSystem2 "J1939-81";
BA_ "SPN" SG_ 2362179326 VehicleSystemInstance 2843;
BA_ "SAEDocument" SG_ 2362179326 VehicleSystemInstance "J1939-81";
BA_ "SPN" SG_ 2362179326 IndustryGroup 2846;
BA_ "SAEDocument" SG_ 2362179326 IndustryGroup "NMEA2000";
BA_ "SPN" SG_ 2362179326 ArbitraryAddressCapable 2844;
BA_ "SAEDocument" SG_ 2362179326 ArbitraryAddressCapable "J1939-81";
BA_ "SystemSignalLongSymbol" SG_ 2559835902 ArbitraryAddressCapableQualifier "ArbitraryAddressCapableQualifierFlag";
BA_ "SystemSignalLongSymbol" SG_ 2559835902 VehicleSystemInstanceQualifierFl "VehicleSystemInstanceQualifierFlag";
BA_ "SPN" SG_ 2365408254 MachineSelSpeedSetpointCommand 4310;
BA_ "SigType" SG_ 2365408254 MachineSelSpeedSetpointCommand 1;
BA_ "SPN" SG_ 2365408254 MachineSelSpeedSetpointLimit 4311;
BA_ "SigType" SG_ 2365408254 MachineSelSpeedSetpointLimit 1;
BA_ "SPN" SG_ 2365408254 MachineSelDirectionCommand 4312;
BA_ "SigType" SG_ 2365408254 MachineSelDirectionCommand 4;
BA_ "SPN" SG_ 2364547838 MachineSelectedSpeed 4305;
BA_ "SPN" SG_ 2364547838 MachineSelectedDistance 4306;
BA_ "SPN" SG_ 2364547838 MachineSelectedDirection 4309;
BA_ "SigType" SG_ 2364547838 MachineSelectedDirection 4;
BA_ "SPN" SG_ 2364547838 MachineSelectedSpeedSource 4308;
BA_ "SPN" SG_ 2364547838 MachineSelectedSpeedLimitStatus 4307;
BA_ "SPN" SG_ 2566801406 MaintainActuatorPower 1868;
BA_ "SigType" SG_ 2566801406 MaintainActuatorPower 4;
BA_ "SPN" SG_ 2566801406 MaintainECUPower 1867;
BA_ "SigType" SG_ 2566801406 MaintainECUPower 4;
BA_ "SPN" SG_ 2566801406 ImplementWorkState 1871;
BA_ "SigType" SG_ 2566801406 ImplementWorkState 4;
BA_ "SPN" SG_ 2566801406 ImplementParkState 1870;
BA_ "SigType" SG_ 2566801406 ImplementParkState 4;
BA_ "SPN" SG_ 2566801406 ImplementTransportState 1869;
BA_ "SigType" SG_ 2566801406 ImplementTransportState 4;
BA_ "SPN" SG_ 2566787070 LanguageCodeCmd 2410;
BA_ "SigType" SG_ 2566787070 LanguageCodeCmd 3;
BA_ "SPN" SG_ 2566787070 TimeFormatCmd 2413;
BA_ "SigType" SG_ 2566787070 TimeFormatCmd 4;
BA_ "SPN" SG_ 2566787070 DecimalSymbolCmd 2411;
BA_ "SigType" SG_ 2566787070 DecimalSymbolCmd 4;
BA_ "SPN" SG_ 2566787070 DateFormatCmd 2412;
BA_ "SigType" SG_ 2566787070 DateFormatCmd 1;
BA_ "SPN" SG_ 2566787070 MassUnitCmd 2417;
BA_ "SigType" SG_ 2566787070 MassUnitCmd 4;
BA_ "SPN" SG_ 2566787070 VolumeUnitCmd 2416;
BA_ "SigType" SG_ 2566787070 VolumeUnitCmd 4;
BA_ "SPN" SG_ 2566787070 AreaUnitCmd 2415;
BA_ "SigType" SG_ 2566787070 AreaUnitCmd 4;
BA_ "SPN" SG_ 2566787070 DistanceUnitCmd 2414;
BA_ "SigType" SG_ 2566787070 DistanceUnitCmd 4;
BA_ "SPN" SG_ 2566787070 UnitsSystem 5197;
BA_ "SigType" SG_ 2566787070 UnitsSystem 4;
BA_ "SPN" SG_ 2566787070 ForceUnits 5196;
BA_ "SigType" SG_ 2566787070 ForceUnits 4;
BA_ "SPN" SG_ 2566787070 PressureUnits 5195;
BA_ "SigType" SG_ 2566787070 PressureUnits 4;
BA_ "SPN" SG_ 2566787070 TemperatureUnits 5194;
BA_ "SigType" SG_ 2566787070 TemperatureUnits 4;
BA_ "SPN" SG_ 2365459198 TractorControlLimitStatus1 5227;
BA_ "SPN" SG_ 2365459198 TractorControlModeResponse1 5213;
BA_ "SigType" SG_ 2365459198 TractorControlValueResponse1 1;
BA_ "SigType" SG_ 2365459198 TractorControlValueResponse2 1;
BA_ "SPN" SG_ 2365459454 TractorControlModeCmd1 5204;
BA_ "SigType" SG_ 2365459454 TractorControlCmdValue1 1;
BA_ "SigType" SG_ 2365459454 TractorControlCmdValue2 1;
BA_ "SPN" SG_ 2365391616 ImplementOperatingStateCmd 5139;
BA_ "SPN" SG_ 2566734590 CertificationYear 4313;
BA_ "SPN" SG_ 2566734590 CertificateRevision 4314;
BA_ "SPN" SG_ 2566734590 CertificateLaboratoryType 4315;
BA_ "SPN" SG_ 2566734590 CertificationLaboratoryID 4316;
BA_ "SPN" SG_ 2566734590 CertTypeVTWorkingSetMember 4324;
BA_ "SPN" SG_ 2566734590 CertTypeVTWorkingSetMaster 4323;
BA_ "SPN" SG_ 2566734590 CertTypeVirtualTerminal 4322;
BA_ "SPN" SG_ 2566734590 CertTypeClass3ECU 4321;
BA_ "SPN" SG_ 2566734590 CertTypeTECUClass3 4320;
BA_ "SPN" SG_ 2566734590 CertTypeTECUClass2 4319;
BA_ "SPN" SG_ 2566734590 CertTypeTECUClass1 4318;
BA_ "SPN" SG_ 2566734590 CertTypeMinimumECU 4317;
BA_ "SPN" SG_ 2566734590 CertTypeGPSReceiver 4329;
BA_ "SPN" SG_ 2566734590 CertTypeFileServer 4328;
BA_ "SPN" SG_ 2566734590 CertTypeTCWorkingSetMember 4327;
BA_ "SPN" SG_ 2566734590 CertTypeTCWorkingSetMaster 4326;
BA_ "SPN" SG_ 2566734590 CertTypeTaskController 4325;
BA_ "SPN" SG_ 2566734590 CertificationReferenceNumber 4330;
BA_ "SPN" SG_ 2365473534 FrontHitchPositionCmd 1874;
BA_ "SigType" SG_ 2365473534 FrontHitchPositionCmd 1;
BA_ "SPN" SG_ 2365473534 RearHitchPositionCmd 1875;
BA_ "SigType" SG_ 2365473534 RearHitchPositionCmd 1;
BA_ "SPN" SG_ 2365473534 FrontPTOOutShaftSpeedSetPointCmd 1886;
BA_ "SigType" SG_ 2365473534 FrontPTOOutShaftSpeedSetPointCmd 1;
BA_ "SPN" SG_ 2365473534 RearPTOOutShaftSpeedSetPointCmd 1887;
BA_ "SigType" SG_ 2365473534 RearPTOOutShaftSpeedSetPointCmd 1;
BA_ "SPN" SG_ 2365473534 RearPTOEngagementCmd 1894;
BA_ "SigType" SG_ 2365473534 RearPTOEngagementCmd 4;
BA_ "SPN" SG_ 2365473534 FrontPTOEngagementCmd 1893;
BA_ "SigType" SG_ 2365473534 FrontPTOEngagementCmd 4;
BA_ "SPN" SG_ 2365473534 RearPTOEconomyModeCmd 1898;
BA_ "SigType" SG_ 2365473534 RearPTOEconomyModeCmd 4;
BA_ "SPN" SG_ 2365473534 FrontPTOEconomyModeCmd 1897;
BA_ "SigType" SG_ 2365473534 FrontPTOEconomyModeCmd 4;
BA_ "SPN" SG_ 2365473534 RearPTOModeCmd 1896;
BA_ "SigType" SG_ 2365473534 RearPTOModeCmd 4;
BA_ "SPN" SG_ 2365473534 FrontPTOModeCmd 1895;
BA_ "SigType" SG_ 2365473534 FrontPTOModeCmd 4;
BA_ "SPN" SG_ 2360213246 CurvatureCommand 5237;
BA_ "SigType" SG_ 2360213246 CurvatureCommand 1;
BA_ "SPN" SG_ 2360213246 CurvatureCommandStatus 5239;
BA_ "SigType" SG_ 2360213246 CurvatureCommandStatus 4;
BA_ "SPN" SG_ 2563047166 PortFlowCmd 2944;
BA_ "SigType" SG_ 2563047166 PortFlowCmd 1;
BA_ "SPN" SG_ 2563047166 StateCmd 2933;
BA_ "SigType" SG_ 2563047166 FailSaveModeCmd 4;
BA_ "SPN" SG_ 2563112702 ExtendedPortMeasuredFlow 2937;
BA_ "SigType" SG_ 2563112702 ExtendedPortMeasuredFlow 1;
BA_ "SPN" SG_ 2563112702 RetractPortMeasuredFlow 2938;
BA_ "SigType" SG_ 2563112702 RetractPortMeasuredFlow 1;
BA_ "SPN" SG_ 2563112702 ExtendedPortPressure 2941;
BA_ "SigType" SG_ 2563112702 ExtendedPortPressure 1;
BA_ "SPN" SG_ 2563112702 RetractPortPressure 2942;
BA_ "SigType" SG_ 2563112702 RetractPortPressure 1;
BA_ "SPN" SG_ 2563112702 ReturnPortPressure 2943;
BA_ "SigType" SG_ 2563112702 ReturnPortPressure 1;
BA_ "SPN" SG_ 2563112702 ValveLimitStatus 5192;
BA_ "SPN" SG_ 2563178238 ExtendedPortEstimatedFlow 2939;
BA_ "SigType" SG_ 2563178238 ExtendedPortEstimatedFlow 1;
BA_ "SPN" SG_ 2563178238 RetractPortEstimatedFlow 2940;
BA_ "SigType" SG_ 2563178238 RetractPortEstimatedFlow 1;
BA_ "SPN" SG_ 2563178238 ValveState 2932;
BA_ "SPN" SG_ 2563178238 FailSafeMode 2934;
BA_ "SigType" SG_ 2563178238 FailSafeMode 4;
BA_ "SPN" SG_ 2563178238 ValveLimitStatus 5192;
BA_ "SigType" SG_ 2583168510 SequenceID 1;
BA_ "SigType" SG_ 2583168510 PositionDate 1;
BA_ "SigType" SG_ 2583168510 PositionTime 1;
BA_ "SigType" SG_ 2583168510 LatitudeLow 1;
BA_ "SigType" SG_ 2583168510 LongitudeLow 1;
BA_ "SigType" SG_ 2583168510 GNSSIntegrity 4;
BA_ "SigType" SG_ 2583168510 NumberOfSVs 1;
BA_ "SigType" SG_ 2583168510 HDOP 2;
BA_ "SigType" SG_ 2583168510 PDOP 2;
BA_ "SigType" SG_ 2583168510 GeoidalSeparation 2;
BA_ "SigType" SG_ 2583168510 NumberOfReferenceStations 1;
BA_ "SigType" SG_ 2583168510 ReferenceStationID1 1;
BA_ "SigType" SG_ 2583168510 AgeOfDGNSSCorrections1 1;
BA_ "SPN" SG_ 2360147710 EstimatedCurvature 5238;
BA_ "SigType" SG_ 2360147710 EstimatedCurvature 1;
BA_ "SPN" SG_ 2360147710 MechanicalSystemLockout 5243;
BA_ "SigType" SG_ 2360147710 MechanicalSystemLockout 4;
BA_ "SPN" SG_ 2360147710 SteeringSystemReadiness 5242;
BA_ "SigType" SG_ 2360147710 SteeringSystemReadiness 4;
BA_ "SPN" SG_ 2360147710 SteeringInputPositionStatus 5241;
BA_ "SigType" SG_ 2360147710 SteeringInputPositionStatus 4;
BA_ "SPN" SG_ 2360147710 RequestResetCommandStatus 5240;
BA_ "SigType" SG_ 2360147710 RequestResetCommandStatus 4;
BA_ "SPN" SG_ 2365475326 GroundBasedMachineSpeed 1859;
BA_ "SigType" SG_ 2365475326 GroundBasedMachineSpeed 1;
BA_ "SPN" SG_ 2365475326 GroundBasedMachineDistance 1860;
BA_ "SigType" SG_ 2365475326 GroundBasedMachineDistance 1;
BA_ "SPN" SG_ 2365475326 GroundBasedMachineDirection 1861;
BA_ "SigType" SG_ 2365475326 GroundBasedMachineDirection 4;
BA_ "SigType" SG_ 2628517630 VS_VolumeName 9;
BA_ "SigType" SG_ 2628517630 GCD_PathName 9;
VAL_ 2362179326 Command 10 "SetValueAndAcknowledge" 9 "PeerControlAssignment" 0 "TechnicalData" 1 "DeviceDescription" 2 "RequestValue" 3 "ValueCommand" 4 "TimeInterval" 5 "DistanceInterval" 6 "MinWithinThreshold" 7 "MaxWithinThreshold" 8 "ChangeThreshold" 13 "PDACK" 14 "TaskControllerStatus" 15 "WorkingSetTask" ;
VAL_ 2362179326 DeviceDescriptionMsgType 13 "ChangeDesignatorResponse" 12 "ChangeDesignator" 11 "ObjectPoolDeleteResponse" 10 "ObjectPoolDelete" 9 "ObjectPoolActivateResponse" 8 "ObjectPoolActivate" 7 "ObjectPoolTransferResponse" 6 "ObjectPoolTransfer" 5 "RequestObjectPoolTransferResp" 4 "RequestObjectPoolTransfer" 3 "LocalizationLabel" 2 "RequestLocalizationLabel" 1 "StructureLabel" 0 "RequestStructureLabel" ;
VAL_ 2362179326 TechnicalDataMsgType 1 "ParameterVersion" 0 "ParameterRequestVersion" ;
VAL_ 2362179326 ErrorCodeObjPoolActiveResp1 1 "ErrorsInTheObjectPool" 0 "NoError" ;
VAL_ 2362179326 ErrorCodeObjectPoolDelete 1 "Error" 0 "Success" ;
VAL_ 2362179326 ActivateDeactivateCommand 255 "ObjectPoolActivation" 0 "ObjectPoolDeactivation" ;
VAL_ 2362179326 ErrorCodeObjPoolTransfer 2 "GeneralError" 1 "TaskControllerRanOutOfMemory" 0 "NoError" ;
VAL_ 2362179326 Status 1 "NotEnoughMemoryAvailable" 0 "EnoughMemoryAvailable" ;
VAL_ 2362179326 ErrorCodeObjPoolActiveResp2 1 "TaskControllerRanOutOfMemory" 0 "NoError" ;
VAL_ 2362179326 ErrorCodeObjPoolActiveResp3 1 "GeneralError" 0 "NoError" ;
VAL_ 2362179326 ErrorCodeChangeDesignator 1 "Error" 0 "Success" ;
VAL_ 2362179326 Documentation 1 "Supported" 0 "NotSupported" ;
VAL_ 2362179326 TimeAndPositionForDataLogging 1 "Supported" 0 "NotSupported" ;
VAL_ 2362179326 TC_GEO_DefinitionPositionBasedCo 1 "Supported" 0 "NotSupported" ;
VAL_ 2362179326 PeerControlAssignment 1 "Supported" 0 "NotSupported" ;
VAL_ 2362179326 ImplementSectionControl 1 "Supported" 0 "NotSupported" ;
VAL_ 2362179326 TimeFormatCmd 0 "Hour24" 1 "Hour12" 3 "NoAction" ;
VAL_ 2362179326 DecimalSymbolCmd 0 "CommaIsUsed" 1 "PointIsUsed" 3 "NoAction" ;
VAL_ 2362179326 PeerControlCommand 5 "Transmitter Acknowledge" 4 "UnassignTransmitter" 3 "Assign Transmitter" 2 "Receiver Ackowledge" 1 "UnassignReceiver" 0 "Assign Receiver" ;
VAL_ 2362179326 DateFormatCmd 0 "ddmmyyyy" 1 "ddyyyymm" 2 "mmyyyydd" 3 "mmddyyyy" 4 "yyyymmdd" 5 "yyyyddmm" ;
VAL_ 2362179326 ErrorCodeProcessData1 0 "NoError" 1 "CommandNotSupported" ;
VAL_ 2362179326 DataLogDistanceInterval 0 "Stop measurement" ;
VAL_ 2362179326 DataLogTimeInterval 0 "Stop measurement" ;
VAL_ 2362179326 ErrorCodeProcessData2 0 "NoError" 1 "InvalidElementNumber" ;
VAL_ 2362179326 ErrorCodeProcessData3 0 "NoError" 1 "DDINotSupportedByElement" ;
VAL_ 2362179326 ErrorCodeProcessData4 0 "NoError" 1 "TriggerMethodNotSupported" ;
VAL_ 2362179326 ErrorCodeProcessData5 0 "NoError" 1 "ProcessDataNotSetable" ;
VAL_ 2362179326 ErrorCodeProcessData6 0 "NoError" 1 "InvalidIntervalOrThreshold" ;
VAL_ 2362179326 ErrorCodeProcessData7 0 "NoError" 1 "ProcessDataValueNotConformToDDI " ;
VAL_ 2362179326 ErrorCodeProcessData8 0 "NoError" 1 "ProcessDataValueIsOutsideOperationalRange " ;
VAL_ 2362179326 MassUnitCmd 0 "Metric" 1 "Imperial" 2 "TonsPounds" 3 "NoAction" ;
VAL_ 2362179326 VolumeUnitCmd 0 "Metric" 1 "Imperial" 2 "US" 3 "NoAction" ;
VAL_ 2362179326 AreaUnitCmd 0 "Metric" 1 "Imperial" 3 "NoAction" ;
VAL_ 2362179326 DistanceUnitCmd 0 "Metric" 1 "Imperial" 3 "NoAction" ;
VAL_ 2362179326 ErrorCodeObjPool1 1 "MethodOrAttributeNotSupported" 0 "NoError" ;
VAL_ 2362179326 UnitsSystem 0 "Metric" 1 "Imperial" 2 "US" 3 "NoAction" ;
VAL_ 2362179326 ErrorCodeObjPool2 1 "UnknownObjectReference" 0 "NoError" ;
VAL_ 2362179326 ForceUnits 0 "Metric" 1 "Imperial" 2 "Reserved" 3 "NoAction" ;
VAL_ 2362179326 ErrorCodeObjPool3 1 "GeneralError" 0 "NoError" ;
VAL_ 2362179326 ErrorCodeObjPool4 1 "ObjectPoolWasDeleted" 0 "NoError" ;
VAL_ 2362179326 PressureUnits 0 "Metric" 1 "Imperial" 2 "Reserved" 3 "NoAction" ;
VAL_ 2362179326 TemperatureUnits 0 "Metric" 1 "Imperial" 2 "Reserved" 3 "NoAction" ;
VAL_ 2362179326 ManufacturerCode 520 "Trapeze" 519 "Peeters Landbouwmachines b.v." 518 "Transas USA Inc." 517 "Noland Engineering" 516 "AVAT Automation GmbH" 515 "GINAF Trucks Nederland B.V." 514 "DISTek Integration, Inc." 513 "FarmscanAg" 512 "Inpower LLC" 511 "Sulky" 510 "Marinesoft Co. Ltd" 509 "MOTORTECH GmbH" 508 "Transtech Innovations" 507 "Test Center ISOBUS" 506 "IHI STAR Machinery Corporation" 505 "Yetter Farm Equipment" 504 "Vesper Marine" 503 "Naviop S.R.L." 502 "Attwood Corporation" 501 "Agrotronix S.A." 500 "Oxbo International Corporation" 499 "LCJ Capteurs" 498 "Innovative Design Solutions, Inc." 497 "SENTRON Sistemas Embarcados" 496 "W. Gessmann GmbH" 495 "HOLMER Maschinenbau GmbH" 494 "Synerject" 493 "Watcheye" 492 "Inergy Automotive Systems" 491 "Penny and Giles Ltd" 490 "QuikQ" 489 "Appareo Systems" 488 "The Charles Machine Works, Inc." 487 "DSE Test Solutions A/S" 486 "Westport Innovations Inc." 485 "MATT automotive" 484 "Headsight Inc." 483 "Valeo" 482 "Tricon Electronics" 481 "Chetco Digital Instruments" 480 "EnerDel, Inc." 454 "NGK Spark Plug Co. Ltd" 453 "Cooper Bussmann" 452 "WIKA Alexander Wiegand SE & Co. KG" 451 "Parker Hannifin Corp" 450 "Dycor Technologies Ltd." 449 "Polaris Industries Inc" 448 "Stanadyne Corporation, Electronics Systems" 447 "Great Plains Mfg." 446 "CertTech, L.L.C." 445 "KAT MECHATRONIC, Electronic Product Division" 444 "ITT Power Solutions" 443 "SignalQuest, Inc." 442 "Horsch Maschinen GmbH" 441 "PTG Reifendruckregelsysteme GmbH" 440 "Cummins Power Generation" 439 "Hyundai Heavy Industries" 438 "Comar Systems Ltd" 437 "Digital Yacht Limited" 436 "Kinze Manufacturing" 435 "Zunhammer GmbH" 434 "Stored Energy Systems" 433 "Rowe Electronics" 432 "S&A Systems, Inc." 431 "Tohatsu Corporation" 430 "Auteq Telematica S.A." 479 "Vapor Bus International" 478 "OceanSat BV" 477 "OilQuick AB" 476 "Hummingbird Marine Electronics" 475 "GME" 474 "Persen Technologies Inc." 473 "Boss Industries, Inc." 472 "Tenneco Inc." 471 "Sea Cross Marine AB" 470 "SI-TEX Marine Electronics" 469 "RA Consulting GmbH" 468 "Tyco Fire Protection Products" 467 "Lely Industries N.V." 466 "Veethree Electronics and Marine LLC" 465 "Ashcroft Inc" 464 "Leach International Corporation" 463 "PROBOTIQ" 462 "IHI Shibaura Machinery Corporation" 461 "HAWE Hydraulik SE" 460 "San Giorgio S.E.I.N." 459 "Alltek Marine Electronics Corp" 458 "Control Solutions, Inc." 457 "RUSELPROM-ElectricDrive Ltd" 456 "General Kinetics" 455 "ADZ NAGANO GmbH" 429 "Rota Engineering Ltd." 428 "Mfg_428" 427 "em-trak Marine Electronics Ltd" 426 "Egersund Marine Electronics AS" 425 "Methode Electronics Inc, MDI" 424 "Odyne LLC" 423 "BSM Wireless, Inc." 422 "True Heading AB" 421 "Vertex Standard Co., Ltd" 420 "Vermeer Corporation, ACS Group" 419 "Fusion Electronics Ltd" 418 "Intellistick Inc" 417 "KZValve" 416 "Kubota Corporation" 415 "Valid Manufacturing Ltd." 414 "Cattron Group International" 413 "Datapross Nijbroek bv" 412 "WebTech Wireless Inc." 411 "Hy-Drive Technologies Ltd." 410 "COBO S.p.A. Divisione 3B6" 409 "Transfluid S.r.L." 408 "Corvus Energy Ltd." 407 "Comtech Mobile Datacom" 406 "Vecima Networks Inc." 405 "Wema System AS" 404 "Com Nav Marine Ltd" 403 "Trackwell ADS, Inc." 402 "Simma Software, Inc." 401 "Torqeedo GmbH" 400 "Livorsi Marine" 399 "ISEKI & Co., Ltd." 398 "Hilite International" 397 "Sanyo-kiki Co Ltd." 396 "Beyond Measure" 395 "GENTEC S.R.L." 394 "Capi 2 Nederland BV" 393 "Harvest Tec, Inc" 392 "Tianyuan Technology Co Ltd." 391 "Electronic Design for Industry, Inc" 390 "Partech Inc." 389 "Benchmark Electronics, Minnesota Division" 388 "Innomatix, LLC" 387 "Orscheln Products, LLC" 386 "JLG Automation BVBA" 385 "Johnson Outdoor Marine Electronics" 384 "Camano Light" 383 "MCL Industries" 382 "National Agricultural and Food Research Organization" 380 "Suntech International Ltd." 379 "Yamabiko Corporation" 378 "Glendinning Marine Products" 377 "ifm electronic gmbh" 376 "Quake Global" 375 "Williams Controls Inc." 372 "Delphi" 381 "B&G" 374 "Northern Lights, Inc." 373 "Electronic Design Inc." 371 "Heinzmann GmbH & Co. KG" 370 "Rolls-Royce Marine AS" 369 "Power Torque Engineering Ltd" 368 "HANSENHOF_electronic" 367 "Fliegl Agrartechnik" 366 "Viewnyx Corp." 365 "Digi-Star, LLC" 364 "OEM Controls Inc." 363 "BEI Duncan" 362 "Alois Poettinger Maschinenfabrik GmbH" 361 "InMach" 360 "HJS Emission Technology GmbH & Co KG" 359 "Ludwig Bergmann GmbH" 358 "Victron Energy BV" 357 "Hardi International A/S" 356 "Fischer Panda Generators, Inc" 355 "Mastervolt International B.V." 354 "Junkkari OY" 353 "Hegemon Electronics, Inc." 352 "SAME DEUTZ-FAHR" 351 "Thrane & Thrane" 350 "Noris Marine Systems GmbH & Co KG" 349 "Suonentiet" 348 "Amazonen Werke H. Dreyer" 347 "Honeywell" 346 "Control Solutions" 345 "Korean Maritime University" 344 "Parvus Corporation" 343 "Baumer Group" 342 "THOMAS MAGNETE GmbH" 341 "Boning GmbH & Co" 340 "Continental AG" 339 "Competence Center ISOBUS e.V." 338 "GRAF-SYTECO" 337 "Carraro S.p.A." 336 "APE s.r.o." 335 "Evo Electric Ltd" 334 "Takata-Petri AG" 333 "Hadley Products Corporation" 332 "HWH Corporation" 331 "Horton, Inc." 330 "Kidde Aerospace and Defense" 329 "Deif A/S" 328 "Qwerty Electronik AB" 252 "Sensor-Technik Wiedemann GmbH" 251 "German Agricultural Society" 250 "Kuhn Group" 249 "Schaltbau GmbH" 233 "Yacht Monitoring Solutions Inc." 232 "TSD Integrated Controls" 1863 "Thomas G. Faria Co." 1862 "Sanshin" 1861 "Vector CANtech" 1860 "MMP" 1859 "Kvasar AB" 1858 "Litton" 1857 "Simrad" 1856 "Trimble" 1855 "Furuno USA" 1854 "Northstar Technologies" 1853 "Japan Radio Co." 1852 "Navionics" 1851 "Raymarine" 1850 "Teleflex" 222 "Generac Power Systems, Inc." 221 "SiE" 220 "Beede Electrical Instrument Company, Inc." 219 "Cat OEM Solutions" 218 "Gits Manufacturing Company" 217 "RM Michaelides Software & Elektronik GmbH" 216 "Paneltronics Inc." 215 "Aetna Engineering/Fireboy-Xintex" 214 "MC elettronica Srl" 213 "CNH Belgium N.V." 212 "Sure Power Industries, Inc." 211 "DNA Group" 210 "Iteris, Inc." 209 "Bell Equip. Co. SA (PTY) LTD" 208 "Drew Technologies, Inc." 207 "Otto Engineering" 206 "port GmbH" 205 "SmarTire Systems Inc" 204 "The Morey Corporation" 203 "MILtronik GmbH" 202 "Curtis Instruments, Inc." 201 "Disenos y Tecnologia S.A." 200 "MGM Brakes" 199 "Actia Corp." 198 "Mystic Valley Communications" 197 "Mechron Power Systems" 196 "LEMKEN GmbH & Co. KG" 195 "General Engine Products" 194 "TriMark Corporation" 193 "Nobletec" 192 "Floscan" 191 "XRS Corporation" 190 "Hella KGaA Hueck & Co." 189 "QUALCOMM" 188 "EMP Corp." 187 "Air-Weigh" 186 "Altronic, Inc." 185 "Beede Electrical Instrument Company" 184 "EIA Electronics" 183 "KDS Controls, Inc." 182 "Vehicle Systems Engineering B.V." 181 "Coretronics, Inc." 180 "Smart Power Systems" 179 "TeeJet Technologies Denmark" 178 "Siemens VDO Automotive AG" 177 "Diagnostic System Associates" 176 "Moritz Aerospace" 175 "Veris Technologies, Inc." 174 "AB Volvo Penta" 173 "Ryeso, Inc." 172 "Yanmar Marine USA" 171 "Wachendorff Elektronik GmbH & Co. KG" 170 "Computronics Corporation Ltd." 169 "Marlin Technologies Inc." 168 "Xantrex" 167 "JLG Industries Inc." 166 "Phoenix International" 165 "CPAC Systems AB" 164 "DaimlerChrysler Off-Highway" 163 "BRP Inc." 162 "Axiomatic Technologies" 161 "Offshore Systems (UK) Limited" 160 "Nido" 159 "NTech Industries Inc." 158 "Firestone Industrial Products Company" 157 "ISSPRO Inc." 156 "ITT Industries - Cannon" 155 "Vetronix Corporation" 154 "Westerbeke Corporation" 153 "Woodward, Industrial Controls Division" 152 "elobau GmbH & Co. KG" 151 "Raven Industries Inc. - Flow Controls Division" 150 "Fleetguard" 149 "Holset" 148 "Blue Water Data, Inc." 147 "Nautibus Electronic GmbH" 146 "Maxima Technologies" 145 "MurCal Controls" 144 "Mercury Marine" 143 "W. Gmeiner GmbH & Co." 142 "TRW Automotive (Commercial Steering Systems)" 141 "Thales Navigation Ltd." 140 "Lowrance Electronics, Inc." 139 "Caterpillar Trimble Control Technologies (CTCT), LLC" 138 "Georg Fritzmeier GmbH & Co. KG" 137 "Maretron" 136 "Komatsu Ltd." 135 "Airmar Technology Corporation" 134 "Iris Technology Ltd." 133 "Bucher Schoerling GmbH" 132 "Mulag-Fahrzeugwerk" 131 "ITT Industries" 130 "Nido - Universal Machines B.V." 129 "OMNEX Control Systems, Inc." 128 "Gerhard Duecker GmbH & Co. KG" 127 "Holland USA" 126 "Driver Tech" 125 "Nevada Automotive Test Center" 124 "Hydac Electronic" 123 "Basler Electric" 122 "FG Wilson (Engineering) Limited" 121 "HED (Hydro Electronic Devices, Inc.)" 120 "RDS Technology Ltd." 119 "IntegriNautics" 118 "Intron GmbH" 117 "HUSCO International" 116 "BEELINE Technologies" 115 "NACCO Materials Handling Group, Inc." 114 "EControls, Inc." 113 "Stress-Tek, Inc." 112 "MECALAC" 111 "Maschinenfabrik Bernard Krone GmbH" 110 "EPIQ Sensor-Nite" 109 "TeeJet Technologies Denmark" 108 "WTK-Elecktronik GmbH" 107 "Grimme Landmaschinen GmbH & Co. KG" 106 "BAE Systems Controls, Inc." 105 "Kiepe Elektrik GmbH & Co. KG" 104 "Claas Selbstfahrende Erntemaschinen GmbH" 103 "CLAAS Agrosystems GmbH & Co. KG" 102 "AGCO GmbH & Co." 101 "Sensoria" 100 "VDO Technik AG" 99 "International Transmissions Ltd (ITL)" 98 "Mueller-Elektronik GmbH & Co." 97 "Ag Leader Technology, Inc." 96 "Mech@tronic IT GmbH" 95 "Pacific Insight Electronics Corp." 94 "CNH Global N.V." 93 "Perkins Engines Company Ltd." 92 "Ag-Chem Equipment Co., Inc." 91 "BSG Bodensee Steuergeraete GmbH" 90 "Knorr-Bremse SfN GmbH" 89 "Kverneland Group, Electronics Division" 88 "Satloc Precision GPS" 87 "J.C. Bamford Excavators Ltd (JCB)" 86 "C.E. Niehoff & Company" 85 "Kohler Co." 84 "New Holland UK Limited" 83 "Bendix VORAD Technologies" 82 "Bobcat/Ingersoll-Rand" 81 "Fire Research Corp" 80 "Twin Disc, Inc." 79 "Daimler Benz AG - Engine Division (PBM)" 78 "Frank W. Murphy Manufacturing, Inc." 77 "Deere Power Systems Group" 76 "unused" 75 "Deere & Co. Agricultural Division" 74 "Eaton Axle-Brake Division" 73 "LeTourneau, Inc." 72 "Sisu Corporation" 71 "Vansco Electronics Ltd." 70 "Flex-Coil Limited" 69 "Trimble Navigation" 68 "Scania" 67 "Funk Manufacturing Company" 66 "John Deere Construction Equipment Division" 65 "MAN Nutzfahrzeuge AG" 64 "unused" 63 "ZF Industries Inc." 62 "Wabco" 61 "Volvo Truck Corp." 60 "Volvo Trucks North America Inc." 59 "VES Inc." 58 "SPX Corporation, OTC Division" 57 "Sauer-Danfoss Co." 56 "SAIC" 55 "Ryder System Inc." 54 "Meritor Wabco" 53 "Continental Automotive Systems US, Inc." 52 "Meritor Automotive, Inc." 51 "Robert Bosch GmbH" 50 "Robert Bosch Corp" 49 "RE America Inc." 48 "Pollak Alphabet" 47 "Phillips Semiconductor" 46 "Noregon Systems, Inc" 45 "PACCAR" 44 "Nippondenso Co. Ltd." 43 "International Truck and Engine Corp. Vehicle Electronics" 42 "International Truck and Engine Corp. Engine Electronics" 41 "Motorola Inc." 40 "Motorola AIEG Inc." 39 "Microfirm Inc." 38 "Micro Processor Systems Inc." 37 "Mack Trucks Inc." 36 "Lucas Ltd." 35 "Kenworth Truck Co." 34 "Kelsey Hayes Co." 33 "John Deere" 32 "Jacobs Vehicle Systems" 31 "J Pollak Corp." 30 "Isuzu Motors Ltd." 29 "Hino Motors Ltd." 28 "Grote Ind. Inc." 27 "GMC" 26 "General Motors Corp., Service Technology Group" 25 "Daimler Trucks North America LLC" 24 "Ford Motor Co., Vehicle Controls" 23 "Ford Motor Co., Heavy Truck" 22 "Ford Motor Co., Electronic Concepts $ Systems" 21 "Echilin Inc., Midland Brake Inc." 20 "Eaton Ltd" 19 "Eaton Corp. Trucking Info Services" 18 "Eaton Corp, Transmission Division" 17 "Eaton Corp. Res & Dev" 16 "Eaton Corp." 15 "Dickey-John Corp." 14 "Detroit Diesel Corporation" 13 "Delco Electronics" 12 "Deere & Company, Precision Farming" 11 "Dearborn Group Inc." 10 "Cummins Engine Co." 9 "Chrysler Corp." 8 "Caterpillar Inc." 7 "Case Corp." 6 "Berifors Electronics AB" 5 "AMP Inc." 4 "Ametek-Dixson" 3 "Ametek, US Gauge Division" 2 "Allison Transmission, GMC" 1 "Allied Signal Inc." 0 "Reserved" 231 "Topcon Positioning Systems, Inc." 230 "Saucon Technologies" 229 "Garmin International Inc." 228 "ZF Marine Electronics" 227 "Lykketronic A/S" 226 "Monaco Coach Corporation" 225 "SKF" 224 "EMMI Network, S.L." 223 "Vaueo Retarder Co., Ltd." 263 "IMMI" 262 "HydraForce, Inc" 261 "Red Dot Corporation" 260 "Reichhardt GmbH" 259 "Jetter AG" 258 "ARAG" 257 "Honda Motor Co., Ltd" 256 "Tyco Electronics AMP" 255 "MEAS France" 254 "GE Sensing" 253 "Mobile Control Systems" 298 "Holley Performance" 297 "Zonar Systems Inc" 296 "micro dynamics GmbH" 295 "BEP Marine" 294 "Grayhill Inc." 293 "Spyder Controls Corp." 292 "IKUSI - Angel Iglesias S.A." 291 "Groeneveld Transport Efficiency BV" 290 "Kuebler GmbH" 289 "Watlow" 288 "Mitsubishi FUSO Truck & Bus Corp." 287 "NTech Industries, Inc" 286 "Coelmo srl" 285 "Sea Recovery Corp" 284 "Mobile Tech Chile" 283 "CWF Hamilton & Co Ltd" 282 "Medallion Instrumentation Systems" 281 "Precision Governors LLC" 311 "Patrick Power Products" 310 "TECNORD srl" 309 "Krauss-Maffei Wegmann GmbH & Co. KG" 308 "Cyntrx" 307 "MBW Technologies" 306 "Sleipner Motor AB" 305 "NovAtel Inc" 304 "EmpirBus AB" 303 "CTS Corporation" 302 "Nissin Kogyo Co., LTD" 301 "Parker Hannifin (UK) Ltd FDE group" 300 "Systron Donner Automotive" 299 "Rauch Landmaschinen GmbH" 280 "Leica Geosystems Pty Ltd" 279 "Geometris LP" 278 "Takata Electronics" 277 "LHP Telematics" 276 "Aqua-Hot Heating Systems" 275 "Navico Egersund AS" 274 "LTW Technology Co., LTD" 273 "Active Research Limited" 272 "Gross Mechanical Laboratories, Inc" 327 "Sonceboz SA" 326 "Akron Brass Company" 325 "ASM Automation Sensorik Messtechnik GmbH" 324 "Snap-on Diagnostics" 323 "Mobileye Vision Technologies Ltd." 322 "MICHENKA s.r.o." 321 "Ultra Electronics, Electrics" 320 "Miedema Landbouwwerktuigenfabriek B.V." 319 "Cadec Global" 318 "SAT Plan" 317 "Navtronics Bvba" 316 "ITT Flow Control" 315 "Icom Incorporated" 314 "CSM GmbH" 313 "Ilmor Engineering, Inc" 312 "Lectronix, Inc." 271 "Cole Hersee" 270 "Tennant" 269 "Saft America Inc.,  Space & Defense Division" 268 "Accurate Technologies" 267 "Red Lion Controls, Inc" 266 "International Thermal Research Ltd" 265 "MTS Sensor Technologie GmbH" 264 "Autolync" 248 "Cooper Standard Automotive Active Systems Group" 247 "ePULSE" 246 "Class 1, Inc" 245 "Capstan Ag Systems, Inc." 244 "Techno-Matic" 243 "eRide, Inc." 242 "Kokusandenki Co. Ltd" 241 "Schneider Automation SAS " 240 "Vanair Mfg" 239 "May & Scofield Ltd" 238 "ZF Friedrichshafen AG" 237 "Agtron Enterprises Inc" 236 "Norac Systems International Inc" 235 "SailorMade Marine Telemetry - Tetra Technology Ltd." 234 "Mondial electronic GmbH" ;
VAL_ 2362179326 Function 127 "Reserved" 126 "Reserved" 125 "Reserved" 124 "Reserved" 123 "Reserved" 122 "Reserved" 121 "Reserved" 120 "Reserved" 119 "Reserved" 118 "Reserved" 117 "Reserved" 116 "Reserved" 115 "Reserved" 114 "Reserved" 113 "Reserved" 112 "Reserved" 111 "Reserved" 110 "Reserved" 109 "Reserved" 108 "Reserved" 107 "Reserved" 106 "Reserved" 105 "Reserved" 104 "Reserved" 103 "Reserved" 102 "Reserved" 101 "Reserved" 42 "Water Pump Control" 41 "Lighting - Operator Controls" 40 "Seat Control" 39 "Ignition Control Module" 38 "Tire Pressure Control" 37 "Cab Controller" 36 "Pneumatic - System Controller" 35 "Suspension - System Controller" 34 "Hydraulic Pump Controller" 33 "System Monitor" 32 "Headway Controller" 31 "Propulsion Battery Charger" 30 "Management Computer" 29 "Virtual Terminal (in cab)" 28 "Off Vehicle Gateway" 27 "Power TakeOff (Secondary or Front)" 26 "Body Controller" 25 "Network Interconnect ECU" 24 "Vehicle Security" 23 "Vehicle Navigation" 22 "Aerodynamic Control" 21 "Cab Climate Control" 20 "Trip Recorder" 19 "Instrument Cluster" 18 "Suspension - Drive Axle" 17 "Suspension - Steer Axle" 16 "Steering Controller" 15 "Fuel System" 14 "Cruise Control" 13 "Retarder - Driveline" 12 "Retarder - Engine" 11 "Brakes - Drive Axle" 10 "Brakes - Steer Axle" 9 "Brakes - System Controller" 8 "Axle - Drive" 7 "Axle - Steering" 6 "Power TakeOff - (Main or Rear)" 5 "Shift Control/Console" 4 "Battery Pack Monitor" 3 "Transmission" 2 "Electric Propulsion Control" 1 "Auxiliary Power Unit (APU)" 0 "Engine" 100 "Reserved" 99 "Reserved" 98 "Reserved" 97 "Reserved" 96 "Reserved" 95 "Reserved" 94 "Reserved" 93 "Reserved" 92 "Reserved" 91 "Reserved" 90 "Reserved" 89 "Reserved" 88 "Reserved" 87 "Reserved" 86 "Reserved" 85 "Reserved" 84 "Reserved" 83 "Reserved" 82 "Reserved" 81 "Reserved" 80 "Reserved" 79 "Reserved" 78 "Fire Suppression System" 77 "Fuel Properties Sensor" 76 "Temperature Sensor" 75 "Supplemental Fan" 74 "Lubrication System" 73 "Rollover Detection Control" 72 "Coolant Valve Controller" 71 "Transfer Case Control" 70 "Auxiliary Regeneration Device" 69 "Engine Emission Aftertreatement System" 68 "Aftertreatment system gas measurement" 67 "Electrical System Controller" 66 "I/O Controller" 65 "Gas Flow Measurement" 64 "Endurance Braking" 63 "Engine Valve Controller" 62 "On-Board Diagnostic Unit" 61 "File Server/Printer" 60 "Cab Display" 59 "Starter" 58 "Fan Drive Control" 57 "Steering Column Unit" 56 "Communications Unit, Radio" 55 "Communications Unit, Satellite" 54 "Communications Unit, Cellular" 53 "Alternator/Charging System" 52 "Chassis Controller" 51 "Forward-Looking Collision Warning System" 50 "Auxiliary Heater" 49 "Clutch/Converter Control" 48 "Ramp Control" 47 "Information System Controller" 46 "Oil Sensor Unit" 45 "Vehicle Dynamic Stability Control" 44 "Exhaust Emission Control" 43 "Transmission Display" ;
VAL_ 2362179326 VehicleSystem2 25 "Slurry Applicators" 24 "Utility Vehicles" 23 "Mulchers" 22 "Timber Processing Machines" 21 "Timber loaders" 20 "Forwarders" 19 "Timber Harvesters" 17 "Sensor Systems" 16 "Skidder" 15 "Earth Work" 14 "Special Crops" 13 "Powered Auxiliary Device" 12 "Farm Yard Operations" 11 "Transport/Trailer" 10 "Irrigation" 9 "Forage" 8 "Root Harvesters" 7 "Harvesters" 6 "Sprayers" 5 "Fertilizers" 4 "Planters/Seeders" 3 "Secondary Tillage" 2 "Tillage" 1 "Tractor" 127 "Not Available" 0 "Non-specific System" ;
VAL_ 2362179326 IndustryGroup 6 "Reserved for SAE" 0 "Global" 1 "On-Highway" 2 "Agricultural and Forestry" 3 "Construction" 4 "Marine" 5 "IndustrialProcessCtrlStationary" 7 "Reserved for SAE" ;
VAL_ 2559835902 ErrorCode 5 "Other" 255 "Not Available" 4 "Pending Name not set" 3 "Checksum does not match" 2 "Item conflict" 1 "Item(s) not allowed to change" 0 "Security not satisfied" ;
VAL_ 2559835902 NMControlModeIndicator 8 "ReqNameAddressClaim" 7 "AdoptPendingName" 6 "ReqCurrentName" 5 "ReqPendingName" 4 "NameNACK" 3 "NameACK" 2 "CurrentName" 1 "PendingName" 0 "SetPendingName" ;
VAL_ 2365408254 MachineSelDirectionCommand 3 "DontCare" 2 "Reserved" 1 "Forward" 0 "Reverse" ;
VAL_ 2364547838 MachineSelectedDirection 3 "NotAvailable" 2 "ErrorIndication" 1 "Forward" 0 "Reverse" ;
VAL_ 2364547838 MachineSelectedSpeedSource 7 "NotAvailable" 6 "Reserved" 5 "Reserved" 4 "SimulatedSpeed" 3 "BlendedSpeed" 2 "NavigationBasedSpeed" 1 "GroundBasedSpeed" 0 "WheelBasedSpeed" ;
VAL_ 2364547838 MachineSelectedSpeedLimitStatus 7 "NotAvailable" 6 "NonRecoverableFault" 5 "Reserved" 4 "Reserved" 3 "LimitedLow" 2 "LimitedHigh" 1 "OperatorLimited_Controlled" 0 "NotLimited" ;
VAL_ 2566801406 MaintainActuatorPower 0 "NoFurtherRequirementForPWR" 1 "RequireForTwoMoreSecOfPWR" 3 "DoNotCare" ;
VAL_ 2566801406 MaintainECUPower 0 "NoFurtherRequireForECU_PWR" 1 "RequireForTwoMoreSecOfECU_PWR" 3 "DoNotCare" ;
VAL_ 2566801406 ImplementWorkState 0 "ImplementIsNotReadyForFieldWork" 1 "ImplementIsReadyForFieldWork" 2 "ErrorIndicator" 3 "NotAvailable" ;
VAL_ 2566801406 ImplementParkState 0 "ImplementMayNotBeDisconneted" 1 "ImplementMayBeDisconnected" 2 "ErrorIndicator" 3 "NotAvailable" ;
VAL_ 2566801406 ImplementTransportState 0 "ImplementMayNotBeTransported" 1 "ImplementMayBeTransported" 2 "ErrorIndication" 3 "NotAvailable" ;
VAL_ 2566787070 TimeFormatCmd 0 "Hour24" 1 "Hour12" 3 "NoAction" ;
VAL_ 2566787070 DecimalSymbolCmd 0 "CommaIsUsed" 1 "PointIsUsed" 3 "NoAction" ;
VAL_ 2566787070 DateFormatCmd 0 "ddmmyyyy" 1 "ddyyyymm" 2 "mmyyyydd" 3 "mmddyyyy" 4 "yyyymmdd" 5 "yyyyddmm" ;
VAL_ 2566787070 MassUnitCmd 0 "Metric" 1 "Imperial" 2 "TonsPounds" 3 "NoAction" ;
VAL_ 2566787070 VolumeUnitCmd 0 "Metric" 1 "Imperial" 2 "US" 3 "NoAction" ;
VAL_ 2566787070 AreaUnitCmd 0 "Metric" 1 "Imperial" 3 "NoAction" ;
VAL_ 2566787070 DistanceUnitCmd 0 "Metric" 1 "Imperial" 3 "NoAction" ;
VAL_ 2566787070 UnitsSystem 0 "Metric" 1 "Imperial" 2 "US" 3 "NoAction" ;
VAL_ 2566787070 ForceUnits 0 "Metric" 1 "Imperial" 2 "Reserved" 3 "NoAction" ;
VAL_ 2566787070 PressureUnits 0 "Metric" 1 "Imperial" 2 "Reserved" 3 "NoAction" ;
VAL_ 2566787070 TemperatureUnits 0 "Metric" 1 "Imperial" 2 "Reserved" 3 "NoAction" ;
VAL_ 2365459198 TractorControlLimitStatus1 7 "Not available" 6 "Non-recoverable Fault" 5 "Reserver" 4 "Reserved" 3 "Limited Low" 2 "Limited High" 1 "Operator Limited" 0 "Not limited" ;
VAL_ 2365459198 TractorControlModeResponse1 0 "DisableRemoteControl" 1 "EnableGroundSpeedCruiseControl" 2 "EnableWheelSpeedCruiseControl" 3 "EnableNavigationSpeedCruiseCtrl" 4 "EnableFrontHitchSlipCtrl" 5 "EnableRearHitchSlipControl" 6 "EnableFrontPTOSlipControl" 7 "EnableRearPTOSlipControl" 8 "EnableAuxiliaryValveSlipControl" 9 "EnableReduceSpeedSlipControl" 10 "EnableMaximumDraftPowerControl" 11 "EnableConstantPTOSpeedControl" 12 "EnCoPTOSpeedGndSpeedCruisCtrl" 13 "EnCoPTOSpeedWheelSpeedCruiseCtrl" 14 "EnCoPTOSpeedNavigSpeedCruisCtrl" 15 "EnableMinimumEngineSpeedControl" 16 "EnEngineEcoSpdGndSpeedCruiseCtrl" 17 "EnEngineEcoSpdWheelSpdCrusieCtrl" 18 "EnEngineEcoSpdNavigSpdCruiseCtrl" 19 "EnableFrontPTOTorqueControl" 20 "EnableRearPTOTorqueControl" 21 "EnableFrontDraftForceControl" 22 "EnableRearDraftForceControl" 23 "EnableGuidanceControl" 31 "NotAvailable" ;
VAL_ 2365459198 TractorControlLimitStatus2 7 "Not available" 6 "Non-recoverable Fault" 5 "Reserver" 4 "Reserved" 3 "Limited Low" 2 "Limited High" 1 "Operator Limited" 0 "Not limited" ;
VAL_ 2365459198 TractorControlModeResponse2 0 "DisableRemoteControl" 1 "EnableGroundSpeedCruiseControl" 2 "EnableWheelSpeedCruiseControl" 3 "EnableNavigationSpeedCruiseCtrl" 4 "EnableFrontHitchSlipCtrl" 5 "EnableRearHitchSlipControl" 6 "EnableFrontPTOSlipControl" 7 "EnableRearPTOSlipControl" 8 "EnableAuxiliaryValveSlipControl" 9 "EnableReduceSpeedSlipControl" 10 "EnableMaximumDraftPowerControl" 11 "EnableConstantPTOSpeedControl" 12 "EnCoPTOSpeedGndSpeedCruisCtrl" 13 "EnCoPTOSpeedWheelSpeedCruiseCtrl" 14 "EnCoPTOSpeedNavigSpeedCruisCtrl" 15 "EnableMinimumEngineSpeedControl" 16 "EnEngineEcoSpdGndSpeedCruiseCtrl" 17 "EnEngineEcoSpdWheelSpdCrusieCtrl" 18 "EnEngineEcoSpdNavigSpdCruiseCtrl" 19 "EnableFrontPTOTorqueControl" 20 "EnableRearPTOTorqueControl" 21 "EnableFrontDraftForceControl" 22 "EnableRearDraftForceControl" 23 "EnableGuidanceControl" 31 "NotAvailable" ;
VAL_ 2365459454 TractorControlModeCmd1 0 "DisableRemoteControl" 1 "EnableCruiseControl" 2 "EnableFrontHitchSlipControl" 3 "EnableRearHitchSlipControl" 4 "EnableFrontPTOSlipControl" 5 "EnableRearPTOSlipControl" 6 "EnableReduceSpeedSlipControl" 7 "EnableAuxiliaryValveSlipControl" 8 "EnableMaximumDraftPowerControl" 9 "EnableConstantPTOSpeedControl" 10 "EnableConstPTOSpeedCruiseControl" 11 "EnableMinimumEngineSpeedControl" 12 "EnableEngineEconomyCruiseControl" 13 "EnableFrontPTOTorqueControl" 14 "EnableRearPTOTorqueControl" 15 "EnableFrontDraftForceControl" 16 "EnableRearDraftForceControl" 17 "EnableGuidanceControl" 31 "DontCare" ;
VAL_ 2365459454 TactorControlModeCmd2 0 "DisableRemoteControl" 1 "EnableCruiseControl" 2 "EnableFrontHitchSlipControl" 3 "EnableRearHitchSlipControl" 4 "EnableFrontPTOSlipControl" 5 "EnableRearPTOSlipControl" 6 "EnableReduceSpeedSlipControl" 7 "EnableAuxiliaryValveSlipControl" 8 "EnableMaximumDraftPowerControl" 9 "EnableConstantPTOSpeedControl" 10 "EnableConstPTOSpeedCruiseControl" 11 "EnableMinimumEngineSpeedControl" 12 "EnableEngineEconomyCruiseControl" 13 "EnableFrontPTOTorqueControl" 14 "EnableRearPTOTorqueControl" 15 "EnableFrontDraftForceControl" 16 "EnableRearDraftForceControl" 17 "EnableGuidanceControl" 18 "UserDefinedControl" 31 "DoNotCare" ;
VAL_ 2365391616 ImplementOperatingStateCmd 3 "TakeNoAction" 2 "SetImplementToParkState" 1 "SetImplementToTransportState" 0 "SetImplementToFieldWorkingState" ;
VAL_ 2566734590 CertTypeTCSectionControlWSMember 1 "Certification test performed" 0 "Not certified" ;
VAL_ 2566734590 CertTypeTCSectionControl 1 "Certification test performed" 0 "Not certified" ;
VAL_ 2566734590 CertTypeSeqControlMaster 1 "Certification test performed" 0 "Not certified" ;
VAL_ 2566734590 CertTypeSecControlClient 1 "Certification test performed" 0 "Not certified" ;
VAL_ 2566734590 CertTypeFileClient 1 "Certification test performed" 0 "Not certified" ;
VAL_ 2566734590 CertTypeDataLoggerWSMember 1 "Certification test performed" 0 "Not certified" ;
VAL_ 2566734590 CertTypeDataLoggerWSMaster 1 "Certification test performed" 0 "Not certified" ;
VAL_ 2566734590 CertTypeDataLogger 1 "Certification test performed" 0 "Not certified" ;
VAL_ 2566734590 CertTypeAuxControlInUnit 1 "Certification test performed" 0 "Not certified" ;
VAL_ 2566734590 CertTypeAuxControlFunc 1 "Certification test performed" 0 "Not certified" ;
VAL_ 2566734590 CertificateRevision 3 "NotAvailable" 2 "ThirdRevision" 1 "SecondRevision" 0 "FirstRevision" ;
VAL_ 2566734590 CertificateLaboratoryType 7 "Not available (not certified) " 2 "Reserved " 1 "AEF certified laboratory " 0 "Non-certified Laboratory" ;
VAL_ 2566734590 CertTypeVTWorkingSetMember 1 "CertificationTestPerformed" 0 "NotCertified" ;
VAL_ 2566734590 CertTypeVTWorkingSetMaster 1 "CertificationTestPerformed" 0 "NotCertified" ;
VAL_ 2566734590 CertTypeVirtualTerminal 1 "CertificationTestPerformed" 0 "NotCertified" ;
VAL_ 2566734590 CertTypeClass3ECU 1 "CertificationTestPerformed" 0 "NotCertified" ;
VAL_ 2566734590 CertTypeTECUClass3 1 "CertificationTestPerformed" 0 "NotCertified" ;
VAL_ 2566734590 CertTypeTECUClass2 1 "CertificationTestPerformed" 0 "NotCertified" ;
VAL_ 2566734590 CertTypeTECUClass1 1 "CertificationTestPerformed" 0 "NotCertified" ;
VAL_ 2566734590 CertTypeMinimumECU 1 "CertificationTestPerformed" 0 "NotCertified" ;
VAL_ 2566734590 CertTypeGPSReceiver 1 "CertificationTestPerformed" 0 "NotCertified" ;
VAL_ 2566734590 CertTypeFileServer 1 "CertificationTestPerformed" 0 "NotCertified" ;
VAL_ 2566734590 CertTypeTCWorkingSetMember 1 "CertificationTestPerformed" 0 "NotCertified" ;
VAL_ 2566734590 CertTypeTCWorkingSetMaster 1 "CertificationTestPerformed" 0 "NotCertified" ;
VAL_ 2566734590 CertTypeTaskController 1 "CertificationTestPerformed" 0 "NotCertified" ;
VAL_ 2566734590 CertificationReferenceNumber 1 "CertificationTestPerformed" 0 "NotCertified" ;
VAL_ 2365473534 RearPTOEngagementCmd 0 "DisengagePTO" 1 "EngangePTO" 3 "DoNotCare" ;
VAL_ 2365473534 FrontPTOEngagementCmd 0 "DisengagePTO" 1 "EngagePTO" 3 "DoNotCare" ;
VAL_ 2365473534 RearPTOEconomyModeCmd 0 "DisengagePTOEconomyMode" 1 "EngagePTOEconomyMode" 3 "DoNotCare" ;
VAL_ 2365473534 FrontPTOEconomyModeCmd 0 "DisengagePTOEconomyMode" 1 "EngagePTOEconomyMode" 3 "DoNotCare" ;
VAL_ 2365473534 RearPTOModeCmd 0 "Select540rpmMode" 1 "Select1000rpmMode" 3 "DoNotCare" ;
VAL_ 2365473534 FrontPTOModeCmd 0 "Select540rpmMode" 1 "Select1000rpmMode" 3 "DoNotCare" ;
VAL_ 2360213246 CurvatureCommandStatus 0 "NotIntendedToSteer" 1 "IntendedToSteer" 2 "Error" 3 "NotAvailable" ;
VAL_ 2563047166 StateCmd 0 "Block" 1 "Extend" 2 "Retract" 3 "Float" 15 "Reserved" ;
VAL_ 2563047166 FailSaveModeCmd 0 "Block" 1 "Float" 3 "DoNotCare" ;
VAL_ 2563112702 ValveLimitStatus 7 "Not available" 6 "Non-recoverable Fault" 5 "Reserver" 4 "Reserved" 3 "Limited Low" 2 "Limited High" 1 "Operator Limited" 0 "Not limited" ;
VAL_ 2563178238 ValveState 0 "Blocked" 1 "Extend" 2 "Retract" 3 "Floating" 14 "ErrorIndication" 15 "DoNotCare" ;
VAL_ 2563178238 FailSafeMode 0 "Block" 1 "Float" 2 "ErrorIndication" 3 "NotAvailable" ;
VAL_ 2563178238 ValveLimitStatus 7 "Not available" 6 "Non-recoverable Fault" 5 "Reserver" 4 "Reserved" 3 "Limited Low" 2 "Limited High" 1 "Operator Limited" 0 "Not limited" ;
VAL_ 2583168510 TypeOfSystem 0 "GPS" 1 "GLONASS" 2 "GPS and GLONASS" 3 "GPS and SBAS(WAAS)" 4 "GPS and SBAS and GLONASS" ;
VAL_ 2583168510 GNSSMethod 0 "no GPS" 1 "GNSS fix" 2 "DGNSS fix" 3 "Precise GNSS" 4 "RTK fixed integer" 5 "RTK float" 6 "Estimated (DR) mode" 7 "Manual input" 8 "Simulate mode" 14 "Error" ;
VAL_ 2583168510 GNSSIntegrity 0 "No integrity checking" 1 "Safe" 2 "Caution" 3 "Unsafe" ;
VAL_ 2583168510 RefrenceStationType1 0 "GPS" 1 "GLONASS" 14 "Error" ;
VAL_ 2360147710 MechanicalSystemLockout 0 "NotActive" 1 "Active" 2 "Error" 3 "NotAvailable" ;
VAL_ 2360147710 SteeringSystemReadiness 0 "SystemIsNotReady" 1 "SystemIsReady" 2 "Error" 3 "NotAvailable" ;
VAL_ 2360147710 SteeringInputPositionStatus 0 "NotTheCorrectPosition" 1 "CorrectPosition" 2 "Error" 3 "NotAvailable" ;
VAL_ 2360147710 RequestResetCommandStatus 0 "ResetNotRequired" 1 "ResetRequired" 2 "Error" 3 "NotAvailable" ;
VAL_ 2365475326 GroundBasedMachineDirection 0 "Reverse" 1 "Forward" 2 "ErrorIndication" 3 "NotAvailable" ;
VAL_ 2628517630 FSServerCommand 2 "VSVolumeStatusResponse" 1 "CMGetFileServerProperties" 64 "VHVolumeInitialization" 52 "FHGetFileDateTime" 17 "DHChangeCurrentDirectory" 51 "FHSetFileAttribute" 50 "FHGetFileAttributes" 49 "FHDeleteFile" 48 "FHMoveFile" 36 "FACloseFile" 35 "FAWriteFile" 34 "FAReadFile" 33 "FASeekFile" 32 "FAOpenFile" 16 "DHGetCurrentDirectory" 0 "CMFileServerStatus" ;
VAL_ 2628517630 VS_VolumeStatus 3 "Removed" 2 "PreparingForRemoval" 1 "InUse" 0 "Present" ;
VAL_ 2628517630 GSP_VersionNumber 255 "CompliantToVersion2AndPrior" 3 "FirstPublishedEditionAndAmd1OfIS" 2 "FirstPublishedEditionOfIS" 1 "FDIS" 0 "DIS" ;
VAL_ 2628517630 VI_ErrorCode 13 "Volume possibly not initialized" 11 "Failure during read operation" 10 "Media is not present" 43 "Out of memory" 44 "Any other error" 42 "Invalid request length" 9 "Failure during write operation" 8 "Volume out of free space" 6 "Invalid given source name" 4 "File, path or volume not found" 1 "Access Denied" 0 "Success" ;
VAL_ 2628517630 DF_ErrorCode 13 "Volume possibly not initialized" 11 "Failure during read operation" 9 "Failure during write operation" 43 "Out of memory" 44 "Any other error" 10 "Media is not present" 6 "Invalid given source name" 4 "File, path or volume not found" 1 "Access Denied" 0 "Success" ;
VAL_ 2628517630 CCD_ErrorCode 7 "Invalid destination name given" 4 "File, path or volume not found" 2 "Invalid Access" 1 "Access denied" 13 "Volume possibly not initialized" 43 "Out of memory" 44 "Any other error" 10 "Media is not present" 0 "Success" ;
VAL_ 2628517630 GCD_ErrorCode 13 "Volume possibly not initialized" 43 "Out of Memory" 44 "Any other error" 10 "Media is not present" 0 "Success" ;
VAL_ 2628517630 SA_ErrorCode 13 "Volume possibly not initialized" 11 "Failure during read operation" 43 "Out of memory" 44 "Any other error" 10 "Media is not present" 9 "Failure during write operation" 8 "Volume out of free space" 6 "Invalid given source name" 4 "File, path or volume not found" 3 "Too many files open" 1 "Access Denied" 0 "Success" ;
VAL_ 2628517630 GA_ErrorCode 13 "Volume possibly not initialized" 11 "Failure during read operation" 43 "Out of memory" 44 "Any other error" 10 "Media is not present" 6 "Invalid given source name" 4 "File, path or volume not found" 3 "Too many files open" 1 "Access Denied" 0 "Success" ;
VAL_ 2628517630 MF_ErrorCode 13 "Volume possibly not initialized" 4 "File, path or volume not found" 43 "Out of memory" 44 "Any other error" 10 "Media is not present" 9 "Verify failure during a write op" 8 "Volume out of free space" 7 "Invalid given destination name" 6 "Invalid given source name" 3 "Too many files open" 1 "Access Denied" 0 "Success" ;
VAL_ 2628517630 CF_ErrorCode 43 "Out ot memory" 44 "Any other error" 9 "Failure during a write operation" 8 "Volume out of free space" 5 "Invalid handle" 1 "Access Denied" 0 "Success" ;
VAL_ 2628517630 WF_ErrorCode 43 "Out of memory" 44 "Any other error" 42 "Invalid request length" 9 "Failure during a write operation" 8 "Volume out of free space" 5 "Invalid handle" 1 "Access Denied" 0 "Success" ;
VAL_ 2628517630 OF_ErrorCode 13 "Volume possibly not initialized" 43 "Out of memory" 44 "Any other error" 10 "Media is not present" 8 "Volume out of free space" 6 "Invalid given source name" 4 "File, path or volume not found" 3 "Too many files open" 2 "Invalid Access" 1 "Access Denied" 0 "Success" ;
VAL_ 2628517630 SF_ErrorCode 43 "Out of memory" 11 "Failure during read operation" 45 "File pointer at end of file" 44 "Any other error" 42 "Invalid request length" 5 "Invalid handle" 0 "Success" ;
VAL_ 2628517630 RF_ErrorCode 1 "Access denied" 43 "Out of memory" 11 "Failure during read operation" 0 "Success" 5 "Invalid handle" 42 "Invalid request length" 44 "Any other error" 45 "File pointer at end of file" ;
VAL_ 2628517630 FDT_ErrorCode 13 " Volume possibly not initialized" 11 "Failure during a read operation" 43 "Out ot memory" 44 "Any other error" 10 "Media is not present" 6 "Invalid given source name" 4 "File, path or volume not found" 3 "Too many files open" 1 "Access Denied" 0 "Success" ;
VAL_ 2628517630 GSP_SupportMultipleVolumes 0 "Beschreibung für den Wert '0'" ;
VAL_ 2628517630 GA_ATTR_ReadOnly 1 "'Read-only' attribute is set" 0 "'Read-only' attribute is not set" ;
VAL_ 2628517630 GA_ATTR_Hidden 1 "'Hidden' attribute is set" 0 "'Hidden' attribute is not set" ;
VAL_ 2628517630 GA_ATTR_VolSupportsHiddenAttr 1 "Volume supports hidden attribute" 0 "Volume not support hidden attr." ;
VAL_ 2628517630 GA_ATTR_IsVolume 1 "'System' attribute is set" 0 "'System' attribute is not set" ;
VAL_ 2628517630 VI_ATTR_Directory 1 "Handle specifies a directory" 0 "Handle does not specify a dir" ;
VAL_ 2628517630 GA_ATTR_SupportsLongFilenames 1 "Volume supports long filenames" 0 "Volume supports no long filename" ;
VAL_ 2628517630 GA_ATTR_VolumeRemovable 1 "Volume is not removable" 0 "Volume is removable" ;
SG_MUL_VAL_ 2362179326 NumberOfControlChannels TechnicalDataMsgType 1-1;
SG_MUL_VAL_ 2362179326 ErrorElementNumber Command 13-13;
SG_MUL_VAL_ 2362179326 ElementNumber Command 2-10;
SG_MUL_VAL_ 2362179326 DeviceDescriptionMsgType Command 1-1;
SG_MUL_VAL_ 2362179326 TechnicalDataMsgType Command 0-0;
SG_MUL_VAL_ 2362179326 ErrorCodeObjPoolActiveResp1 DeviceDescriptionMsgType 9-9;
SG_MUL_VAL_ 2362179326 ObjectIdChanged DeviceDescriptionMsgType 13-13;
SG_MUL_VAL_ 2362179326 ObjectIdToChange DeviceDescriptionMsgType 12-12;
SG_MUL_VAL_ 2362179326 ErrorCodeObjectPoolDelete DeviceDescriptionMsgType 11-11;
SG_MUL_VAL_ 2362179326 ActivateDeactivateCommand DeviceDescriptionMsgType 8-8;
SG_MUL_VAL_ 2362179326 ErrorCodeObjPoolTransfer DeviceDescriptionMsgType 7-7;
SG_MUL_VAL_ 2362179326 Status DeviceDescriptionMsgType 5-5;
SG_MUL_VAL_ 2362179326 RequestTransferDataSize DeviceDescriptionMsgType 4-4;
SG_MUL_VAL_ 2362179326 VersionNumberISO11783Part10 TechnicalDataMsgType 1-1;
SG_MUL_VAL_ 2362179326 StructureLabel DeviceDescriptionMsgType 0-0, 1-1;
SG_MUL_VAL_ 2362179326 ErrorCodeObjPoolActiveResp2 DeviceDescriptionMsgType 9-9;
SG_MUL_VAL_ 2362179326 ErrorCodeObjPoolActiveResp3 DeviceDescriptionMsgType 9-9;
SG_MUL_VAL_ 2362179326 LanguageCodeCmd DeviceDescriptionMsgType 3-3;
SG_MUL_VAL_ 2362179326 PeerControlDDI Command 9-9;
SG_MUL_VAL_ 2362179326 BootTimeTC TechnicalDataMsgType 1-1;
SG_MUL_VAL_ 2362179326 DDI Command 2-2, 3-3, 6-8, 10-10;
SG_MUL_VAL_ 2362179326 ReceivedDataSize DeviceDescriptionMsgType 7-7;
SG_MUL_VAL_ 2362179326 ParentObjectIdOfFaultyObject DeviceDescriptionMsgType 9-9;
SG_MUL_VAL_ 2362179326 ErrorDDI Command 13-13;
SG_MUL_VAL_ 2362179326 DDI_DI Command 5-5;
SG_MUL_VAL_ 2362179326 DDI_TI Command 4-4;
SG_MUL_VAL_ 2362179326 DesignatorLength DeviceDescriptionMsgType 12-12;
SG_MUL_VAL_ 2362179326 ErrorCodeChangeDesignator DeviceDescriptionMsgType 13-13;
SG_MUL_VAL_ 2362179326 Documentation TechnicalDataMsgType 1-1;
SG_MUL_VAL_ 2362179326 TimeAndPositionForDataLogging TechnicalDataMsgType 1-1;
SG_MUL_VAL_ 2362179326 TC_GEO_DefinitionPositionBasedCo TechnicalDataMsgType 1-1;
SG_MUL_VAL_ 2362179326 PeerControlAssignment TechnicalDataMsgType 1-1;
SG_MUL_VAL_ 2362179326 ImplementSectionControl TechnicalDataMsgType 1-1;
SG_MUL_VAL_ 2362179326 TimeFormatCmd DeviceDescriptionMsgType 3-3;
SG_MUL_VAL_ 2362179326 DecimalSymbolCmd DeviceDescriptionMsgType 3-3;
SG_MUL_VAL_ 2362179326 PeerControlCommand Command 9-9;
SG_MUL_VAL_ 2362179326 DataDictionaryVersion DDI 0-0;
SG_MUL_VAL_ 2362179326 DateFormatCmd DeviceDescriptionMsgType 3-3;
SG_MUL_VAL_ 2362179326 Status_TotalsActive Command 15-15;
SG_MUL_VAL_ 2362179326 StatusTotalsActive Command 14-14;
SG_MUL_VAL_ 2362179326 ErrorCodeProcessData1 Command 13-13;
SG_MUL_VAL_ 2362179326 ObjectIdOfFaultyObject DeviceDescriptionMsgType 9-9;
SG_MUL_VAL_ 2362179326 RequestDefaultProcessData DDI 57343-57343;
SG_MUL_VAL_ 2362179326 PGNBasedData DDI 57342-57342;
SG_MUL_VAL_ 2362179326 LastUnloadedWeight DDI 321-321;
SG_MUL_VAL_ 2362179326 LastLoadedWeight DDI 320-320;
SG_MUL_VAL_ 2362179326 IneffectiveTotalDieselExhaustFlu DDI 319-319;
SG_MUL_VAL_ 2362179326 EffectiveTotalDieselExhaustFluid DDI 318-318;
SG_MUL_VAL_ 2362179326 IneffectiveTotalFuelConsumption DDI 317-317;
SG_MUL_VAL_ 2362179326 EffectiveTotalFuelConsumption DDI 316-316;
SG_MUL_VAL_ 2362179326 AveragePercentageCropDryMatter DDI 315-315;
SG_MUL_VAL_ 2362179326 ActualPercentageCropDryMatter DDI 314-314;
SG_MUL_VAL_ 2362179326 MaximumRelativeYieldPotential DDI 313-313;
SG_MUL_VAL_ 2362179326 MinimumRelativeYieldPotential DDI 312-312;
SG_MUL_VAL_ 2362179326 RelativeYieldPotential DDI 311-311;
SG_MUL_VAL_ 2362179326 MaximumPercentageApplicationRate DDI 310-310;
SG_MUL_VAL_ 2362179326 MinimumPercentageApplicationRate DDI 309-309;
SG_MUL_VAL_ 2362179326 ActualPercentageApplicationRate DDI 308-308;
SG_MUL_VAL_ 2362179326 TrueRotationPointYOffset DDI 307-307;
SG_MUL_VAL_ 2362179326 TrueRotationPointXOffset DDI 306-306;
SG_MUL_VAL_ 2362179326 SetpointCondensedWorkState241to2 DDI 305-305;
SG_MUL_VAL_ 2362179326 SetpointCondensedWorkState225to2 DDI 304-304;
SG_MUL_VAL_ 2362179326 SetpointCondensedWorkState209to2 DDI 303-303;
SG_MUL_VAL_ 2362179326 SetpointCondensedWorkState193to2 DDI 302-302;
SG_MUL_VAL_ 2362179326 SetpointCondensedWorkState177to1 DDI 301-301;
SG_MUL_VAL_ 2362179326 SetpointCondensedWorkState161to1 DDI 300-300;
SG_MUL_VAL_ 2362179326 SetpointCondensedWorkState145to1 DDI 299-299;
SG_MUL_VAL_ 2362179326 SetpointCondensedWorkState129to1 DDI 298-298;
SG_MUL_VAL_ 2362179326 SetpointCondensedWorkState113to1 DDI 297-297;
SG_MUL_VAL_ 2362179326 SetpointCondensedWorkState97to11 DDI 296-296;
SG_MUL_VAL_ 2362179326 SetpointCondensedWorkState81to96 DDI 295-295;
SG_MUL_VAL_ 2362179326 SetpointCondensedWorkState65to80 DDI 294-294;
SG_MUL_VAL_ 2362179326 SetpointCondensedWorkState49to64 DDI 293-293;
SG_MUL_VAL_ 2362179326 SetpointCondensedWorkState33to48 DDI 292-292;
SG_MUL_VAL_ 2362179326 SetpointCondensedWorkState17to32 DDI 291-291;
SG_MUL_VAL_ 2362179326 SetpointCondensedWorkState1to16 DDI 290-290;
SG_MUL_VAL_ 2362179326 SetpointWorkState DDI 289-289;
SG_MUL_VAL_ 2362179326 LifetimeUncutTotalCount DDI 286-286;
SG_MUL_VAL_ 2362179326 LifetimePrecutTotalCount DDI 285-285;
SG_MUL_VAL_ 2362179326 UncutTotalCount DDI 284-284;
SG_MUL_VAL_ 2362179326 PrecutTotalCount DDI 283-283;
SG_MUL_VAL_ 2362179326 LifetimeThreshingEngagementTotal DDI 282-282;
SG_MUL_VAL_ 2362179326 LifetimeYieldTotalLintCottonMass DDI 281-281;
SG_MUL_VAL_ 2362179326 LifetimeYieldTotalSeedCottonMass DDI 280-280;
SG_MUL_VAL_ 2362179326 LifetimeYieldTotalDryMass DDI 279-279;
SG_MUL_VAL_ 2362179326 LifetimeAverageFuelConsumptionPe DDI 278-278;
SG_MUL_VAL_ 2362179326 LifetimeAverageFuelConsumpt_0000 DDI 277-277;
SG_MUL_VAL_ 2362179326 LifetimeFuelConsumption DDI 276-276;
SG_MUL_VAL_ 2362179326 LifetimeIneffectiveTotalTime DDI 275-275;
SG_MUL_VAL_ 2362179326 LifetimeEffectiveTotalTime DDI 274-274;
SG_MUL_VAL_ 2362179326 LifetimeIneffectiveTotalDistance DDI 273-273;
SG_MUL_VAL_ 2362179326 LifetimeTotalDistance DDI 272-272;
SG_MUL_VAL_ 2362179326 LifetimeTotalArea DDI 271-271;
SG_MUL_VAL_ 2362179326 LifetimeYieldTotalCount DDI 270-270;
SG_MUL_VAL_ 2362179326 LifetimeYieldTotalMass DDI 269-269;
SG_MUL_VAL_ 2362179326 LifetimeYieldTotalVolume DDI 268-268;
SG_MUL_VAL_ 2362179326 LifetimeApplicationTotalCount DDI 267-267;
SG_MUL_VAL_ 2362179326 LifetimeApplicationTotalMass DDI 266-266;
SG_MUL_VAL_ 2362179326 RemainingArea DDI 265-265;
SG_MUL_VAL_ 2362179326 ConnectorPivotXOffset DDI 264-264;
SG_MUL_VAL_ 2362179326 AverageYieldMassPerArea DDI 263-263;
SG_MUL_VAL_ 2362179326 AverageCropMoisture DDI 262-262;
SG_MUL_VAL_ 2362179326 AverageYieldMassPerTime DDI 261-261;
SG_MUL_VAL_ 2362179326 YieldLeadIgnoreTime DDI 260-260;
SG_MUL_VAL_ 2362179326 YieldLagIgnoreTime DDI 259-259;
SG_MUL_VAL_ 2362179326 HydraulicOilTemperature DDI 258-258;
SG_MUL_VAL_ 2362179326 MaximumSeparationFanRotationalSp DDI 257-257;
SG_MUL_VAL_ 2362179326 MinimumSeparationFanRotationalSp DDI 256-256;
SG_MUL_VAL_ 2362179326 ActualSeparationFanRotationalSpe DDI 255-255;
SG_MUL_VAL_ 2362179326 SetpointSeparationFanRotationalS DDI 254-254;
SG_MUL_VAL_ 2362179326 MaximumConcaveClearance DDI 253-253;
SG_MUL_VAL_ 2362179326 MinimumConcaveClearance DDI 252-252;
SG_MUL_VAL_ 2362179326 ActualConcaveClearance DDI 251-251;
SG_MUL_VAL_ 2362179326 SetpointConcaveClearance DDI 250-250;
SG_MUL_VAL_ 2362179326 MaximumChafferClearance DDI 249-249;
SG_MUL_VAL_ 2362179326 MinimumChafferClearance DDI 248-248;
SG_MUL_VAL_ 2362179326 ActualChafferClearance DDI 247-247;
SG_MUL_VAL_ 2362179326 SetpointChafferClearance DDI 246-246;
SG_MUL_VAL_ 2362179326 MaximumSieveClearance DDI 245-245;
SG_MUL_VAL_ 2362179326 MinimumSieveClearance DDI 244-244;
SG_MUL_VAL_ 2362179326 ActualSieveClearance DDI 243-243;
SG_MUL_VAL_ 2362179326 SetpointSieveClearance DDI 242-242;
SG_MUL_VAL_ 2362179326 CropTemperature DDI 241-241;
SG_MUL_VAL_ 2362179326 ActualUnLoadingSystemStatus DDI 240-240;
SG_MUL_VAL_ 2362179326 YieldHoldStatus DDI 239-239;
SG_MUL_VAL_ 2362179326 ActualHeaderRotationalSpeedStatu DDI 238-238;
SG_MUL_VAL_ 2362179326 ActualHeaderWorkingHeightStatus DDI 237-237;
SG_MUL_VAL_ 2362179326 ThreshingEngagementTotalTime DDI 236-236;
SG_MUL_VAL_ 2362179326 MaximumGrossWeight DDI 235-235;
SG_MUL_VAL_ 2362179326 MinimumGrossWeight DDI 234-234;
SG_MUL_VAL_ 2362179326 GrossWeightState DDI 233-233;
SG_MUL_VAL_ 2362179326 ActualGrossWeight DDI 232-232;
SG_MUL_VAL_ 2362179326 SetpointNetWeight DDI 231-231;
SG_MUL_VAL_ 2362179326 NetWeightState DDI 230-230;
SG_MUL_VAL_ 2362179326 ActualNetWeight DDI 229-229;
SG_MUL_VAL_ 2362179326 MaximumWorkingLength DDI 228-228;
SG_MUL_VAL_ 2362179326 MinimumWorkingLength DDI 227-227;
SG_MUL_VAL_ 2362179326 ActualWorkingLength DDI 226-226;
SG_MUL_VAL_ 2362179326 SetpointWorkingLength DDI 225-225;
SG_MUL_VAL_ 2362179326 DeltaT DDI 224-224;
SG_MUL_VAL_ 2362179326 LastBaleMass DDI 223-223;
SG_MUL_VAL_ 2362179326 LastBaleTagNumber DDI 222-222;
SG_MUL_VAL_ 2362179326 LastBaleAppliedPreservative DDI 221-221;
SG_MUL_VAL_ 2362179326 LastBaleAverageBaleCompressionPl DDI 220-220;
SG_MUL_VAL_ 2362179326 ActualBaleCompressionPlungerLoad DDI 219-219;
SG_MUL_VAL_ 2362179326 SetpointBaleCompressionPlungerLo DDI 218-218;
SG_MUL_VAL_ 2362179326 LastBaleAverageHydraulicPressure DDI 217-217;
SG_MUL_VAL_ 2362179326 ActualBaleHydraulicPressure DDI 216-216;
SG_MUL_VAL_ 2362179326 LifetimeWorkingHours DDI 215-215;
SG_MUL_VAL_ 2362179326 LifetimeBaleCount DDI 214-214;
SG_MUL_VAL_ 2362179326 LastBaleAverageStrokesPerFlake DDI 213-213;
SG_MUL_VAL_ 2362179326 LastBaleAverageMoisture DDI 212-212;
SG_MUL_VAL_ 2362179326 LastBaleFlakesPerBale DDI 211-211;
SG_MUL_VAL_ 2362179326 SkyConditions DDI 210-210;
SG_MUL_VAL_ 2362179326 AirHumidity DDI 209-209;
SG_MUL_VAL_ 2362179326 WindDirection DDI 208-208;
SG_MUL_VAL_ 2362179326 WindSpeed DDI 207-207;
SG_MUL_VAL_ 2362179326 SCTurnOffTime DDI 206-206;
SG_MUL_VAL_ 2362179326 SCTurnOnTime_ DDI 205-205;
SG_MUL_VAL_ 2362179326 MaximumTankAgitationPressure DDI 204-204;
SG_MUL_VAL_ 2362179326 MinimumTankAgitationPressure DDI 203-203;
SG_MUL_VAL_ 2362179326 ActualTankAgitationPressure DDI 202-202;
SG_MUL_VAL_ 2362179326 SetpointTankAgitationPressure DDI 201-201;
SG_MUL_VAL_ 2362179326 MaximumPumpOutputPressure DDI 200-200;
SG_MUL_VAL_ 2362179326 MinimumPumpOutputPressure DDI 199-199;
SG_MUL_VAL_ 2362179326 ActualPumpOutputPressure DDI 198-198;
SG_MUL_VAL_ 2362179326 SetpointPumpOutputPressure DDI 197-197;
SG_MUL_VAL_ 2362179326 MaximumProductPressure DDI 196-196;
SG_MUL_VAL_ 2362179326 MinimumProductPressure DDI 195-195;
SG_MUL_VAL_ 2362179326 ActualProductPressure DDI 194-194;
SG_MUL_VAL_ 2362179326 SetpointProductPressure DDI 193-193;
SG_MUL_VAL_ 2362179326 AmbientTemperature DDI 192-192;
SG_MUL_VAL_ 2362179326 LintTurnoutPercentage DDI 191-191;
SG_MUL_VAL_ 2362179326 YieldTotalLintCottonMass DDI 190-190;
SG_MUL_VAL_ 2362179326 YieldTotalSeedCottonMass DDI 189-189;
SG_MUL_VAL_ 2362179326 LintCottonMassPerTimeYield DDI 188-188;
SG_MUL_VAL_ 2362179326 SeedCottonMassPerTimeYield DDI 187-187;
SG_MUL_VAL_ 2362179326 LintCottonMassPerAreaYield DDI 186-186;
SG_MUL_VAL_ 2362179326 SeedCottonMassPerAreaYield DDI 185-185;
SG_MUL_VAL_ 2362179326 RefMoistureForDryMass DDI 184-184;
SG_MUL_VAL_ 2362179326 YieldTotalDryMass DDI 183-183;
SG_MUL_VAL_ 2362179326 DryMassPerTimeYield DDI 182-182;
SG_MUL_VAL_ 2362179326 DryMassPerAreaYield DDI 181-181;
SG_MUL_VAL_ 2362179326 DRP2GroundDistance DDI 180-180;
SG_MUL_VAL_ 2362179326 ActualCulturalPractice DDI 179-179;
SG_MUL_VAL_ 2362179326 ElementTypeInstance DDI 178-178;
SG_MUL_VAL_ 2362179326 ActualLengthOfCut DDI 177-177;
SG_MUL_VAL_ 2362179326 CondensedWorkState241to256 DDI 176-176;
SG_MUL_VAL_ 2362179326 CondensedWorkState225to240 DDI 175-175;
SG_MUL_VAL_ 2362179326 CondensedWorkState209to224 DDI 174-174;
SG_MUL_VAL_ 2362179326 CondensedWorkState193to208 DDI 173-173;
SG_MUL_VAL_ 2362179326 CondensedWorkState177to192 DDI 172-172;
SG_MUL_VAL_ 2362179326 CondensedWorkState161to176 DDI 171-171;
SG_MUL_VAL_ 2362179326 CondensedWorkState145to160 DDI 170-170;
SG_MUL_VAL_ 2362179326 CondensedWorkState129to144 DDI 169-169;
SG_MUL_VAL_ 2362179326 CondensedWorkState113to128 DDI 168-168;
SG_MUL_VAL_ 2362179326 CondensedWorkState97to112 DDI 167-167;
SG_MUL_VAL_ 2362179326 CondensedWorkState81to96 DDI 166-166;
SG_MUL_VAL_ 2362179326 CondensedWorkState65to80 DDI 165-165;
SG_MUL_VAL_ 2362179326 CondensedWorkState49to64 DDI 164-164;
SG_MUL_VAL_ 2362179326 CondensedWorkState33to48 DDI 163-163;
SG_MUL_VAL_ 2362179326 CondensedWorkState17to32 DDI 162-162;
SG_MUL_VAL_ 2362179326 CondensedWorkState1to16 DDI 161-161;
SG_MUL_VAL_ 2362179326 SectionControlState DDI 160-160;
SG_MUL_VAL_ 2362179326 NumberOfSubUnitsPerSection DDI 159-159;
SG_MUL_VAL_ 2362179326 PrescriptionControlState DDI 158-158;
SG_MUL_VAL_ 2362179326 ConnectorType DDI 157-157;
SG_MUL_VAL_ 2362179326 PhysicalObjectHeight DDI 156-156;
SG_MUL_VAL_ 2362179326 PhysicalObjectWidth DDI 155-155;
SG_MUL_VAL_ 2362179326 PhysicalObjectLength DDI 154-154;
SG_MUL_VAL_ 2362179326 NDVI DDI 153-153;
SG_MUL_VAL_ 2362179326 MinMassPerAreaAppRate DDI 152-152;
SG_MUL_VAL_ 2362179326 AreaPerTimeCapacity DDI 151-151;
SG_MUL_VAL_ 2362179326 FuelConsumptionPerArea DDI 150-150;
SG_MUL_VAL_ 2362179326 FuelConsumptionPerTime DDI 149-149;
SG_MUL_VAL_ 2362179326 TotalFuelConsumption DDI 148-148;
SG_MUL_VAL_ 2362179326 LogCount DDI 147-147;
SG_MUL_VAL_ 2362179326 PitchAngle DDI 146-146;
SG_MUL_VAL_ 2362179326 RollAngle DDI 145-145;
SG_MUL_VAL_ 2362179326 YawAngle DDI 144-144;
SG_MUL_VAL_ 2362179326 ActualValueTimeLatency DDI 143-143;
SG_MUL_VAL_ 2362179326 SetpointTimeLatency DDI 142-142;
SG_MUL_VAL_ 2362179326 WorkState DDI 141-141;
SG_MUL_VAL_ 2362179326 PercentageAppRateSetpoint DDI 140-140;
SG_MUL_VAL_ 2362179326 DeviceCountCapacity DDI 139-139;
SG_MUL_VAL_ 2362179326 DeviceMassCapacity DDI 138-138;
SG_MUL_VAL_ 2362179326 DeviceVolumeCapacity DDI 137-137;
SG_MUL_VAL_ 2362179326 DeviceElementOffsetZ DDI 136-136;
SG_MUL_VAL_ 2362179326 DeviceElementOffsetY DDI 135-135;
SG_MUL_VAL_ 2362179326 DeviceElementOffsetX DDI 134-134;
SG_MUL_VAL_ 2362179326 AuxiliaryValveInvertPorts DDI 133-133;
SG_MUL_VAL_ 2362179326 AuxiliaryValveProgressivRetract DDI 132-132;
SG_MUL_VAL_ 2362179326 AuxiliaryValveProgressivExtend DDI 131-131;
SG_MUL_VAL_ 2362179326 AuxiliaryValveFloatThreshold DDI 130-130;
SG_MUL_VAL_ 2362179326 AuxiliaryValveRampRetractDown DDI 129-129;
SG_MUL_VAL_ 2362179326 AuxiliaryValveRampRetractUp DDI 128-128;
SG_MUL_VAL_ 2362179326 AuxiliaryValveRampExtendDown DDI 127-127;
SG_MUL_VAL_ 2362179326 AuxiliaryRampExtendUp DDI 126-126;
SG_MUL_VAL_ 2362179326 AuxiliaryValveScalingRetract DDI 125-125;
SG_MUL_VAL_ 2362179326 AuxiliaryValveScalingExtend DDI 124-124;
SG_MUL_VAL_ 2362179326 PrdoucDensityVolumePerCount DDI 123-123;
SG_MUL_VAL_ 2362179326 PrdoucDensityMassPerCount DDI 122-122;
SG_MUL_VAL_ 2362179326 PrdoucDensityMassPerArea DDI 121-121;
SG_MUL_VAL_ 2362179326 AccumulatedTimeOutWork DDI 120-120;
SG_MUL_VAL_ 2362179326 AccumulatedTimeInWork DDI 119-119;
SG_MUL_VAL_ 2362179326 AccumulatedDistanceOutWork DDI 118-118;
SG_MUL_VAL_ 2362179326 AccumulatedDistanceInWork DDI 117-117;
SG_MUL_VAL_ 2362179326 AccumulatedArea DDI 116-116;
SG_MUL_VAL_ 2362179326 BaleSize_Max DDI 115-115;
SG_MUL_VAL_ 2362179326 BaleSize_Min DDI 114-114;
SG_MUL_VAL_ 2362179326 BaleSize_Def DDI 113-113;
SG_MUL_VAL_ 2362179326 BaleSize_Act DDI 112-112;
SG_MUL_VAL_ 2362179326 BaleSize_Set DDI 111-111;
SG_MUL_VAL_ 2362179326 BaleHeight_Max DDI 110-110;
SG_MUL_VAL_ 2362179326 BaleHeight_Min DDI 109-109;
SG_MUL_VAL_ 2362179326 BaleHeight_Def DDI 108-108;
SG_MUL_VAL_ 2362179326 BaleHeight_Act DDI 107-107;
SG_MUL_VAL_ 2362179326 BaleHeight_Set DDI 106-106;
SG_MUL_VAL_ 2362179326 BaleWidth_Max DDI 105-105;
SG_MUL_VAL_ 2362179326 BaleWidth_Min DDI 104-104;
SG_MUL_VAL_ 2362179326 BaleWidth_Def DDI 103-103;
SG_MUL_VAL_ 2362179326 BaleWidth_Act DDI 102-102;
SG_MUL_VAL_ 2362179326 BaleWidth_Set DDI 101-101;
SG_MUL_VAL_ 2362179326 DirtMaterialInCropYield DDI 100-100;
SG_MUL_VAL_ 2362179326 MoistureInCropYield DDI 99-99;
SG_MUL_VAL_ 2362179326 CropYieldLoss DDI 98-98;
SG_MUL_VAL_ 2362179326 CropYieldLossCountPerTime DDI 97-97;
SG_MUL_VAL_ 2362179326 CropYieldLossMassPerTime DDI 96-96;
SG_MUL_VAL_ 2362179326 CropYieldLossVolumePerTime DDI 95-95;
SG_MUL_VAL_ 2362179326 CropYieldLossCountPerArea DDI 94-94;
SG_MUL_VAL_ 2362179326 CropYieldLossMassPerArea DDI 93-93;
SG_MUL_VAL_ 2362179326 CropYieldLossVolumePerArea DDI 92-92;
SG_MUL_VAL_ 2362179326 AccumulatedYieldAsCount DDI 91-91;
SG_MUL_VAL_ 2362179326 AccumulatedYieldAsMass DDI 90-90;
SG_MUL_VAL_ 2362179326 AccumulatedYieldAsVolume DDI 89-89;
SG_MUL_VAL_ 2362179326 YieldCountPerTime DDI 88-88;
SG_MUL_VAL_ 2362179326 YieldMassPerTime DDI 87-87;
SG_MUL_VAL_ 2362179326 YieldVolumePerTime DDI 86-86;
SG_MUL_VAL_ 2362179326 YieldCountPerArea DDI 85-85;
SG_MUL_VAL_ 2362179326 YieldMassPerArea DDI 84-84;
SG_MUL_VAL_ 2362179326 YieldVolumePerArea DDI 83-83;
SG_MUL_VAL_ 2362179326 AccumulatedAppAsCount DDI 82-82;
SG_MUL_VAL_ 2362179326 AccumulatedAppAsMass DDI 81-81;
SG_MUL_VAL_ 2362179326 AccumulatedAppAsVolume DDI 80-80;
SG_MUL_VAL_ 2362179326 ContentAsCount_Max DDI 79-79;
SG_MUL_VAL_ 2362179326 ContentAsCount_Act DDI 78-78;
SG_MUL_VAL_ 2362179326 ContentAsCount_Set DDI 77-77;
SG_MUL_VAL_ 2362179326 ContentAsMass_Max DDI 76-76;
SG_MUL_VAL_ 2362179326 ContentAsMass_Act DDI 75-75;
SG_MUL_VAL_ 2362179326 ContentAsMass_Set DDI 74-74;
SG_MUL_VAL_ 2362179326 ContentAsVolume_Max DDI 73-73;
SG_MUL_VAL_ 2362179326 ContentAsVolume_Act DDI 72-72;
SG_MUL_VAL_ 2362179326 ContentAsVolume_Set DDI 71-71;
SG_MUL_VAL_ 2362179326 WorkingWidth_Max DDI 70-70;
SG_MUL_VAL_ 2362179326 WorkingWidth_Min DDI 69-69;
SG_MUL_VAL_ 2362179326 WorkingWidth_Def DDI 68-68;
SG_MUL_VAL_ 2362179326 WorkingWidth_Act DDI 67-67;
SG_MUL_VAL_ 2362179326 WorkingWidth_Set DDI 66-66;
SG_MUL_VAL_ 2362179326 WorkingHeight_Max DDI 65-65;
SG_MUL_VAL_ 2362179326 WorkingHeight_Min DDI 64-64;
SG_MUL_VAL_ 2362179326 WorkingHeight_Def DDI 63-63;
SG_MUL_VAL_ 2362179326 WorkingHeight_Act DDI 62-62;
SG_MUL_VAL_ 2362179326 WorkingHeight_Set DDI 61-61;
SG_MUL_VAL_ 2362179326 SeedingDeph_Max DDI 60-60;
SG_MUL_VAL_ 2362179326 SeedingDeph_Min DDI 59-59;
SG_MUL_VAL_ 2362179326 SeedingDeph_Def DDI 58-58;
SG_MUL_VAL_ 2362179326 SeedingDeph_Act DDI 57-57;
SG_MUL_VAL_ 2362179326 SeedingDeph_Set DDI 56-56;
SG_MUL_VAL_ 2362179326 TillageDepth_Max DDI 55-55;
SG_MUL_VAL_ 2362179326 TillageDepth_Min DDI 54-54;
SG_MUL_VAL_ 2362179326 TillageDepth_Def DDI 53-53;
SG_MUL_VAL_ 2362179326 TillageDepth_Act DDI 52-52;
SG_MUL_VAL_ 2362179326 SetTillageDepth_Set DDI 51-51;
SG_MUL_VAL_ 2362179326 AppRateCountPerTime_Max DDI 50-50;
SG_MUL_VAL_ 2362179326 AppRateCountPerTime_Min DDI 49-49;
SG_MUL_VAL_ 2362179326 AppRateCountPerTime_Def DDI 48-48;
SG_MUL_VAL_ 2362179326 AppRateCountPerTime_Act DDI 47-47;
SG_MUL_VAL_ 2362179326 AppRateCountPerTime_Set DDI 46-46;
SG_MUL_VAL_ 2362179326 AppRateMassPerTime_Max DDI 45-45;
SG_MUL_VAL_ 2362179326 AppRateMassPerTime_Min DDI 44-44;
SG_MUL_VAL_ 2362179326 AppRateMassPerTime_Def DDI 43-43;
SG_MUL_VAL_ 2362179326 AppRateMassPerTime_Act DDI 42-42;
SG_MUL_VAL_ 2362179326 AppRateMassPerTime_Set DDI 41-41;
SG_MUL_VAL_ 2362179326 AppRateVolumePerTime_Max DDI 40-40;
SG_MUL_VAL_ 2362179326 AppRateVolumePerTime_Min DDI 39-39;
SG_MUL_VAL_ 2362179326 AppRateVolumePerTime_Def DDI 38-38;
SG_MUL_VAL_ 2362179326 AppRateVolumePerTime_Act DDI 37-37;
SG_MUL_VAL_ 2362179326 AppRateVolumePerTime_Set DDI 36-36;
SG_MUL_VAL_ 2362179326 AppRateVolumePerMass_Max DDI 35-35;
SG_MUL_VAL_ 2362179326 AppRateVolumePerMass_Min DDI 34-34;
SG_MUL_VAL_ 2362179326 AppRateVolumePerMass_Def DDI 33-33;
SG_MUL_VAL_ 2362179326 AppRateVolumePerMass_Act DDI 32-32;
SG_MUL_VAL_ 2362179326 AppRateVolumePerMass_Set DDI 31-31;
SG_MUL_VAL_ 2362179326 AppRateMassPerMass_Max DDI 30-30;
SG_MUL_VAL_ 2362179326 AppRateMassPerMass_Min DDI 29-29;
SG_MUL_VAL_ 2362179326 AppRateMassPerMass_Def DDI 28-28;
SG_MUL_VAL_ 2362179326 AppRateMassPerMass_Act DDI 27-27;
SG_MUL_VAL_ 2362179326 AppRateMassPerMass_Set DDI 26-26;
SG_MUL_VAL_ 2362179326 AppRateVolumePerVolume_Max DDI 25-25;
SG_MUL_VAL_ 2362179326 AppRateVolumePerVolume_Min DDI 24-24;
SG_MUL_VAL_ 2362179326 AppRateVolumePerVolume_Def DDI 23-23;
SG_MUL_VAL_ 2362179326 AppRateVolumePerVolume_Act DDI 22-22;
SG_MUL_VAL_ 2362179326 AppRateVolumePerVolume_Set DDI 21-21;
SG_MUL_VAL_ 2362179326 AppRateDistance_Max DDI 20-20;
SG_MUL_VAL_ 2362179326 AppRateDistance_Min DDI 19-19;
SG_MUL_VAL_ 2362179326 AppRateDistance_Def DDI 18-18;
SG_MUL_VAL_ 2362179326 AppRateDistance_Act DDI 17-17;
SG_MUL_VAL_ 2362179326 SetAppRateDistance_Set DDI 16-16;
SG_MUL_VAL_ 2362179326 AppRateCountPerArea_Max DDI 15-15;
SG_MUL_VAL_ 2362179326 AppRateCountPerArea_Min DDI 14-14;
SG_MUL_VAL_ 2362179326 AppRateCountPerArea_Def DDI 13-13;
SG_MUL_VAL_ 2362179326 AppRateCountPerArea_Act DDI 12-12;
SG_MUL_VAL_ 2362179326 AppRateCountPerArea_Set DDI 11-11;
SG_MUL_VAL_ 2362179326 AppRateMassPerArea_Max DDI 10-10;
SG_MUL_VAL_ 2362179326 AppRateMassPerArea_Min DDI 9-9;
SG_MUL_VAL_ 2362179326 AppRateMassPerArea_Def DDI 8-8;
SG_MUL_VAL_ 2362179326 AppRateMassPerArea_Act DDI 7-7;
SG_MUL_VAL_ 2362179326 AppRateMassPerArea_Set DDI 6-6;
SG_MUL_VAL_ 2362179326 AppRateVolumePerArea_Max DDI 5-5;
SG_MUL_VAL_ 2362179326 AppRateVolumePerArea_Min DDI 4-4;
SG_MUL_VAL_ 2362179326 AppRateVolumePerArea_Def DDI 3-3;
SG_MUL_VAL_ 2362179326 AppRateVolumePerArea_Act DDI 2-2;
SG_MUL_VAL_ 2362179326 AppRateVolumePerArea_Set DDI 1-1;
SG_MUL_VAL_ 2362179326 DataLogDistanceInterval Command 5-5;
SG_MUL_VAL_ 2362179326 DataLogTimeInterval Command 4-4;
SG_MUL_VAL_ 2362179326 StatusBusySaving Command 14-14;
SG_MUL_VAL_ 2362179326 ErrorCodeProcessData2 Command 13-13;
SG_MUL_VAL_ 2362179326 StatusBusyReading Command 14-14;
SG_MUL_VAL_ 2362179326 ErrorCodeProcessData3 Command 13-13;
SG_MUL_VAL_ 2362179326 StatusBusyExecuting Command 14-14;
SG_MUL_VAL_ 2362179326 ErrorCodeProcessData4 Command 13-13;
SG_MUL_VAL_ 2362179326 ErrorCodeProcessData5 Command 13-13;
SG_MUL_VAL_ 2362179326 DestinationElementNumber PeerControlCommand 3-3, 4-4;
SG_MUL_VAL_ 2362179326 ErrorCodeProcessData6 Command 13-13;
SG_MUL_VAL_ 2362179326 ErrorCodeProcessData7 Command 13-13;
SG_MUL_VAL_ 2362179326 ErrorCodeProcessData8 Command 13-13;
SG_MUL_VAL_ 2362179326 NumberOfBooms TechnicalDataMsgType 1-1;
SG_MUL_VAL_ 2362179326 MassUnitCmd DeviceDescriptionMsgType 3-3;
SG_MUL_VAL_ 2362179326 SourceAddressWSM Command 14-14;
SG_MUL_VAL_ 2362179326 VolumeUnitCmd DeviceDescriptionMsgType 3-3;
SG_MUL_VAL_ 2362179326 AreaUnitCmd DeviceDescriptionMsgType 3-3;
SG_MUL_VAL_ 2362179326 DistanceUnitCmd DeviceDescriptionMsgType 3-3;
SG_MUL_VAL_ 2362179326 ErrorCodeObjPool1 DeviceDescriptionMsgType 9-9;
SG_MUL_VAL_ 2362179326 UnitsSystem DeviceDescriptionMsgType 3-3;
SG_MUL_VAL_ 2362179326 ExecutedCommand Command 14-14;
SG_MUL_VAL_ 2362179326 NumberOfSection TechnicalDataMsgType 1-1;
SG_MUL_VAL_ 2362179326 IdentityNumber PeerControlCommand 0-0, 1-1, 3-3, 4-4, 6-21;
SG_MUL_VAL_ 2362179326 ErrorCodeObjPool2 DeviceDescriptionMsgType 9-9;
SG_MUL_VAL_ 2362179326 ForceUnits DeviceDescriptionMsgType 3-3;
SG_MUL_VAL_ 2362179326 ErrorCodeObjPool3 DeviceDescriptionMsgType 9-9;
SG_MUL_VAL_ 2362179326 ErrorCodeObjPool4 DeviceDescriptionMsgType 9-9;
SG_MUL_VAL_ 2362179326 PressureUnits DeviceDescriptionMsgType 3-3;
SG_MUL_VAL_ 2362179326 TemperatureUnits DeviceDescriptionMsgType 3-3;
SG_MUL_VAL_ 2362179326 ManufacturerCode PeerControlCommand 0-0, 1-1, 3-3, 4-4, 6-21;
SG_MUL_VAL_ 2362179326 ECUInstance PeerControlCommand 0-0, 1-1, 3-3, 4-4, 6-21;
SG_MUL_VAL_ 2362179326 FunctionInstance PeerControlCommand 0-0, 1-1, 3-3, 4-4, 6-21;
SG_MUL_VAL_ 2362179326 Function PeerControlCommand 0-0, 1-1, 3-3, 4-4, 6-21;
SG_MUL_VAL_ 2362179326 VehicleSystem2 PeerControlCommand 0-0, 1-1, 3-3, 4-4, 6-21;
SG_MUL_VAL_ 2362179326 VehicleSystemInstance PeerControlCommand 0-0, 1-1, 3-3, 4-4, 6-21;
SG_MUL_VAL_ 2362179326 IndustryGroup PeerControlCommand 0-0, 1-1, 3-3, 4-4, 6-21;
SG_MUL_VAL_ 2362179326 ArbitraryAddressCapable PeerControlCommand 0-0, 1-1, 3-3, 4-4, 6-21;
SG_MUL_VAL_ 2559835902 CommandArbitraryAddressCapable NMControlModeIndicator 0-3, 8-8;
SG_MUL_VAL_ 2559835902 CommandVehicleSystemInstance NMControlModeIndicator 0-3, 8-8;
SG_MUL_VAL_ 2559835902 CommandIndustryGroup NMControlModeIndicator 0-3, 8-8;
SG_MUL_VAL_ 2559835902 CommandVehicleSystem NMControlModeIndicator 0-3, 8-8;
SG_MUL_VAL_ 2559835902 CommandFunction NMControlModeIndicator 0-3, 8-8;
SG_MUL_VAL_ 2559835902 CommandFunctionInstance NMControlModeIndicator 0-3, 8-8;
SG_MUL_VAL_ 2559835902 CommandECUInstance NMControlModeIndicator 0-3, 8-8;
SG_MUL_VAL_ 2559835902 CommandManufacturerCode NMControlModeIndicator 0-3, 8-8;
SG_MUL_VAL_ 2559835902 ArbitraryAddressCapableQualifier NMControlModeIndicator 0-0, 4-4, 8-8;
SG_MUL_VAL_ 2559835902 IndustryGroupQualifierFlag NMControlModeIndicator 0-0, 4-4, 8-8;
SG_MUL_VAL_ 2559835902 VehicleSystemInstanceQualifierFl NMControlModeIndicator 0-0, 4-4, 8-8;
SG_MUL_VAL_ 2559835902 VehicleSystemQualifierFlag NMControlModeIndicator 0-0, 4-4, 8-8;
SG_MUL_VAL_ 2559835902 FunctionQualifierFlag NMControlModeIndicator 0-0, 4-4, 8-8;
SG_MUL_VAL_ 2559835902 FunctionInstanceQualifierFlag NMControlModeIndicator 0-0, 4-4, 8-8;
SG_MUL_VAL_ 2559835902 ECUInstanceQualifierFlag NMControlModeIndicator 0-0, 4-4, 8-8;
SG_MUL_VAL_ 2559835902 ManufacturerCodeQualifierFlag NMControlModeIndicator 0-0, 4-4, 8-8;
